VERSION ""

NS_ :

BS_:

BU_: VCM SCIM IC CCM

BO_ 179 SCIM_02P_C05: 8 SCIM
 SG_ FerryFunctionRequest_ISig_5 : 62|2@1+ (1,0) [0|0] ""  VCM
 SG_ KneelingChangeRequest_ISig_5 : 52|2@1+ (1,0) [0|0] ""  VCM
 SG_ LiftAxle1AutoLiftRequest_ISig_5 : 28|2@1+ (1,0) [0|0] ""  VCM
 SG_ FPBRChangeReq_ISig_5 : 58|2@1+ (1,0) [0|0] ""  VCM
 SG_ LightMode_Status_Ctr_1 : 4|4@1+ (1,0) [0|0] ""  VCM
 SG_ LevelRequest_RollRequest_ISig_5 : 22|3@1+ (1,0) [0|0] ""  VCM
 SG_ AltLoadDistribution_rqst_ISig_5 : 25|3@1+ (1,0) [0|0] ""  VCM
 SG_ LoadDistributionChangeRequest_IS : 60|2@1+ (1,0) [0|0] ""  VCM
 SG_ LiftAxle1LiftPositionRequest_ISi : 10|3@1+ (1,0) [0|0] ""  VCM
 SG_ ReverseWarning_rqst : 2|2@1+ (1,0) [0|0] ""  VCM
 SG_ FerryFunctionSwitchChangeReq_ISi : 54|2@1+ (1,0) [0|0] ""  VCM
 SG_ BackToDriveReq_ISig_5 : 56|2@1+ (1,0) [0|0] ""  VCM
 SG_ FogLightFront_ButtonStatus_1 : 0|2@1+ (1,0) [0|0] ""  VCM
 SG_ LevelRequest_RearAxle_ISig_5 : 19|3@1+ (1,0) [0|0] ""  VCM
 SG_ LiftAxle1DirectControl_ISig_5 : 37|3@1+ (1,0) [0|0] ""  VCM
 SG_ ECSStandByRequest_ISig_5 : 34|3@1+ (1,0) [0|0] ""  VCM
 SG_ LiftAxle2LiftPositionRequest_ISi : 13|3@1+ (1,0) [0|0] ""  VCM
 SG_ FogLightRear_ButtonStatus_1 : 8|2@1+ (1,0) [0|0] ""  VCM
 SG_ LevelStrokeRequest_ISig_5 : 32|2@1+ (1,0) [0|0] ""  VCM
 SG_ RampLevelRequest_ISig_5 : 40|4@1+ (1,0) [0|0] ""  VCM
 SG_ LevelRequest_FrontAxle_ISig_5 : 16|3@1+ (1,0) [0|0] ""  VCM
 SG_ LiftAxle2AutoLiftRequest_ISig_5 : 30|2@1+ (1,0) [0|0] ""  VCM
 SG_ RampLevelStorageRequest_ISig_5 : 44|4@1+ (1,0) [0|0] ""  VCM
 SG_ RideHeightStorageRequest_ISig_5 : 48|4@1+ (1,0) [0|0] ""  VCM

BO_ 2671833752 PhysDiagRespMsg_F2_98_C05: 8 CCM
 SG_ PhysDiagRespSig_F2_98_ISig_5 : 0|64@1+ (1,0) [0|0] ""  VCM

BO_ 2671833730 PhysDiagRespMsg_F2_82_C05: 8 IC
 SG_ PhysDiagRespSig_F2_82_ISig_5 : 0|64@1+ (1,0) [0|0] ""  VCM

BO_ 2671833700 PhysDiagRespMsg_F2_64_C05: 8 IC
 SG_ PhysDiagRespSig_F2_64_ISig_5 : 0|64@1+ (1,0) [0|0] ""  VCM

BO_ 2671833697 PhysDiagRespMsg_F2_61_C05: 8 IC
 SG_ PhysDiagRespSig_F2_61_ISig_5 : 0|64@1+ (1,0) [0|0] ""  VCM

BO_ 2671833664 PhysDiagRespMsg_F2_40_C05: 8 SCIM
 SG_ PhysDiagRespSig_F2_40_ISig_5 : 0|64@1+ (1,0) [0|0] ""  VCM

BO_ 2671810802 PhysDiagReqMsg_98_F2_C05: 8 VCM
 SG_ PhysDiagReqSig_98_F2_ISig_5 : 0|64@1+ (1,0) [0|0] ""  CCM

BO_ 2671805170 PhysDiagReqMsg_82_F2_C05: 8 VCM
 SG_ PhysDiagReqSig_82_F2_ISig_5 : 0|64@1+ (1,0) [0|0] ""  IC

BO_ 2671797490 PhysDiagReqMsg_64_F2_C05: 8 VCM
 SG_ PhysDiagReqSig_64_F2_ISig_5 : 0|64@1+ (1,0) [0|0] ""  IC

BO_ 2671796722 PhysDiagReqMsg_61_F2_C05: 8 VCM
 SG_ PhysDiagReqSig_61_F2_ISig_5 : 0|64@1+ (1,0) [0|0] ""  IC

BO_ 2671788274 PhysDiagReqMsg_40_F2_C05: 8 VCM
 SG_ PhysDiagReqSig_40_F2_ISig_5 : 0|64@1+ (1,0) [0|0] ""  SCIM

BO_ 2633990180 NmAsr_VCM_C05: 1 VCM

BO_ 2633990208 NmAsr_SCIM_C05: 1 SCIM

BO_ 2633990241 NmAsr_IC_C05: 1 IC

BO_ 2633990296 NmAsr_CCM_C05: 1 CCM

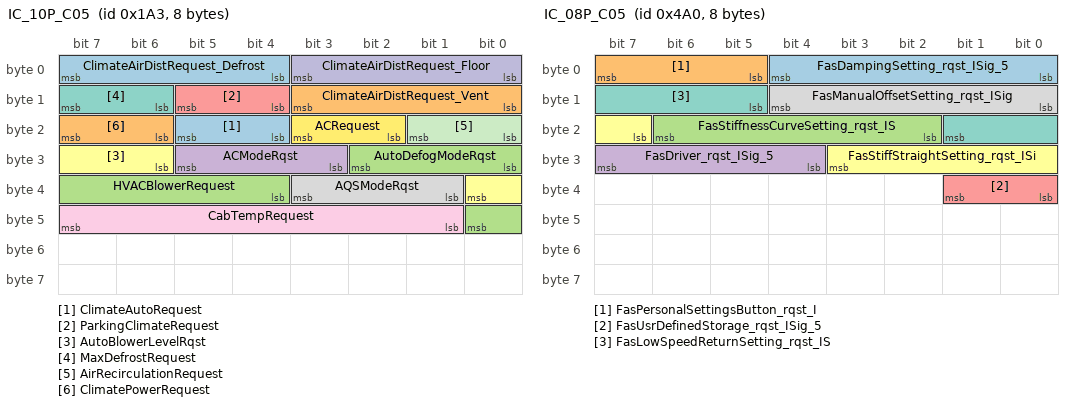
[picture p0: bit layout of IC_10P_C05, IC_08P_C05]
BO_ 419 IC_10P_C05: 8 IC
 SG_ ClimateAutoRequest : 20|2@1+ (1,0) [0|0] ""  CCM
 SG_ ClimateAirDistRequest_Vent : 8|4@1+ (1,0) [0|15] "NotApplicable"  CCM
 SG_ HVACBlowerRequest : 36|5@1+ (1,0) [0|31] "NotApplicable"  CCM
 SG_ ACModeRqst : 27|3@1+ (1,0) [0|0] ""  CCM
 SG_ ParkingClimateRequest : 12|2@1+ (1,0) [0|0] ""  CCM
 SG_ AutoBlowerLevelRqst : 30|3@1+ (1,0) [0|0] ""  CCM
 SG_ MaxDefrostRequest : 14|2@1+ (1,0) [0|0] ""  CCM
 SG_ AQSModeRqst : 33|3@1+ (1,0) [0|0] ""  CCM
 SG_ CabTempRequest : 41|7@1+ (0.5,0) [0|63.5] "DegreeC"  CCM
 SG_ ClimateAirDistRequest_Floor : 0|4@1+ (1,0) [0|15] "NotApplicable"  CCM
 SG_ AirRecirculationRequest : 16|2@1+ (1,0) [0|0] ""  CCM
 SG_ ACRequest : 18|2@1+ (1,0) [0|0] ""  CCM
 SG_ ClimateAirDistRequest_Defrost : 4|4@1+ (1,0) [0|15] "NotApplicable"  CCM
 SG_ ClimatePowerRequest : 22|2@1+ (1,0) [0|0] ""  CCM
 SG_ AutoDefogModeRqst : 24|3@1+ (1,0) [0|0] ""  CCM

BO_ 1457 IC_09S_C05_FCM: 8 VCM
 SG_ IC_09S_C05_FCS : 0|64@1+ (1,0) [0|0] ""  IC

BO_ 1456 IC_09S_C05: 11 IC
 SG_ ECU3VIN_stat : 0|88@1+ (1,0) [0|0] ""  VCM

BO_ 1184 IC_08P_C05: 8 IC
 SG_ FasDampingSetting_rqst_ISig_5 : 0|5@1+ (1,-10) [-10|21] ""  VCM
 SG_ FasPersonalSettingsButton_rqst_I : 5|3@1+ (1,0) [0|0] ""  VCM
 SG_ FasStiffnessCurveSetting_rqst_IS : 18|5@1+ (1,-10) [-10|21] ""  VCM
 SG_ FasDriver_rqst_ISig_5 : 28|4@1+ (1,0) [0|0] ""  VCM
 SG_ FasUsrDefinedStorage_rqst_ISig_5 : 32|2@1+ (1,0) [0|0] ""  VCM
 SG_ FasStiffStraightSetting_rqst_ISi : 23|5@1+ (1,-10) [-10|21] ""  VCM
 SG_ FasLowSpeedReturnSetting_rqst_IS : 13|5@1+ (1,-10) [-10|21] ""  VCM
 SG_ FasManualOffsetSetting_rqst_ISig : 8|5@1+ (1,-10) [-10|21] ""  VCM

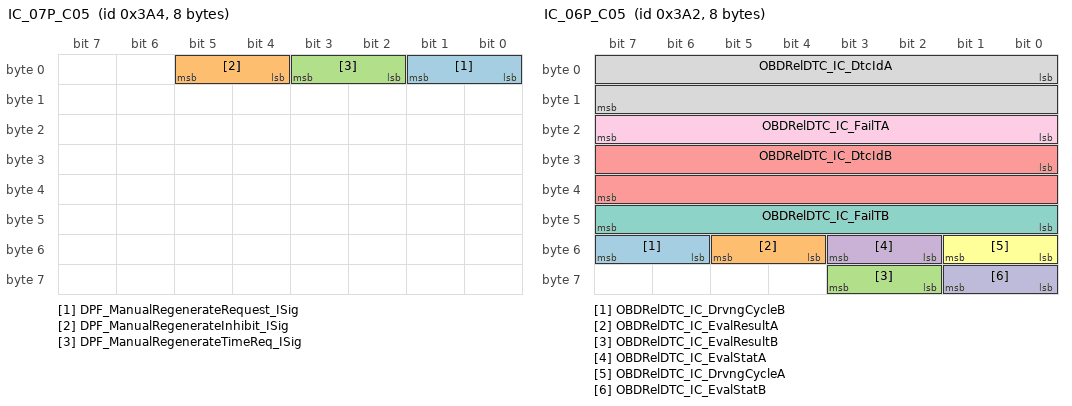
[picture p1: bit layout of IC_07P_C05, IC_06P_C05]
BO_ 932 IC_07P_C05: 8 IC
 SG_ DPF_ManualRegenerateRequest_ISig : 0|2@1+ (1,0) [0|0] ""  VCM
 SG_ DPF_ManualRegenerateInhibit_ISig : 4|2@1+ (1,0) [0|0] ""  VCM
 SG_ DPF_ManualRegenerateTimeReq_ISig : 2|2@1+ (1,0) [0|0] ""  VCM

BO_ 930 IC_06P_C05: 8 IC
 SG_ OBDRelDTC_IC_DrvngCycleB : 54|2@1+ (1,0) [0|0] ""  VCM
 SG_ OBDRelDTC_IC_EvalResultA : 52|2@1+ (1,0) [0|0] ""  VCM
 SG_ OBDRelDTC_IC_EvalResultB : 58|2@1+ (1,0) [0|0] ""  VCM
 SG_ OBDRelDTC_IC_EvalStatA : 50|2@1+ (1,0) [0|0] ""  VCM
 SG_ OBDRelDTC_IC_DtcIdB : 24|16@1+ (1,0) [0|65535] ""  VCM
 SG_ OBDRelDTC_IC_DrvngCycleA : 48|2@1+ (1,0) [0|0] ""  VCM
 SG_ OBDRelDTC_IC_FailTB : 40|8@1+ (1,0) [0|255] ""  VCM
 SG_ OBDRelDTC_IC_DtcIdA : 0|16@1+ (1,0) [0|65535] ""  VCM
 SG_ OBDRelDTC_IC_FailTA : 16|8@1+ (1,0) [0|255] ""  VCM
 SG_ OBDRelDTC_IC_EvalStatB : 56|2@1+ (1,0) [0|0] ""  VCM

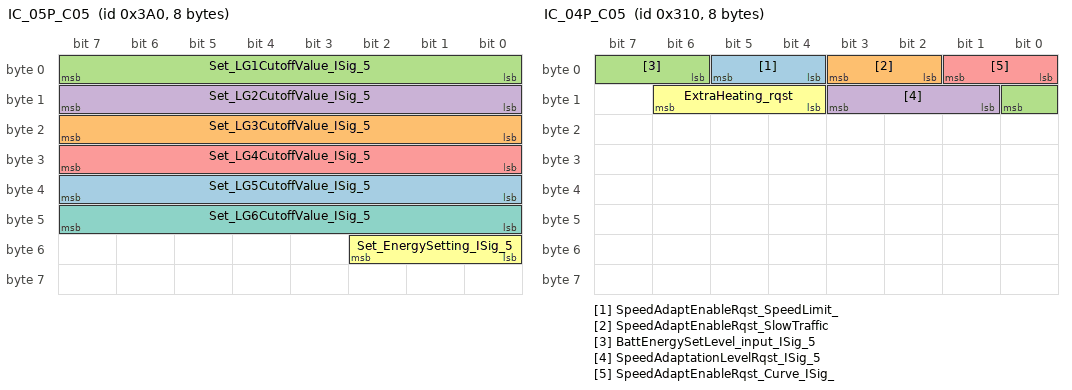
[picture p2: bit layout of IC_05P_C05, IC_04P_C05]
BO_ 928 IC_05P_C05: 8 IC
 SG_ Set_LG5CutoffValue_ISig_5 : 32|8@1+ (1,0) [0|255] "Percent"  VCM
 SG_ Set_LG3CutoffValue_ISig_5 : 16|8@1+ (1,0) [0|255] "Percent"  VCM
 SG_ Set_LG1CutoffValue_ISig_5 : 0|8@1+ (1,0) [0|255] "Percent"  VCM
 SG_ Set_LG2CutoffValue_ISig_5 : 8|8@1+ (1,0) [0|255] "Percent"  VCM
 SG_ Set_LG4CutoffValue_ISig_5 : 24|8@1+ (1,0) [0|255] "Percent"  VCM
 SG_ Set_EnergySetting_ISig_5 : 48|3@1+ (1,0) [0|0] ""  VCM
 SG_ Set_LG6CutoffValue_ISig_5 : 40|8@1+ (1,0) [0|255] "Percent"  VCM

BO_ 784 IC_04P_C05: 8 IC
 SG_ SpeedAdaptEnableRqst_SpeedLimit_ : 4|2@1+ (1,0) [0|0] ""  VCM
 SG_ SpeedAdaptEnableRqst_SlowTraffic : 2|2@1+ (1,0) [0|0] ""  VCM
 SG_ BattEnergySetLevel_input_ISig_5 : 6|3@1+ (1,0) [0|0] ""  VCM
 SG_ SpeedAdaptationLevelRqst_ISig_5 : 9|3@1+ (1,0) [0|0] ""  VCM
 SG_ SpeedAdaptEnableRqst_Curve_ISig_ : 0|2@1+ (1,0) [0|0] ""  VCM
 SG_ ExtraHeating_rqst : 12|3@1+ (1,0) [0|0] ""  CCM,VCM

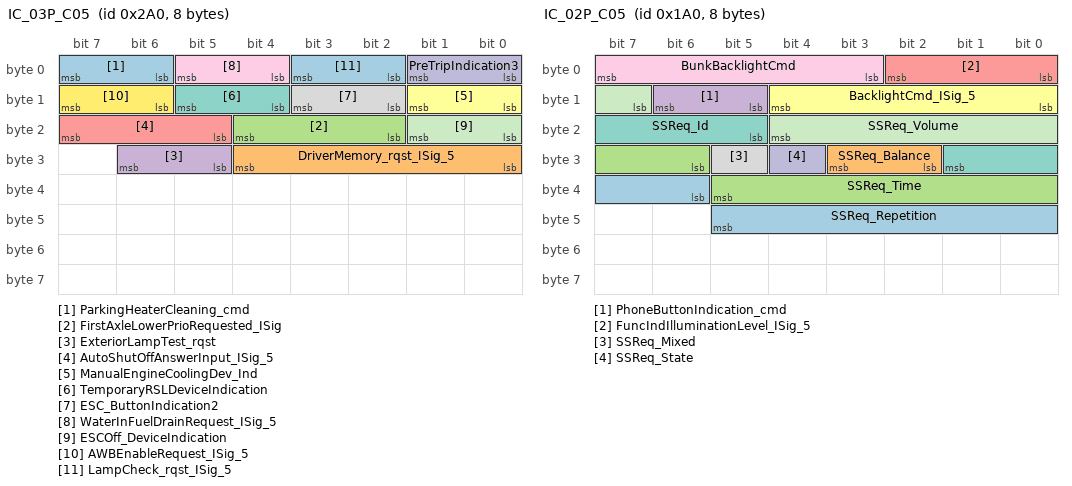
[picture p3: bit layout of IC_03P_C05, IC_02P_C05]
BO_ 672 IC_03P_C05: 8 IC
 SG_ ParkingHeaterCleaning_cmd : 6|2@1+ (1,0) [0|0] ""  VCM,CCM
 SG_ DriverMemory_rqst_ISig_5 : 24|5@1+ (1,0) [0|0] ""  CCM,VCM
 SG_ FirstAxleLowerPrioRequested_ISig : 18|3@1+ (1,0) [0|0] ""  VCM
 SG_ ExteriorLampTest_rqst : 29|2@1+ (1,0) [0|0] ""  VCM
 SG_ AutoShutOffAnswerInput_ISig_5 : 21|3@1+ (1,0) [0|0] ""  VCM
 SG_ ManualEngineCoolingDev_Ind : 8|2@1+ (1,0) [0|0] ""  VCM
 SG_ TemporaryRSLDeviceIndication : 12|2@1+ (1,0) [0|0] ""  VCM
 SG_ ESC_ButtonIndication2 : 10|2@1+ (1,0) [0|0] ""  VCM
 SG_ WaterInFuelDrainRequest_ISig_5 : 4|2@1+ (1,0) [0|0] ""  VCM
 SG_ PreTripIndication3 : 0|2@1+ (1,0) [0|0] ""  VCM
 SG_ ESCOff_DeviceIndication : 16|2@1+ (1,0) [0|0] ""  VCM
 SG_ AWBEnableRequest_ISig_5 : 14|2@1+ (1,0) [0|0] ""  VCM
 SG_ LampCheck_rqst_ISig_5 : 2|2@1+ (1,0) [0|0] ""  VCM

BO_ 416 IC_02P_C05: 8 IC
 SG_ SSReq_Repetition : 38|8@1+ (1,0) [0|255] ""  VCM
 SG_ SSReq_Balance : 26|2@1+ (1,0) [0|0] ""  VCM
 SG_ SSReq_Time : 30|8@1+ (0.1,0) [0|25.5] "s"  VCM
 SG_ PhoneButtonIndication_cmd : 13|2@1+ (1,0) [0|0] ""  VCM
 SG_ FuncIndIlluminationLevel_ISig_5 : 0|3@1+ (1,0) [0|0] ""  VCM
 SG_ BacklightCmd_ISig_5 : 8|5@1+ (1,0) [0|0] ""  VCM
 SG_ SSReq_Id : 21|5@1+ (1,0) [0|31] ""  VCM
 SG_ SSReq_Mixed : 29|1@1+ (1,0) [0|0] ""  VCM
 SG_ BunkBacklightCmd : 3|5@1+ (1,0) [0|0] ""  VCM
 SG_ SSReq_State : 28|1@1+ (1,0) [0|0] ""  VCM
 SG_ SSReq_Volume : 15|6@1+ (1,0) [0|63] ""  VCM

BO_ 211 IC_01P_C05: 8 IC
 SG_ TimeGapBtnStat : 30|2@1+ (1,0) [0|0] ""  VCM
 SG_ ATC_ButtonIndication : 10|2@1+ (1,0) [0|0] ""  VCM
 SG_ PauseOffBtnStat : 0|2@1+ (1,0) [0|0] ""  VCM
 SG_ ABS_ButtonIndication : 18|2@1+ (1,0) [0|0] ""  VCM
 SG_ SW_HeadlightInterrupt_Stat : 32|2@1+ (1,0) [0|0] ""  VCM
 SG_ PBAlertActiveStatus_ISig_5 : 34|3@1+ (1,0) [0|0] ""  VCM
 SG_ EcoRollEnableRequest_ISig_5 : 24|2@1+ (1,0) [0|0] ""  VCM
 SG_ EcoSettingsBtnStat : 22|2@1+ (1,0) [0|0] ""  VCM
 SG_ SkipNextBtnStat : 12|2@1+ (1,0) [0|0] ""  VCM
 SG_ GENSWS_PushButton_7_17_ISig_5 : 53|2@1+ (1,0) [0|0] ""  VCM
 SG_ TCS_ButtonIndication : 6|2@1+ (1,0) [0|0] ""  VCM
 SG_ DHCBtnStat : 16|2@1+ (1,0) [0|0] ""  VCM
 SG_ SW_PushToTalk_BtnStat_6_17_ISig_ : 49|2@1+ (1,0) [0|0] ""  VCM
 SG_ GENSWS_PushButton_7_3_ISig_5 : 51|2@1+ (1,0) [0|0] ""  VCM
 SG_ SWSpdCtrlButtonsStatus6 : 37|4@1+ (1,0) [0|0] ""  VCM
 SG_ PhoneBtnStat : 8|2@1+ (1,0) [0|0] ""  VCM
 SG_ SW_Home_ButtonsStatus_6 : 41|2@1+ (1,0) [0|0] ""  VCM
 SG_ SkipPrevBtnStat : 4|2@1+ (1,0) [0|0] ""  VCM
 SG_ ActivateBtnStat : 26|2@1+ (1,0) [0|0] ""  VCM
 SG_ ResIncrBtnStat : 2|2@1+ (1,0) [0|0] ""  VCM
 SG_ SrcBtnStat : 14|2@1+ (1,0) [0|0] ""  VCM
 SG_ SW_Mute_ButtonStatus_6_ISig_5 : 45|2@1+ (1,0) [0|0] ""  VCM
 SG_ SW_PushToTalk_BtnStat_6_ISig_5 : 43|2@1+ (1,0) [0|0] ""  VCM
 SG_ SetDecrBtnStat : 28|2@1+ (1,0) [0|0] ""  VCM
 SG_ SW_Mute_ButtonStatus_6_3_ISig_5 : 47|2@1+ (1,0) [0|0] ""  VCM
 SG_ MarkerInterruptButtonStatus : 20|2@1+ (1,0) [0|0] ""  VCM

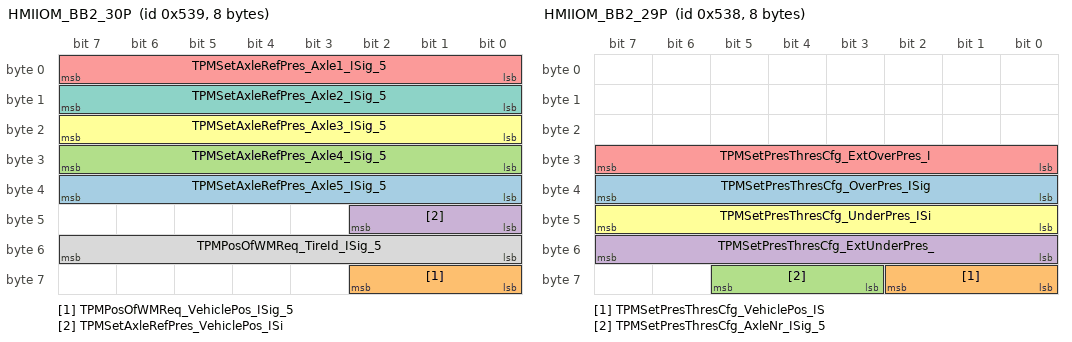
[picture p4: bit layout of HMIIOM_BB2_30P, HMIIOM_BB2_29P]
BO_ 1337 HMIIOM_BB2_30P: 8 IC
 SG_ TPMSetAxleRefPres_Axle5_ISig_5 : 32|8@1+ (10,0) [0|2550] "kPa"  VCM
 SG_ TPMPosOfWMReq_VehiclePos_ISig_5 : 56|3@1+ (1,0) [0|0] ""  VCM
 SG_ TPMSetAxleRefPres_Axle4_ISig_5 : 24|8@1+ (10,0) [0|2550] "kPa"  VCM
 SG_ TPMSetAxleRefPres_VehiclePos_ISi : 40|3@1+ (1,0) [0|0] ""  VCM
 SG_ TPMSetAxleRefPres_Axle1_ISig_5 : 0|8@1+ (10,0) [0|2550] "kPa"  VCM
 SG_ TPMSetAxleRefPres_Axle3_ISig_5 : 16|8@1+ (10,0) [0|2550] "kPa"  VCM
 SG_ TPMSetAxleRefPres_Axle2_ISig_5 : 8|8@1+ (10,0) [0|2550] "kPa"  VCM
 SG_ TPMPosOfWMReq_TireId_ISig_5 : 48|8@1+ (1,0) [0|255] "NotApplicable"  VCM

BO_ 1336 HMIIOM_BB2_29P: 8 IC
 SG_ TPMSetPresThresCfg_OverPres_ISig : 32|8@1+ (1,-125) [-125|130] "Percent"  VCM
 SG_ TPMSetPresThresCfg_VehiclePos_IS : 56|3@1+ (1,0) [0|0] ""  VCM
 SG_ TPMSetPresThresCfg_AxleNr_ISig_5 : 59|3@1+ (1,0) [0|0] ""  VCM
 SG_ TPMSetPresThresCfg_ExtUnderPres_ : 48|8@1+ (1,-125) [-125|130] "Percent"  VCM
 SG_ TPMSetPresThresCfg_ExtOverPres_I : 24|8@1+ (1,-125) [-125|130] "Percent"  VCM
 SG_ TPMSetPresThresCfg_UnderPres_ISi : 40|8@1+ (1,-125) [-125|130] "Percent"  VCM

BO_ 2671964824 DiagUUDTRespMsg1_F2_98_C05: 8 CCM
 SG_ DiagUUDTRespSig_F2_98_ISig_5 : 0|64@1+ (1,0) [0|0] ""  VCM

BO_ 2671964802 DiagUUDTRespMsg1_F2_82_C05: 8 IC
 SG_ DiagUUDTRespSig_F2_82_ISig_5 : 0|64@1+ (1,0) [0|0] ""  VCM

BO_ 2671964772 DiagUUDTRespMsg1_F2_64_C05: 8 IC
 SG_ DiagUUDTRespSig_F2_64_ISig_5 : 0|64@1+ (1,0) [0|0] ""  VCM

BO_ 2671964769 DiagUUDTRespMsg1_F2_61_C05: 8 IC
 SG_ DiagUUDTRespSig_F2_61_ISig_5 : 0|64@1+ (1,0) [0|0] ""  VCM

BO_ 2671964736 DiagUUDTRespMsg1_F2_40_C05: 8 SCIM
 SG_ DiagUUDTRespSig_F2_40_ISig_5 : 0|64@1+ (1,0) [0|0] ""  VCM

BO_ 2671834264 DiagRespMsgForIntTest_F4_98_C05: 8 CCM
 SG_ InternalTesterDiagSig_F4_98 : 0|64@1+ (1,0) [0|0] ""  VCM

BO_ 2671834242 DiagRespMsgForIntTest_F4_82_C05: 8 IC
 SG_ InternalTesterDiagSig_F4_82_ISig : 0|64@1+ (1,0) [0|0] ""  VCM

BO_ 2671834212 DiagRespMsgForIntTest_F4_64_C05: 8 IC
 SG_ InternalTesterDiagSig_F4_64 : 0|64@1+ (1,0) [0|0] ""  VCM

BO_ 2671834209 DiagRespMsgForIntTest_F4_61_C05: 8 IC
 SG_ InternalTesterDiagSig_F4_61 : 0|64@1+ (1,0) [0|0] ""  VCM

BO_ 2671834176 DiagRespMsgForIntTest_F4_40_C05: 8 SCIM
 SG_ InternalTesterDiagSig_F4_40 : 0|64@1+ (1,0) [0|0] ""  VCM

BO_ 2671810804 DiagReqMsgOfIntTest_98_F4_C05: 8 VCM
 SG_ InternalTesterDiagSig_98_F4 : 0|64@1+ (1,0) [0|0] ""  CCM

BO_ 2671805172 DiagReqMsgOfIntTest_82_F4_C05: 8 VCM
 SG_ InternalTesterDiagSig_82_F4_ISig : 0|64@1+ (1,0) [0|0] ""  IC

BO_ 2671797492 DiagReqMsgOfIntTest_64_F4_C05: 8 VCM
 SG_ InternalTesterDiagSig_64_F4 : 0|64@1+ (1,0) [0|0] ""  IC

BO_ 2671796724 DiagReqMsgOfIntTest_61_F4_C05: 8 VCM
 SG_ InternalTesterDiagSig_61_F4 : 0|64@1+ (1,0) [0|0] ""  IC

BO_ 2671788276 DiagReqMsgOfIntTest_40_F4_C05: 8 VCM
 SG_ InternalTesterDiagSig_40_F4 : 0|64@1+ (1,0) [0|0] ""  SCIM

BO_ 1976 Debug8_IC_C05: 8 IC
 SG_ Debug_8_IC : 0|64@1+ (1,0) [0|0] "" Vector__XXX

BO_ 1975 Debug7_IC_C05: 8 IC
 SG_ Debug_7_IC : 0|64@1+ (1,0) [0|0] "" Vector__XXX

BO_ 1966 Debug6_IC_C05: 8 IC
 SG_ Debug_6_IC : 0|64@1+ (1,0) [0|0] "" Vector__XXX

BO_ 1959 Debug5_IC_C05: 8 IC
 SG_ Debug_5_IC : 0|64@1+ (1,0) [0|0] "" Vector__XXX

BO_ 1952 Debug4_IC_C05: 8 IC
 SG_ Debug_4_IC : 0|64@1+ (1,0) [0|0] "" Vector__XXX

BO_ 1945 Debug3_IC_C05: 8 IC
 SG_ Debug_3_IC : 0|64@1+ (1,0) [0|0] "" Vector__XXX

BO_ 1938 Debug2_IC_C05: 8 IC
 SG_ Debug_2_IC : 0|64@1+ (1,0) [0|0] "" Vector__XXX

BO_ 1931 Debug1_IC_C05: 8 Vector__XXX
 SG_ Debug_1_IC : 0|64@1+ (1,0) [0|0] ""  IC

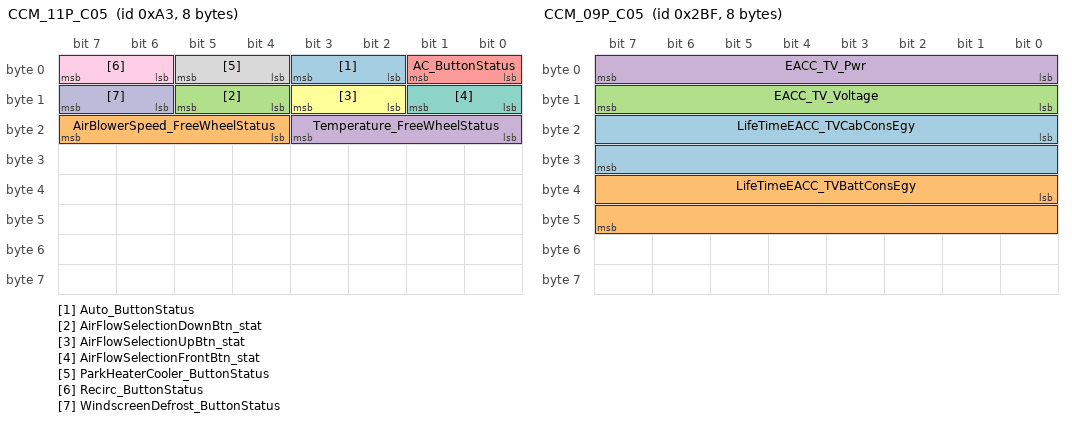
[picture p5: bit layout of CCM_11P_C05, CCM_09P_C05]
BO_ 163 CCM_11P_C05: 8 CCM
 SG_ Auto_ButtonStatus : 2|2@1+ (1,0) [0|0] ""  IC
 SG_ AirBlowerSpeed_FreeWheelStatus : 20|4@1+ (1,0) [0|0] ""  IC
 SG_ AirFlowSelectionDownBtn_stat : 12|2@1+ (1,0) [0|0] ""  IC
 SG_ Temperature_FreeWheelStatus : 16|4@1+ (1,0) [0|0] ""  IC
 SG_ AC_ButtonStatus : 0|2@1+ (1,0) [0|0] ""  IC
 SG_ AirFlowSelectionUpBtn_stat : 10|2@1+ (1,0) [0|0] ""  IC
 SG_ AirFlowSelectionFrontBtn_stat : 8|2@1+ (1,0) [0|0] ""  IC
 SG_ ParkHeaterCooler_ButtonStatus : 4|2@1+ (1,0) [0|0] ""  IC
 SG_ Recirc_ButtonStatus : 6|2@1+ (1,0) [0|0] ""  IC
 SG_ WindscreenDefrost_ButtonStatus : 14|2@1+ (1,0) [0|0] ""  IC

BO_ 1211 CCM_10P_C05: 8 CCM
 SG_ CabClimateFnRqst_FnPower : 0|8@1+ (1,0) [0|255] "Percent"  VCM
 SG_ CabClimateFnRqst_FnNum : 8|4@1+ (1,0) [0|15] "NotApplicable"  VCM

BO_ 703 CCM_09P_C05: 8 CCM
 SG_ LifeTimeEACC_TVCabConsEgy : 16|16@1+ (2.5,0) [0|163837.5] "Wh"  IC
 SG_ LifeTimeEACC_TVBattConsEgy : 32|16@1+ (2.5,0) [0|163837.5] "Wh"  IC
 SG_ EACC_TV_Voltage : 8|8@1+ (5,0) [0|1275] "V"  VCM
 SG_ EACC_TV_Pwr : 0|8@1+ (100,0) [0|25500] "W"  VCM

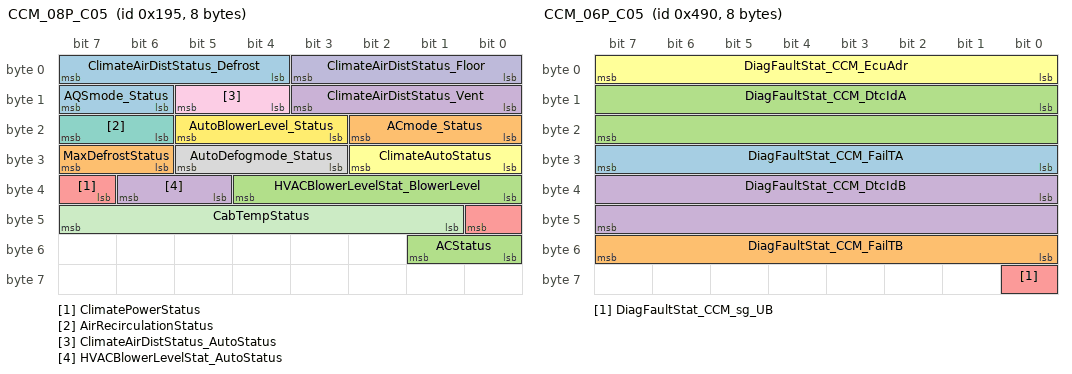
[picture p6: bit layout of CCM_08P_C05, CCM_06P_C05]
BO_ 405 CCM_08P_C05: 8 CCM
 SG_ ClimateAirDistStatus_Defrost : 4|4@1+ (1,0) [0|15] "NotApplicable"  IC
 SG_ ACmode_Status : 16|3@1+ (1,0) [0|0] ""  IC
 SG_ ACStatus : 48|2@1+ (1,0) [0|0] ""  IC
 SG_ ClimateAirDistStatus_Vent : 8|4@1+ (1,0) [0|15] "NotApplicable"  IC
 SG_ ClimatePowerStatus : 39|2@1+ (1,0) [0|0] ""  IC
 SG_ ClimateAutoStatus : 24|3@1+ (1,0) [0|0] ""  IC
 SG_ AirRecirculationStatus : 22|2@1+ (1,0) [0|0] ""  IC
 SG_ AutoDefogmode_Status : 27|3@1+ (1,0) [0|0] ""  IC
 SG_ ClimateAirDistStatus_AutoStatus : 12|2@1+ (1,0) [0|0] ""  IC
 SG_ ClimateAirDistStatus_Floor : 0|4@1+ (1,0) [0|15] "NotApplicable"  IC
 SG_ CabTempStatus : 41|7@1+ (0.5,0) [0|63.5] "DegreeC"  IC
 SG_ AutoBlowerLevel_Status : 19|3@1+ (1,0) [0|0] ""  IC
 SG_ AQSmode_Status : 14|2@1+ (1,0) [0|0] ""  IC
 SG_ MaxDefrostStatus : 30|2@1+ (1,0) [0|0] ""  IC
 SG_ HVACBlowerLevelStat_BlowerLevel : 32|5@1+ (1,0) [0|31] "NotApplicable"  IC
 SG_ HVACBlowerLevelStat_AutoStatus : 37|2@1+ (1,0) [0|0] ""  IC

BO_ 1168 CCM_06P_C05: 8 CCM
 SG_ DiagFaultStat_CCM_FailTA : 24|8@1+ (1,0) [0|255] ""  VCM
 SG_ DiagFaultStat_CCM_FailTB : 48|8@1+ (1,0) [0|255] ""  VCM
 SG_ DiagFaultStat_CCM_DtcIdA : 8|16@1+ (1,0) [0|65535] ""  VCM
 SG_ DiagFaultStat_CCM_DtcIdB : 32|16@1+ (1,0) [0|65535] ""  VCM
 SG_ DiagFaultStat_CCM_sg_UB : 56|1@1+ (1,0) [0|0] ""  VCM
 SG_ DiagFaultStat_CCM_EcuAdr : 0|8@1+ (1,0) [0|255] ""  VCM

BO_ 912 CCM_05P_C05: 8 CCM
 SG_ ParkingClimateAvailability : 13|3@1+ (1,0) [0|0] ""  IC
 SG_ CabTemperature_Status : 0|13@1+ (0.025,-40) [-40|164.775] "DegreeC"  VCM

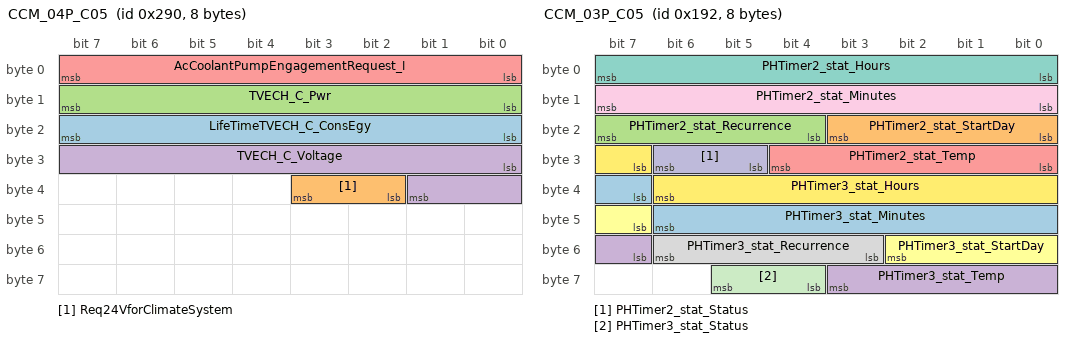
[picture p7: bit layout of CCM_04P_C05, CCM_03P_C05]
BO_ 656 CCM_04P_C05: 8 CCM
 SG_ LifeTimeTVECH_C_ConsEgy : 16|8@1+ (50,0) [0|12750] "Wh"  IC
 SG_ Req24VforClimateSystem : 34|2@1+ (1,0) [0|0] ""  VCM
 SG_ TVECH_C_Pwr : 8|8@1+ (100,0) [0|25500] "W"  VCM
 SG_ TVECH_C_Voltage : 24|10@1+ (1,0) [0|1023] "V"  VCM
 SG_ AcCoolantPumpEngagementRequest_I : 0|8@1+ (0.4,0) [0|102] "Percent"  VCM

BO_ 402 CCM_03P_C05: 8 CCM
 SG_ PHTimer3_stat_Minutes : 39|8@1+ (1,0) [0|255] "min"  VCM
 SG_ PHTimer2_stat_StartDay : 16|4@1+ (1,0) [0|0] ""  VCM
 SG_ PHTimer2_stat_Recurrence : 20|4@1+ (1,0) [0|0] ""  VCM
 SG_ PHTimer3_stat_Temp : 55|5@1+ (1,0) [0|0] ""  VCM
 SG_ PHTimer2_stat_Temp : 24|5@1+ (1,0) [0|0] ""  VCM
 SG_ PHTimer3_stat_StartDay : 47|4@1+ (1,0) [0|0] ""  VCM
 SG_ PHTimer2_stat_Hours : 0|8@1+ (1,0) [0|255] "h"  VCM
 SG_ PHTimer3_stat_Recurrence : 51|4@1+ (1,0) [0|0] ""  VCM
 SG_ PHTimer2_stat_Minutes : 8|8@1+ (1,0) [0|255] "min"  VCM
 SG_ PHTimer2_stat_Status : 29|2@1+ (1,0) [0|0] ""  VCM
 SG_ PHTimer3_stat_Status : 60|2@1+ (1,0) [0|0] ""  VCM
 SG_ PHTimer3_stat_Hours : 31|8@1+ (1,0) [0|255] "h"  VCM

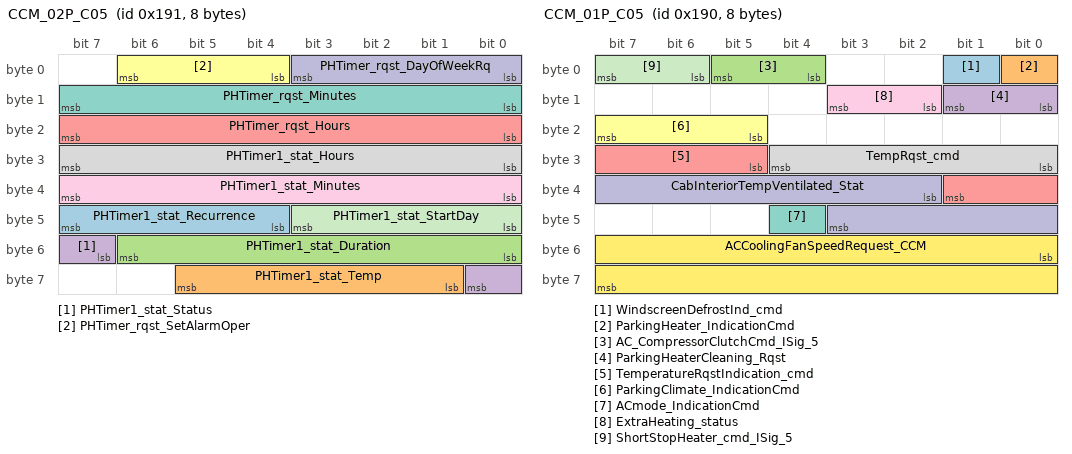
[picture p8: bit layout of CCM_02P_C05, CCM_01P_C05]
BO_ 401 CCM_02P_C05: 8 CCM
 SG_ PHTimer1_stat_Recurrence : 44|4@1+ (1,0) [0|0] ""  VCM
 SG_ PHTimer1_stat_Temp : 57|5@1+ (1,0) [0|0] ""  VCM
 SG_ PHTimer1_stat_Duration : 48|7@1+ (1,0) [0|127] "min"  VCM
 SG_ PHTimer1_stat_Status : 55|2@1+ (1,0) [0|0] ""  VCM
 SG_ PHTimer_rqst_Hours : 16|8@1+ (1,0) [0|255] "h"  VCM
 SG_ PHTimer_rqst_SetAlarmOper : 4|3@1+ (1,0) [0|0] ""  VCM
 SG_ PHTimer_rqst_Minutes : 8|8@1+ (1,0) [0|255] "min"  VCM
 SG_ PHTimer1_stat_Hours : 24|8@1+ (1,0) [0|255] "h"  VCM
 SG_ PHTimer1_stat_Minutes : 32|8@1+ (1,0) [0|255] "min"  VCM
 SG_ PHTimer_rqst_DayOfWeekRq : 0|4@1+ (1,0) [0|0] ""  VCM
 SG_ PHTimer1_stat_StartDay : 40|4@1+ (1,0) [0|0] ""  VCM

BO_ 400 CCM_01P_C05: 8 CCM
 SG_ WindscreenDefrostInd_cmd : 1|1@1+ (1,0) [0|0] ""  VCM
 SG_ ParkingHeater_IndicationCmd : 0|1@1+ (1,0) [0|0] ""  VCM
 SG_ AC_CompressorClutchCmd_ISig_5 : 4|2@1+ (1,0) [0|0] ""  VCM
 SG_ ParkingHeaterCleaning_Rqst : 8|2@1+ (1,0) [0|0] ""  IC,VCM
 SG_ TemperatureRqstIndication_cmd : 29|5@1+ (1,0) [0|0] ""  IC,VCM
 SG_ ParkingClimate_IndicationCmd : 21|3@1+ (1,0) [0|0] ""  VCM,IC
 SG_ ACmode_IndicationCmd : 44|1@1+ (1,0) [0|0] ""  VCM
 SG_ TempRqst_cmd : 24|5@1+ (1,0) [0|0] ""  VCM
 SG_ ExtraHeating_status : 10|2@1+ (1,0) [0|0] ""  IC,VCM
 SG_ CabInteriorTempVentilated_Stat : 34|10@1+ (0.125,-40) [-40|87.875] "DegreeC"  VCM
 SG_ ShortStopHeater_cmd_ISig_5 : 6|2@1+ (1,0) [0|0] ""  VCM
 SG_ ACCoolingFanSpeedRequest_CCM : 48|16@1+ (1,0) [0|65535] "rpm"  VCM

BO_ 1717 AnmMsg_VCM_C05: 8 VCM
 SG_ AnmSig_VCM_CAN05 : 0|32@1+ (1,0) [0|0] ""  IC,CCM,SCIM

BO_ 1718 AnmMsg_SCIM_C05: 8 SCIM
 SG_ AnmSig_SCIM_CAN05 : 0|32@1+ (1,0) [0|0] ""  CCM,VCM,IC

BO_ 1716 AnmMsg_IC_C05: 8 IC
 SG_ AnmSig_IC_CAN05 : 0|32@1+ (1,0) [0|0] ""  SCIM,CCM,VCM

BO_ 1719 AnmMsg_CCM_C05: 8 CCM
 SG_ AnmSig_CCM_CAN05 : 0|32@1+ (1,0) [0|0] ""  VCM,SCIM,IC

CM_ SG_ 401 PHTimer_rqst_Hours "254 Error ; 255 Not available";
CM_ SG_ 401 PHTimer_rqst_Minutes "254 Error ; 255 Not available";
BA_DEF_ BO_  "GenMsgStartDelayTime" INT 0 0;
BA_DEF_ BO_  "GenMsgDelayTime" INT 0 0;
BA_DEF_ BO_  "GenMsgCycleTime" INT 0 0;
BA_DEF_ BO_  "GenMsgSendType" ENUM  "Cyclic","NotUsed","NotUsed","NotUsed","NotUsed","NotUsed","NotUsed","IfActive","NoMsgSendType","NotUsed";
BA_DEF_ SG_  "GenSigStartValue" INT 0 0;
BA_DEF_ SG_  "GenSigCycleTimeActive" INT 0 0;
BA_DEF_ SG_  "GenSigCycleTime" INT 0 0;
BA_DEF_ SG_  "GenSigSendType" ENUM  "Cyclic","OnWrite","OnWriteWithRepetition","OnChange","OnChangeWithRepetition","IfActive","IfActiveWithRepetition","NoSigSendType","NotUsed","NotUsed","NotUsed","NotUsed","NotUsed";
BA_DEF_ BO_  "VFrameFormat" ENUM  "StandardCAN","ExtendedCAN","reserved","J1939PG","reserved","reserved","reserved","reserved","reserved","reserved","reserved","reserved","reserved","reserved","StandardCAN_FD","ExtendedCAN_FD";
BA_DEF_ SG_  "SigType" ENUM  "Default","Range","RangeSigned","ASCII","Discrete","Control","ReferencePGN","DTC","StringDelimiter","StringLength","StringLengthControl";
BA_DEF_ BO_  "NmAsrMessage" ENUM  "No","Yes";
BA_DEF_ SG_  "NeedsUpdateBit" ENUM  "No","Yes";
BA_DEF_ SG_  "MmAnSignal" ENUM  "No","Yes";
BA_DEF_ SG_  "GenSigMaxLatency" INT 0 65535;
BA_DEF_ SG_  "GenSigILSupport" ENUM  "Yes","No";
BA_DEF_ BO_  "GenMsgILSupport" ENUM  "No","Yes";
BA_DEF_ SG_  "E2EProfile" STRING ;
BA_DEF_ SG_  "E2EDataLength" INT 0 65535;
BA_DEF_ SG_  "E2EDataId" INT 0 65535;
BA_DEF_ BO_  "DiagUUDTResponse" ENUM  "No","Yes";
BA_DEF_ BO_  "DiagState" ENUM  "No","Yes";
BA_DEF_ BO_  "DiagResponse" ENUM  "No","Yes";
BA_DEF_ BO_  "DiagRequest" ENUM  "No","Yes";
BA_DEF_ BO_  "DiagConnection" HEX 0 65535;
BA_DEF_ BO_  "CanTpFcFrameId" HEX 0 2147483647;
BA_DEF_ BO_  "CanTpBs" INT 0 255;
BA_DEF_ SG_  "SystemSignalLongSymbol" STRING ;
BA_DEF_REL_ BU_SG_REL_  "GenSigTimeoutTime" INT 0 65535;
BA_DEF_REL_ BU_SG_REL_  "GenSigFirstTimeoutTime" INT 0 65535;
BA_DEF_DEF_  "GenMsgStartDelayTime" 0;
BA_DEF_DEF_  "GenMsgDelayTime" 0;
BA_DEF_DEF_  "GenMsgCycleTime" 0;
BA_DEF_DEF_  "GenMsgSendType" "Cyclic";
BA_DEF_DEF_  "GenSigStartValue" 0;
BA_DEF_DEF_  "GenSigCycleTimeActive" 0;
BA_DEF_DEF_  "GenSigCycleTime" 0;
BA_DEF_DEF_  "GenSigSendType" "Cyclic";
BA_DEF_DEF_  "VFrameFormat" "ExtendedCAN";
BA_DEF_DEF_  "SigType" "Default";
BA_DEF_DEF_  "NmAsrMessage" "No";
BA_DEF_DEF_  "NeedsUpdateBit" "No";
BA_DEF_DEF_  "MmAnSignal" "No";
BA_DEF_DEF_  "GenSigMaxLatency" 0;
BA_DEF_DEF_  "GenSigILSupport" "Yes";
BA_DEF_DEF_  "GenMsgILSupport" "Yes";
BA_DEF_DEF_  "E2EProfile" "none";
BA_DEF_DEF_  "E2EDataLength" 0;
BA_DEF_DEF_  "E2EDataId" 0;
BA_DEF_DEF_  "DiagUUDTResponse" "No";
BA_DEF_DEF_  "DiagState" "No";
BA_DEF_DEF_  "DiagResponse" "No";
BA_DEF_DEF_  "DiagRequest" "No";
BA_DEF_DEF_  "DiagConnection" 0;
BA_DEF_DEF_  "CanTpFcFrameId" 2147483647;
BA_DEF_DEF_  "CanTpBs" 255;
BA_DEF_DEF_REL_ "GenSigTimeoutTime" 0;
BA_DEF_DEF_REL_ "GenSigFirstTimeoutTime" 0;
BA_DEF_DEF_  "SystemSignalLongSymbol" "";
BA_ "VFrameFormat" BO_ 179 0;
BA_ "GenMsgCycleTime" BO_ 179 20;
BA_ "GenMsgStartDelayTime" BO_ 179 5;
BA_ "DiagConnection" BO_ 2671833752 62104;
BA_ "DiagResponse" BO_ 2671833752 1;
BA_ "GenMsgILSupport" BO_ 2671833752 0;
BA_ "GenMsgSendType" BO_ 2671833752 8;
BA_ "DiagConnection" BO_ 2671833730 62082;
BA_ "DiagResponse" BO_ 2671833730 1;
BA_ "GenMsgILSupport" BO_ 2671833730 0;
BA_ "GenMsgSendType" BO_ 2671833730 8;
BA_ "DiagConnection" BO_ 2671833700 62052;
BA_ "DiagResponse" BO_ 2671833700 1;
BA_ "GenMsgILSupport" BO_ 2671833700 0;
BA_ "GenMsgSendType" BO_ 2671833700 8;
BA_ "DiagConnection" BO_ 2671833697 62049;
BA_ "DiagResponse" BO_ 2671833697 1;
BA_ "GenMsgILSupport" BO_ 2671833697 0;
BA_ "GenMsgSendType" BO_ 2671833697 8;
BA_ "DiagConnection" BO_ 2671833664 62016;
BA_ "DiagResponse" BO_ 2671833664 1;
BA_ "GenMsgILSupport" BO_ 2671833664 0;
BA_ "GenMsgSendType" BO_ 2671833664 8;
BA_ "DiagConnection" BO_ 2671810802 62104;
BA_ "DiagRequest" BO_ 2671810802 1;
BA_ "GenMsgILSupport" BO_ 2671810802 0;
BA_ "GenMsgSendType" BO_ 2671810802 8;
BA_ "DiagConnection" BO_ 2671805170 62082;
BA_ "DiagRequest" BO_ 2671805170 1;
BA_ "GenMsgILSupport" BO_ 2671805170 0;
BA_ "GenMsgSendType" BO_ 2671805170 8;
BA_ "DiagConnection" BO_ 2671797490 62052;
BA_ "DiagRequest" BO_ 2671797490 1;
BA_ "GenMsgILSupport" BO_ 2671797490 0;
BA_ "GenMsgSendType" BO_ 2671797490 8;
BA_ "DiagConnection" BO_ 2671796722 62049;
BA_ "DiagRequest" BO_ 2671796722 1;
BA_ "GenMsgILSupport" BO_ 2671796722 0;
BA_ "GenMsgSendType" BO_ 2671796722 8;
BA_ "DiagConnection" BO_ 2671788274 62016;
BA_ "DiagRequest" BO_ 2671788274 1;
BA_ "GenMsgILSupport" BO_ 2671788274 0;
BA_ "GenMsgSendType" BO_ 2671788274 8;
BA_ "GenMsgILSupport" BO_ 2633990180 0;
BA_ "NmAsrMessage" BO_ 2633990180 1;
BA_ "GenMsgSendType" BO_ 2633990180 8;
BA_ "GenMsgILSupport" BO_ 2633990208 0;
BA_ "NmAsrMessage" BO_ 2633990208 1;
BA_ "GenMsgSendType" BO_ 2633990208 8;
BA_ "GenMsgILSupport" BO_ 2633990241 0;
BA_ "NmAsrMessage" BO_ 2633990241 1;
BA_ "GenMsgSendType" BO_ 2633990241 8;
BA_ "GenMsgILSupport" BO_ 2633990296 0;
BA_ "NmAsrMessage" BO_ 2633990296 1;
BA_ "GenMsgSendType" BO_ 2633990296 8;
BA_ "VFrameFormat" BO_ 419 0;
BA_ "GenMsgCycleTime" BO_ 419 50;
BA_ "GenMsgStartDelayTime" BO_ 419 30;
BA_ "GenMsgILSupport" BO_ 1457 0;
BA_ "VFrameFormat" BO_ 1457 0;
BA_ "GenMsgSendType" BO_ 1457 8;
BA_ "CanTpFcFrameId" BO_ 1456 1457;
BA_ "VFrameFormat" BO_ 1456 0;
BA_ "GenMsgSendType" BO_ 1456 8;
BA_ "GenMsgDelayTime" BO_ 1456 1000;
BA_ "VFrameFormat" BO_ 1184 0;
BA_ "GenMsgCycleTime" BO_ 1184 1000;
BA_ "GenMsgStartDelayTime" BO_ 1184 10;
BA_ "VFrameFormat" BO_ 932 0;
BA_ "GenMsgCycleTime" BO_ 932 500;
BA_ "GenMsgStartDelayTime" BO_ 932 180;
BA_ "VFrameFormat" BO_ 930 0;
BA_ "GenMsgCycleTime" BO_ 930 500;
BA_ "GenMsgStartDelayTime" BO_ 930 135;
BA_ "VFrameFormat" BO_ 928 0;
BA_ "GenMsgCycleTime" BO_ 928 500;
BA_ "GenMsgStartDelayTime" BO_ 928 20;
BA_ "VFrameFormat" BO_ 784 0;
BA_ "GenMsgCycleTime" BO_ 784 200;
BA_ "GenMsgStartDelayTime" BO_ 784 50;
BA_ "VFrameFormat" BO_ 672 0;
BA_ "GenMsgCycleTime" BO_ 672 100;
BA_ "GenMsgStartDelayTime" BO_ 672 15;
BA_ "VFrameFormat" BO_ 416 0;
BA_ "GenMsgCycleTime" BO_ 416 50;
BA_ "GenMsgStartDelayTime" BO_ 416 5;
BA_ "VFrameFormat" BO_ 211 0;
BA_ "GenMsgCycleTime" BO_ 211 20;
BA_ "VFrameFormat" BO_ 1337 0;
BA_ "GenMsgCycleTime" BO_ 1337 500;
BA_ "GenMsgStartDelayTime" BO_ 1337 285;
BA_ "VFrameFormat" BO_ 1336 0;
BA_ "GenMsgCycleTime" BO_ 1336 500;
BA_ "GenMsgStartDelayTime" BO_ 1336 100;
BA_ "DiagConnection" BO_ 2671964824 62104;
BA_ "DiagUUDTResponse" BO_ 2671964824 1;
BA_ "GenMsgILSupport" BO_ 2671964824 0;
BA_ "GenMsgSendType" BO_ 2671964824 8;
BA_ "DiagConnection" BO_ 2671964802 62082;
BA_ "DiagUUDTResponse" BO_ 2671964802 1;
BA_ "GenMsgILSupport" BO_ 2671964802 0;
BA_ "GenMsgSendType" BO_ 2671964802 8;
BA_ "DiagConnection" BO_ 2671964772 62052;
BA_ "DiagUUDTResponse" BO_ 2671964772 1;
BA_ "GenMsgILSupport" BO_ 2671964772 0;
BA_ "GenMsgSendType" BO_ 2671964772 8;
BA_ "DiagConnection" BO_ 2671964769 62049;
BA_ "DiagUUDTResponse" BO_ 2671964769 1;
BA_ "GenMsgILSupport" BO_ 2671964769 0;
BA_ "GenMsgSendType" BO_ 2671964769 8;
BA_ "DiagConnection" BO_ 2671964736 62016;
BA_ "DiagUUDTResponse" BO_ 2671964736 1;
BA_ "GenMsgILSupport" BO_ 2671964736 0;
BA_ "GenMsgSendType" BO_ 2671964736 8;
BA_ "DiagConnection" BO_ 2671834264 62616;
BA_ "DiagResponse" BO_ 2671834264 1;
BA_ "GenMsgILSupport" BO_ 2671834264 0;
BA_ "GenMsgSendType" BO_ 2671834264 8;
BA_ "DiagConnection" BO_ 2671834242 62594;
BA_ "DiagResponse" BO_ 2671834242 1;
BA_ "GenMsgILSupport" BO_ 2671834242 0;
BA_ "GenMsgSendType" BO_ 2671834242 8;
BA_ "DiagConnection" BO_ 2671834212 62564;
BA_ "DiagResponse" BO_ 2671834212 1;
BA_ "GenMsgILSupport" BO_ 2671834212 0;
BA_ "GenMsgSendType" BO_ 2671834212 8;
BA_ "DiagConnection" BO_ 2671834209 62561;
BA_ "DiagResponse" BO_ 2671834209 1;
BA_ "GenMsgILSupport" BO_ 2671834209 0;
BA_ "GenMsgSendType" BO_ 2671834209 8;
BA_ "DiagConnection" BO_ 2671834176 62528;
BA_ "DiagResponse" BO_ 2671834176 1;
BA_ "GenMsgILSupport" BO_ 2671834176 0;
BA_ "GenMsgSendType" BO_ 2671834176 8;
BA_ "DiagConnection" BO_ 2671810804 62616;
BA_ "DiagRequest" BO_ 2671810804 1;
BA_ "GenMsgILSupport" BO_ 2671810804 0;
BA_ "GenMsgSendType" BO_ 2671810804 8;
BA_ "DiagConnection" BO_ 2671805172 62594;
BA_ "DiagRequest" BO_ 2671805172 1;
BA_ "GenMsgILSupport" BO_ 2671805172 0;
BA_ "GenMsgSendType" BO_ 2671805172 8;
BA_ "DiagConnection" BO_ 2671797492 62564;
BA_ "DiagRequest" BO_ 2671797492 1;
BA_ "GenMsgILSupport" BO_ 2671797492 0;
BA_ "GenMsgSendType" BO_ 2671797492 8;
BA_ "DiagConnection" BO_ 2671796724 62561;
BA_ "DiagRequest" BO_ 2671796724 1;
BA_ "GenMsgILSupport" BO_ 2671796724 0;
BA_ "GenMsgSendType" BO_ 2671796724 8;
BA_ "DiagConnection" BO_ 2671788276 62528;
BA_ "DiagRequest" BO_ 2671788276 1;
BA_ "GenMsgILSupport" BO_ 2671788276 0;
BA_ "GenMsgSendType" BO_ 2671788276 8;
BA_ "VFrameFormat" BO_ 1976 0;
BA_ "GenMsgSendType" BO_ 1976 8;
BA_ "VFrameFormat" BO_ 1975 0;
BA_ "GenMsgSendType" BO_ 1975 8;
BA_ "VFrameFormat" BO_ 1966 0;
BA_ "GenMsgSendType" BO_ 1966 8;
BA_ "GenMsgDelayTime" BO_ 1966 40;
BA_ "GenMsgStartDelayTime" BO_ 1966 50;
BA_ "VFrameFormat" BO_ 1959 0;
BA_ "GenMsgSendType" BO_ 1959 8;
BA_ "GenMsgDelayTime" BO_ 1959 40;
BA_ "GenMsgStartDelayTime" BO_ 1959 50;
BA_ "VFrameFormat" BO_ 1952 0;
BA_ "GenMsgSendType" BO_ 1952 8;
BA_ "GenMsgDelayTime" BO_ 1952 40;
BA_ "GenMsgStartDelayTime" BO_ 1952 50;
BA_ "VFrameFormat" BO_ 1945 0;
BA_ "GenMsgSendType" BO_ 1945 8;
BA_ "GenMsgDelayTime" BO_ 1945 40;
BA_ "GenMsgStartDelayTime" BO_ 1945 50;
BA_ "VFrameFormat" BO_ 1938 0;
BA_ "GenMsgSendType" BO_ 1938 8;
BA_ "GenMsgDelayTime" BO_ 1938 40;
BA_ "GenMsgStartDelayTime" BO_ 1938 50;
BA_ "VFrameFormat" BO_ 1931 0;
BA_ "VFrameFormat" BO_ 163 0;
BA_ "GenMsgCycleTime" BO_ 163 20;
BA_ "VFrameFormat" BO_ 1211 0;
BA_ "GenMsgCycleTime" BO_ 1211 1000;
BA_ "GenMsgStartDelayTime" BO_ 1211 270;
BA_ "VFrameFormat" BO_ 703 0;
BA_ "GenMsgCycleTime" BO_ 703 100;
BA_ "GenMsgStartDelayTime" BO_ 703 65;
BA_ "VFrameFormat" BO_ 405 0;
BA_ "GenMsgCycleTime" BO_ 405 50;
BA_ "GenMsgStartDelayTime" BO_ 405 35;
BA_ "VFrameFormat" BO_ 1168 0;
BA_ "GenMsgCycleTime" BO_ 1168 1000;
BA_ "GenMsgDelayTime" BO_ 1168 80;
BA_ "GenMsgStartDelayTime" BO_ 1168 130;
BA_ "VFrameFormat" BO_ 912 0;
BA_ "GenMsgCycleTime" BO_ 912 500;
BA_ "GenMsgStartDelayTime" BO_ 912 75;
BA_ "VFrameFormat" BO_ 656 0;
BA_ "GenMsgCycleTime" BO_ 656 100;
BA_ "GenMsgStartDelayTime" BO_ 656 20;
BA_ "VFrameFormat" BO_ 402 0;
BA_ "GenMsgCycleTime" BO_ 402 50;
BA_ "GenMsgStartDelayTime" BO_ 402 25;
BA_ "VFrameFormat" BO_ 401 0;
BA_ "GenMsgCycleTime" BO_ 401 50;
BA_ "GenMsgStartDelayTime" BO_ 401 15;
BA_ "VFrameFormat" BO_ 400 0;
BA_ "GenMsgCycleTime" BO_ 400 50;
BA_ "GenMsgStartDelayTime" BO_ 400 5;
BA_ "VFrameFormat" BO_ 1717 0;
BA_ "GenMsgCycleTime" BO_ 1717 100;
BA_ "VFrameFormat" BO_ 1718 0;
BA_ "GenMsgCycleTime" BO_ 1718 100;
BA_ "VFrameFormat" BO_ 1716 0;
BA_ "GenMsgCycleTime" BO_ 1716 100;
BA_ "VFrameFormat" BO_ 1719 0;
BA_ "GenMsgCycleTime" BO_ 1719 100;
BA_ "GenSigCycleTime" SG_ 179 FerryFunctionRequest_ISig_5 100;
BA_ "GenSigCycleTimeActive" SG_ 179 FerryFunctionRequest_ISig_5 100;
BA_ "GenSigStartValue" SG_ 179 FerryFunctionRequest_ISig_5 3;
BA_ "GenSigMaxLatency" SG_ 179 FerryFunctionRequest_ISig_5 20;
BA_ "GenSigCycleTime" SG_ 179 KneelingChangeRequest_ISig_5 100;
BA_ "GenSigCycleTimeActive" SG_ 179 KneelingChangeRequest_ISig_5 100;
BA_ "GenSigStartValue" SG_ 179 KneelingChangeRequest_ISig_5 3;
BA_ "GenSigMaxLatency" SG_ 179 KneelingChangeRequest_ISig_5 20;
BA_ "GenSigCycleTime" SG_ 179 LiftAxle1AutoLiftRequest_ISig_5 100;
BA_ "GenSigCycleTimeActive" SG_ 179 LiftAxle1AutoLiftRequest_ISig_5 100;
BA_ "GenSigStartValue" SG_ 179 LiftAxle1AutoLiftRequest_ISig_5 3;
BA_ "GenSigMaxLatency" SG_ 179 LiftAxle1AutoLiftRequest_ISig_5 20;
BA_ "GenSigCycleTime" SG_ 179 FPBRChangeReq_ISig_5 100;
BA_ "GenSigCycleTimeActive" SG_ 179 FPBRChangeReq_ISig_5 100;
BA_ "GenSigStartValue" SG_ 179 FPBRChangeReq_ISig_5 3;
BA_ "GenSigMaxLatency" SG_ 179 FPBRChangeReq_ISig_5 20;
BA_ "GenSigCycleTime" SG_ 179 LightMode_Status_Ctr_1 100;
BA_ "GenSigCycleTimeActive" SG_ 179 LightMode_Status_Ctr_1 100;
BA_ "GenSigStartValue" SG_ 179 LightMode_Status_Ctr_1 15;
BA_ "GenSigMaxLatency" SG_ 179 LightMode_Status_Ctr_1 20;
BA_ "GenSigCycleTime" SG_ 179 LevelRequest_RollRequest_ISig_5 100;
BA_ "GenSigCycleTimeActive" SG_ 179 LevelRequest_RollRequest_ISig_5 100;
BA_ "GenSigStartValue" SG_ 179 LevelRequest_RollRequest_ISig_5 7;
BA_ "GenSigMaxLatency" SG_ 179 LevelRequest_RollRequest_ISig_5 20;
BA_ "GenSigCycleTime" SG_ 179 AltLoadDistribution_rqst_ISig_5 100;
BA_ "GenSigCycleTimeActive" SG_ 179 AltLoadDistribution_rqst_ISig_5 100;
BA_ "GenSigStartValue" SG_ 179 AltLoadDistribution_rqst_ISig_5 7;
BA_ "GenSigMaxLatency" SG_ 179 AltLoadDistribution_rqst_ISig_5 20;
BA_ "GenSigCycleTime" SG_ 179 LoadDistributionChangeRequest_IS 100;
BA_ "GenSigCycleTimeActive" SG_ 179 LoadDistributionChangeRequest_IS 100;
BA_ "GenSigStartValue" SG_ 179 LoadDistributionChangeRequest_IS 3;
BA_ "GenSigMaxLatency" SG_ 179 LoadDistributionChangeRequest_IS 20;
BA_ "SystemSignalLongSymbol" SG_ 179 LoadDistributionChangeRequest_IS "LoadDistributionChangeRequest_ISig_5";
BA_ "GenSigCycleTime" SG_ 179 LiftAxle1LiftPositionRequest_ISi 100;
BA_ "GenSigCycleTimeActive" SG_ 179 LiftAxle1LiftPositionRequest_ISi 100;
BA_ "GenSigStartValue" SG_ 179 LiftAxle1LiftPositionRequest_ISi 7;
BA_ "GenSigMaxLatency" SG_ 179 LiftAxle1LiftPositionRequest_ISi 20;
BA_ "SystemSignalLongSymbol" SG_ 179 LiftAxle1LiftPositionRequest_ISi "LiftAxle1LiftPositionRequest_ISig_5";
BA_ "GenSigCycleTime" SG_ 179 ReverseWarning_rqst 100;
BA_ "GenSigCycleTimeActive" SG_ 179 ReverseWarning_rqst 100;
BA_ "GenSigStartValue" SG_ 179 ReverseWarning_rqst 3;
BA_ "GenSigMaxLatency" SG_ 179 ReverseWarning_rqst 20;
BA_ "GenSigCycleTime" SG_ 179 FerryFunctionSwitchChangeReq_ISi 100;
BA_ "GenSigCycleTimeActive" SG_ 179 FerryFunctionSwitchChangeReq_ISi 100;
BA_ "GenSigStartValue" SG_ 179 FerryFunctionSwitchChangeReq_ISi 3;
BA_ "GenSigMaxLatency" SG_ 179 FerryFunctionSwitchChangeReq_ISi 20;
BA_ "SystemSignalLongSymbol" SG_ 179 FerryFunctionSwitchChangeReq_ISi "FerryFunctionSwitchChangeReq_ISig_5";
BA_ "GenSigCycleTime" SG_ 179 BackToDriveReq_ISig_5 100;
BA_ "GenSigCycleTimeActive" SG_ 179 BackToDriveReq_ISig_5 100;
BA_ "GenSigStartValue" SG_ 179 BackToDriveReq_ISig_5 3;
BA_ "GenSigMaxLatency" SG_ 179 BackToDriveReq_ISig_5 20;
BA_ "GenSigCycleTime" SG_ 179 FogLightFront_ButtonStatus_1 100;
BA_ "GenSigCycleTimeActive" SG_ 179 FogLightFront_ButtonStatus_1 100;
BA_ "GenSigStartValue" SG_ 179 FogLightFront_ButtonStatus_1 3;
BA_ "GenSigMaxLatency" SG_ 179 FogLightFront_ButtonStatus_1 20;
BA_ "GenSigCycleTime" SG_ 179 LevelRequest_RearAxle_ISig_5 100;
BA_ "GenSigCycleTimeActive" SG_ 179 LevelRequest_RearAxle_ISig_5 100;
BA_ "GenSigStartValue" SG_ 179 LevelRequest_RearAxle_ISig_5 7;
BA_ "GenSigMaxLatency" SG_ 179 LevelRequest_RearAxle_ISig_5 20;
BA_ "GenSigCycleTime" SG_ 179 LiftAxle1DirectControl_ISig_5 100;
BA_ "GenSigCycleTimeActive" SG_ 179 LiftAxle1DirectControl_ISig_5 100;
BA_ "GenSigStartValue" SG_ 179 LiftAxle1DirectControl_ISig_5 7;
BA_ "GenSigMaxLatency" SG_ 179 LiftAxle1DirectControl_ISig_5 20;
BA_ "GenSigCycleTime" SG_ 179 ECSStandByRequest_ISig_5 100;
BA_ "GenSigCycleTimeActive" SG_ 179 ECSStandByRequest_ISig_5 100;
BA_ "GenSigStartValue" SG_ 179 ECSStandByRequest_ISig_5 7;
BA_ "GenSigMaxLatency" SG_ 179 ECSStandByRequest_ISig_5 20;
BA_ "GenSigCycleTime" SG_ 179 LiftAxle2LiftPositionRequest_ISi 100;
BA_ "GenSigCycleTimeActive" SG_ 179 LiftAxle2LiftPositionRequest_ISi 100;
BA_ "GenSigStartValue" SG_ 179 LiftAxle2LiftPositionRequest_ISi 7;
BA_ "GenSigMaxLatency" SG_ 179 LiftAxle2LiftPositionRequest_ISi 20;
BA_ "SystemSignalLongSymbol" SG_ 179 LiftAxle2LiftPositionRequest_ISi "LiftAxle2LiftPositionRequest_ISig_5";
BA_ "GenSigCycleTime" SG_ 179 FogLightRear_ButtonStatus_1 100;
BA_ "GenSigCycleTimeActive" SG_ 179 FogLightRear_ButtonStatus_1 100;
BA_ "GenSigStartValue" SG_ 179 FogLightRear_ButtonStatus_1 3;
BA_ "GenSigMaxLatency" SG_ 179 FogLightRear_ButtonStatus_1 20;
BA_ "GenSigCycleTime" SG_ 179 LevelStrokeRequest_ISig_5 100;
BA_ "GenSigCycleTimeActive" SG_ 179 LevelStrokeRequest_ISig_5 100;
BA_ "GenSigStartValue" SG_ 179 LevelStrokeRequest_ISig_5 3;
BA_ "GenSigMaxLatency" SG_ 179 LevelStrokeRequest_ISig_5 20;
BA_ "GenSigCycleTime" SG_ 179 RampLevelRequest_ISig_5 100;
BA_ "GenSigCycleTimeActive" SG_ 179 RampLevelRequest_ISig_5 100;
BA_ "GenSigStartValue" SG_ 179 RampLevelRequest_ISig_5 15;
BA_ "GenSigMaxLatency" SG_ 179 RampLevelRequest_ISig_5 20;
BA_ "GenSigCycleTime" SG_ 179 LevelRequest_FrontAxle_ISig_5 100;
BA_ "GenSigCycleTimeActive" SG_ 179 LevelRequest_FrontAxle_ISig_5 100;
BA_ "GenSigStartValue" SG_ 179 LevelRequest_FrontAxle_ISig_5 7;
BA_ "GenSigMaxLatency" SG_ 179 LevelRequest_FrontAxle_ISig_5 20;
BA_ "GenSigCycleTime" SG_ 179 LiftAxle2AutoLiftRequest_ISig_5 100;
BA_ "GenSigCycleTimeActive" SG_ 179 LiftAxle2AutoLiftRequest_ISig_5 100;
BA_ "GenSigStartValue" SG_ 179 LiftAxle2AutoLiftRequest_ISig_5 3;
BA_ "GenSigMaxLatency" SG_ 179 LiftAxle2AutoLiftRequest_ISig_5 20;
BA_ "GenSigCycleTime" SG_ 179 RampLevelStorageRequest_ISig_5 100;
BA_ "GenSigCycleTimeActive" SG_ 179 RampLevelStorageRequest_ISig_5 100;
BA_ "GenSigStartValue" SG_ 179 RampLevelStorageRequest_ISig_5 15;
BA_ "GenSigMaxLatency" SG_ 179 RampLevelStorageRequest_ISig_5 20;
BA_ "GenSigCycleTime" SG_ 179 RideHeightStorageRequest_ISig_5 100;
BA_ "GenSigCycleTimeActive" SG_ 179 RideHeightStorageRequest_ISig_5 100;
BA_ "GenSigStartValue" SG_ 179 RideHeightStorageRequest_ISig_5 15;
BA_ "GenSigMaxLatency" SG_ 179 RideHeightStorageRequest_ISig_5 20;
BA_ "GenSigSendType" SG_ 2671833752 PhysDiagRespSig_F2_98_ISig_5 7;
BA_ "GenSigSendType" SG_ 2671833730 PhysDiagRespSig_F2_82_ISig_5 7;
BA_ "GenSigSendType" SG_ 2671833700 PhysDiagRespSig_F2_64_ISig_5 7;
BA_ "GenSigSendType" SG_ 2671833697 PhysDiagRespSig_F2_61_ISig_5 7;
BA_ "GenSigSendType" SG_ 2671833664 PhysDiagRespSig_F2_40_ISig_5 7;
BA_ "GenSigSendType" SG_ 2671810802 PhysDiagReqSig_98_F2_ISig_5 7;
BA_ "GenSigSendType" SG_ 2671805170 PhysDiagReqSig_82_F2_ISig_5 7;
BA_ "GenSigSendType" SG_ 2671797490 PhysDiagReqSig_64_F2_ISig_5 7;
BA_ "GenSigSendType" SG_ 2671796722 PhysDiagReqSig_61_F2_ISig_5 7;
BA_ "GenSigSendType" SG_ 2671788274 PhysDiagReqSig_40_F2_ISig_5 7;
BA_ "GenSigCycleTime" SG_ 419 ClimateAutoRequest 100;
BA_ "GenSigCycleTimeActive" SG_ 419 ClimateAutoRequest 100;
BA_ "GenSigStartValue" SG_ 419 ClimateAutoRequest 3;
BA_ "GenSigMaxLatency" SG_ 419 ClimateAutoRequest 50;
BA_ "GenSigCycleTime" SG_ 419 ClimateAirDistRequest_Vent 100;
BA_ "GenSigCycleTimeActive" SG_ 419 ClimateAirDistRequest_Vent 100;
BA_ "GenSigStartValue" SG_ 419 ClimateAirDistRequest_Vent 15;
BA_ "GenSigMaxLatency" SG_ 419 ClimateAirDistRequest_Vent 50;
BA_ "GenSigCycleTime" SG_ 419 HVACBlowerRequest 100;
BA_ "GenSigCycleTimeActive" SG_ 419 HVACBlowerRequest 100;
BA_ "GenSigStartValue" SG_ 419 HVACBlowerRequest 31;
BA_ "GenSigMaxLatency" SG_ 419 HVACBlowerRequest 50;
BA_ "GenSigCycleTime" SG_ 419 ACModeRqst 100;
BA_ "GenSigCycleTimeActive" SG_ 419 ACModeRqst 100;
BA_ "GenSigStartValue" SG_ 419 ACModeRqst 7;
BA_ "GenSigMaxLatency" SG_ 419 ACModeRqst 50;
BA_ "GenSigCycleTime" SG_ 419 ParkingClimateRequest 100;
BA_ "GenSigCycleTimeActive" SG_ 419 ParkingClimateRequest 100;
BA_ "GenSigStartValue" SG_ 419 ParkingClimateRequest 3;
BA_ "GenSigMaxLatency" SG_ 419 ParkingClimateRequest 50;
BA_ "GenSigCycleTime" SG_ 419 AutoBlowerLevelRqst 100;
BA_ "GenSigCycleTimeActive" SG_ 419 AutoBlowerLevelRqst 100;
BA_ "GenSigStartValue" SG_ 419 AutoBlowerLevelRqst 7;
BA_ "GenSigMaxLatency" SG_ 419 AutoBlowerLevelRqst 50;
BA_ "GenSigCycleTime" SG_ 419 MaxDefrostRequest 100;
BA_ "GenSigCycleTimeActive" SG_ 419 MaxDefrostRequest 100;
BA_ "GenSigStartValue" SG_ 419 MaxDefrostRequest 3;
BA_ "GenSigMaxLatency" SG_ 419 MaxDefrostRequest 50;
BA_ "GenSigCycleTime" SG_ 419 AQSModeRqst 100;
BA_ "GenSigCycleTimeActive" SG_ 419 AQSModeRqst 100;
BA_ "GenSigStartValue" SG_ 419 AQSModeRqst 7;
BA_ "GenSigMaxLatency" SG_ 419 AQSModeRqst 50;
BA_ "GenSigCycleTime" SG_ 419 CabTempRequest 100;
BA_ "GenSigCycleTimeActive" SG_ 419 CabTempRequest 100;
BA_ "GenSigStartValue" SG_ 419 CabTempRequest 127;
BA_ "GenSigMaxLatency" SG_ 419 CabTempRequest 50;
BA_ "GenSigCycleTime" SG_ 419 ClimateAirDistRequest_Floor 100;
BA_ "GenSigCycleTimeActive" SG_ 419 ClimateAirDistRequest_Floor 100;
BA_ "GenSigStartValue" SG_ 419 ClimateAirDistRequest_Floor 15;
BA_ "GenSigMaxLatency" SG_ 419 ClimateAirDistRequest_Floor 50;
BA_ "GenSigCycleTime" SG_ 419 AirRecirculationRequest 100;
BA_ "GenSigCycleTimeActive" SG_ 419 AirRecirculationRequest 100;
BA_ "GenSigStartValue" SG_ 419 AirRecirculationRequest 3;
BA_ "GenSigMaxLatency" SG_ 419 AirRecirculationRequest 50;
BA_ "GenSigCycleTime" SG_ 419 ACRequest 100;
BA_ "GenSigCycleTimeActive" SG_ 419 ACRequest 100;
BA_ "GenSigStartValue" SG_ 419 ACRequest 3;
BA_ "GenSigMaxLatency" SG_ 419 ACRequest 50;
BA_ "GenSigCycleTime" SG_ 419 ClimateAirDistRequest_Defrost 100;
BA_ "GenSigCycleTimeActive" SG_ 419 ClimateAirDistRequest_Defrost 100;
BA_ "GenSigStartValue" SG_ 419 ClimateAirDistRequest_Defrost 15;
BA_ "GenSigMaxLatency" SG_ 419 ClimateAirDistRequest_Defrost 50;
BA_ "GenSigCycleTime" SG_ 419 ClimatePowerRequest 100;
BA_ "GenSigCycleTimeActive" SG_ 419 ClimatePowerRequest 100;
BA_ "GenSigStartValue" SG_ 419 ClimatePowerRequest 3;
BA_ "GenSigMaxLatency" SG_ 419 ClimatePowerRequest 50;
BA_ "GenSigCycleTime" SG_ 419 AutoDefogModeRqst 100;
BA_ "GenSigCycleTimeActive" SG_ 419 AutoDefogModeRqst 100;
BA_ "GenSigStartValue" SG_ 419 AutoDefogModeRqst 7;
BA_ "GenSigMaxLatency" SG_ 419 AutoDefogModeRqst 50;
BA_ "GenSigSendType" SG_ 1457 IC_09S_C05_FCS 7;
BA_ "GenSigSendType" SG_ 1456 ECU3VIN_stat 1;
BA_ "GenSigMaxLatency" SG_ 1456 ECU3VIN_stat 1000;
BA_ "GenSigCycleTime" SG_ 1184 FasDampingSetting_rqst_ISig_5 100;
BA_ "GenSigCycleTimeActive" SG_ 1184 FasDampingSetting_rqst_ISig_5 100;
BA_ "GenSigStartValue" SG_ 1184 FasDampingSetting_rqst_ISig_5 31;
BA_ "GenSigMaxLatency" SG_ 1184 FasDampingSetting_rqst_ISig_5 1000;
BA_ "GenSigCycleTime" SG_ 1184 FasPersonalSettingsButton_rqst_I 100;
BA_ "GenSigCycleTimeActive" SG_ 1184 FasPersonalSettingsButton_rqst_I 100;
BA_ "GenSigStartValue" SG_ 1184 FasPersonalSettingsButton_rqst_I 7;
BA_ "GenSigMaxLatency" SG_ 1184 FasPersonalSettingsButton_rqst_I 1000;
BA_ "SystemSignalLongSymbol" SG_ 1184 FasPersonalSettingsButton_rqst_I "FasPersonalSettingsButton_rqst_ISig_5";
BA_ "GenSigCycleTime" SG_ 1184 FasStiffnessCurveSetting_rqst_IS 100;
BA_ "GenSigCycleTimeActive" SG_ 1184 FasStiffnessCurveSetting_rqst_IS 100;
BA_ "GenSigStartValue" SG_ 1184 FasStiffnessCurveSetting_rqst_IS 31;
BA_ "GenSigMaxLatency" SG_ 1184 FasStiffnessCurveSetting_rqst_IS 1000;
BA_ "SystemSignalLongSymbol" SG_ 1184 FasStiffnessCurveSetting_rqst_IS "FasStiffnessCurveSetting_rqst_ISig_5";
BA_ "GenSigCycleTime" SG_ 1184 FasDriver_rqst_ISig_5 100;
BA_ "GenSigCycleTimeActive" SG_ 1184 FasDriver_rqst_ISig_5 100;
BA_ "GenSigStartValue" SG_ 1184 FasDriver_rqst_ISig_5 15;
BA_ "GenSigMaxLatency" SG_ 1184 FasDriver_rqst_ISig_5 1000;
BA_ "GenSigCycleTime" SG_ 1184 FasUsrDefinedStorage_rqst_ISig_5 100;
BA_ "GenSigCycleTimeActive" SG_ 1184 FasUsrDefinedStorage_rqst_ISig_5 100;
BA_ "GenSigStartValue" SG_ 1184 FasUsrDefinedStorage_rqst_ISig_5 3;
BA_ "GenSigMaxLatency" SG_ 1184 FasUsrDefinedStorage_rqst_ISig_5 1000;
BA_ "GenSigCycleTime" SG_ 1184 FasStiffStraightSetting_rqst_ISi 100;
BA_ "GenSigCycleTimeActive" SG_ 1184 FasStiffStraightSetting_rqst_ISi 100;
BA_ "GenSigStartValue" SG_ 1184 FasStiffStraightSetting_rqst_ISi 31;
BA_ "GenSigMaxLatency" SG_ 1184 FasStiffStraightSetting_rqst_ISi 1000;
BA_ "SystemSignalLongSymbol" SG_ 1184 FasStiffStraightSetting_rqst_ISi "FasStiffStraightSetting_rqst_ISig_5";
BA_ "GenSigCycleTime" SG_ 1184 FasLowSpeedReturnSetting_rqst_IS 100;
BA_ "GenSigCycleTimeActive" SG_ 1184 FasLowSpeedReturnSetting_rqst_IS 100;
BA_ "GenSigStartValue" SG_ 1184 FasLowSpeedReturnSetting_rqst_IS 31;
BA_ "GenSigMaxLatency" SG_ 1184 FasLowSpeedReturnSetting_rqst_IS 1000;
BA_ "SystemSignalLongSymbol" SG_ 1184 FasLowSpeedReturnSetting_rqst_IS "FasLowSpeedReturnSetting_rqst_ISig_5";
BA_ "GenSigCycleTime" SG_ 1184 FasManualOffsetSetting_rqst_ISig 100;
BA_ "GenSigCycleTimeActive" SG_ 1184 FasManualOffsetSetting_rqst_ISig 100;
BA_ "GenSigStartValue" SG_ 1184 FasManualOffsetSetting_rqst_ISig 31;
BA_ "GenSigMaxLatency" SG_ 1184 FasManualOffsetSetting_rqst_ISig 1000;
BA_ "SystemSignalLongSymbol" SG_ 1184 FasManualOffsetSetting_rqst_ISig "FasManualOffsetSetting_rqst_ISig_5";
BA_ "GenSigCycleTime" SG_ 932 DPF_ManualRegenerateRequest_ISig 100;
BA_ "GenSigCycleTimeActive" SG_ 932 DPF_ManualRegenerateRequest_ISig 100;
BA_ "GenSigStartValue" SG_ 932 DPF_ManualRegenerateRequest_ISig 3;
BA_ "GenSigMaxLatency" SG_ 932 DPF_ManualRegenerateRequest_ISig 500;
BA_ "SystemSignalLongSymbol" SG_ 932 DPF_ManualRegenerateRequest_ISig "DPF_ManualRegenerateRequest_ISig_5";
BA_ "GenSigCycleTime" SG_ 932 DPF_ManualRegenerateInhibit_ISig 100;
BA_ "GenSigCycleTimeActive" SG_ 932 DPF_ManualRegenerateInhibit_ISig 100;
BA_ "GenSigStartValue" SG_ 932 DPF_ManualRegenerateInhibit_ISig 3;
BA_ "GenSigMaxLatency" SG_ 932 DPF_ManualRegenerateInhibit_ISig 500;
BA_ "SystemSignalLongSymbol" SG_ 932 DPF_ManualRegenerateInhibit_ISig "DPF_ManualRegenerateInhibit_ISig_5";
BA_ "GenSigCycleTime" SG_ 932 DPF_ManualRegenerateTimeReq_ISig 100;
BA_ "GenSigCycleTimeActive" SG_ 932 DPF_ManualRegenerateTimeReq_ISig 100;
BA_ "GenSigStartValue" SG_ 932 DPF_ManualRegenerateTimeReq_ISig 3;
BA_ "GenSigMaxLatency" SG_ 932 DPF_ManualRegenerateTimeReq_ISig 500;
BA_ "SystemSignalLongSymbol" SG_ 932 DPF_ManualRegenerateTimeReq_ISig "DPF_ManualRegenerateTimeReq_ISig_5";
BA_ "GenSigCycleTime" SG_ 930 OBDRelDTC_IC_DrvngCycleB 100;
BA_ "GenSigCycleTimeActive" SG_ 930 OBDRelDTC_IC_DrvngCycleB 100;
BA_ "GenSigStartValue" SG_ 930 OBDRelDTC_IC_DrvngCycleB 3;
BA_ "GenSigMaxLatency" SG_ 930 OBDRelDTC_IC_DrvngCycleB 510;
BA_ "GenSigCycleTime" SG_ 930 OBDRelDTC_IC_EvalResultA 100;
BA_ "GenSigCycleTimeActive" SG_ 930 OBDRelDTC_IC_EvalResultA 100;
BA_ "GenSigStartValue" SG_ 930 OBDRelDTC_IC_EvalResultA 3;
BA_ "GenSigMaxLatency" SG_ 930 OBDRelDTC_IC_EvalResultA 510;
BA_ "GenSigCycleTime" SG_ 930 OBDRelDTC_IC_EvalResultB 100;
BA_ "GenSigCycleTimeActive" SG_ 930 OBDRelDTC_IC_EvalResultB 100;
BA_ "GenSigStartValue" SG_ 930 OBDRelDTC_IC_EvalResultB 3;
BA_ "GenSigMaxLatency" SG_ 930 OBDRelDTC_IC_EvalResultB 510;
BA_ "GenSigCycleTime" SG_ 930 OBDRelDTC_IC_EvalStatA 100;
BA_ "GenSigCycleTimeActive" SG_ 930 OBDRelDTC_IC_EvalStatA 100;
BA_ "GenSigStartValue" SG_ 930 OBDRelDTC_IC_EvalStatA 3;
BA_ "GenSigMaxLatency" SG_ 930 OBDRelDTC_IC_EvalStatA 510;
BA_ "GenSigCycleTime" SG_ 930 OBDRelDTC_IC_DtcIdB 100;
BA_ "GenSigCycleTimeActive" SG_ 930 OBDRelDTC_IC_DtcIdB 100;
BA_ "GenSigMaxLatency" SG_ 930 OBDRelDTC_IC_DtcIdB 510;
BA_ "GenSigCycleTime" SG_ 930 OBDRelDTC_IC_DrvngCycleA 100;
BA_ "GenSigCycleTimeActive" SG_ 930 OBDRelDTC_IC_DrvngCycleA 100;
BA_ "GenSigStartValue" SG_ 930 OBDRelDTC_IC_DrvngCycleA 3;
BA_ "GenSigMaxLatency" SG_ 930 OBDRelDTC_IC_DrvngCycleA 510;
BA_ "GenSigCycleTime" SG_ 930 OBDRelDTC_IC_FailTB 100;
BA_ "GenSigCycleTimeActive" SG_ 930 OBDRelDTC_IC_FailTB 100;
BA_ "GenSigMaxLatency" SG_ 930 OBDRelDTC_IC_FailTB 510;
BA_ "GenSigCycleTime" SG_ 930 OBDRelDTC_IC_DtcIdA 100;
BA_ "GenSigCycleTimeActive" SG_ 930 OBDRelDTC_IC_DtcIdA 100;
BA_ "GenSigMaxLatency" SG_ 930 OBDRelDTC_IC_DtcIdA 510;
BA_ "GenSigCycleTime" SG_ 930 OBDRelDTC_IC_FailTA 100;
BA_ "GenSigCycleTimeActive" SG_ 930 OBDRelDTC_IC_FailTA 100;
BA_ "GenSigMaxLatency" SG_ 930 OBDRelDTC_IC_FailTA 510;
BA_ "GenSigCycleTime" SG_ 930 OBDRelDTC_IC_EvalStatB 100;
BA_ "GenSigCycleTimeActive" SG_ 930 OBDRelDTC_IC_EvalStatB 100;
BA_ "GenSigStartValue" SG_ 930 OBDRelDTC_IC_EvalStatB 3;
BA_ "GenSigMaxLatency" SG_ 930 OBDRelDTC_IC_EvalStatB 510;
BA_ "GenSigCycleTime" SG_ 928 Set_LG5CutoffValue_ISig_5 100;
BA_ "GenSigCycleTimeActive" SG_ 928 Set_LG5CutoffValue_ISig_5 100;
BA_ "GenSigStartValue" SG_ 928 Set_LG5CutoffValue_ISig_5 255;
BA_ "GenSigMaxLatency" SG_ 928 Set_LG5CutoffValue_ISig_5 515;
BA_ "GenSigCycleTime" SG_ 928 Set_LG3CutoffValue_ISig_5 100;
BA_ "GenSigCycleTimeActive" SG_ 928 Set_LG3CutoffValue_ISig_5 100;
BA_ "GenSigStartValue" SG_ 928 Set_LG3CutoffValue_ISig_5 255;
BA_ "GenSigMaxLatency" SG_ 928 Set_LG3CutoffValue_ISig_5 515;
BA_ "GenSigCycleTime" SG_ 928 Set_LG1CutoffValue_ISig_5 100;
BA_ "GenSigCycleTimeActive" SG_ 928 Set_LG1CutoffValue_ISig_5 100;
BA_ "GenSigStartValue" SG_ 928 Set_LG1CutoffValue_ISig_5 255;
BA_ "GenSigMaxLatency" SG_ 928 Set_LG1CutoffValue_ISig_5 515;
BA_ "GenSigCycleTime" SG_ 928 Set_LG2CutoffValue_ISig_5 100;
BA_ "GenSigCycleTimeActive" SG_ 928 Set_LG2CutoffValue_ISig_5 100;
BA_ "GenSigStartValue" SG_ 928 Set_LG2CutoffValue_ISig_5 255;
BA_ "GenSigMaxLatency" SG_ 928 Set_LG2CutoffValue_ISig_5 515;
BA_ "GenSigCycleTime" SG_ 928 Set_LG4CutoffValue_ISig_5 100;
BA_ "GenSigCycleTimeActive" SG_ 928 Set_LG4CutoffValue_ISig_5 100;
BA_ "GenSigStartValue" SG_ 928 Set_LG4CutoffValue_ISig_5 255;
BA_ "GenSigMaxLatency" SG_ 928 Set_LG4CutoffValue_ISig_5 515;
BA_ "GenSigCycleTime" SG_ 928 Set_EnergySetting_ISig_5 100;
BA_ "GenSigCycleTimeActive" SG_ 928 Set_EnergySetting_ISig_5 100;
BA_ "GenSigStartValue" SG_ 928 Set_EnergySetting_ISig_5 7;
BA_ "GenSigMaxLatency" SG_ 928 Set_EnergySetting_ISig_5 515;
BA_ "GenSigCycleTime" SG_ 928 Set_LG6CutoffValue_ISig_5 100;
BA_ "GenSigCycleTimeActive" SG_ 928 Set_LG6CutoffValue_ISig_5 100;
BA_ "GenSigStartValue" SG_ 928 Set_LG6CutoffValue_ISig_5 255;
BA_ "GenSigMaxLatency" SG_ 928 Set_LG6CutoffValue_ISig_5 515;
BA_ "GenSigCycleTime" SG_ 784 SpeedAdaptEnableRqst_SpeedLimit_ 100;
BA_ "GenSigCycleTimeActive" SG_ 784 SpeedAdaptEnableRqst_SpeedLimit_ 100;
BA_ "GenSigStartValue" SG_ 784 SpeedAdaptEnableRqst_SpeedLimit_ 3;
BA_ "GenSigMaxLatency" SG_ 784 SpeedAdaptEnableRqst_SpeedLimit_ 200;
BA_ "SystemSignalLongSymbol" SG_ 784 SpeedAdaptEnableRqst_SpeedLimit_ "SpeedAdaptEnableRqst_SpeedLimit_ISig_5";
BA_ "GenSigCycleTime" SG_ 784 SpeedAdaptEnableRqst_SlowTraffic 100;
BA_ "GenSigCycleTimeActive" SG_ 784 SpeedAdaptEnableRqst_SlowTraffic 100;
BA_ "GenSigStartValue" SG_ 784 SpeedAdaptEnableRqst_SlowTraffic 3;
BA_ "GenSigMaxLatency" SG_ 784 SpeedAdaptEnableRqst_SlowTraffic 200;
BA_ "SystemSignalLongSymbol" SG_ 784 SpeedAdaptEnableRqst_SlowTraffic "SpeedAdaptEnableRqst_SlowTraffic_ISig_5";
BA_ "GenSigCycleTime" SG_ 784 BattEnergySetLevel_input_ISig_5 100;
BA_ "GenSigCycleTimeActive" SG_ 784 BattEnergySetLevel_input_ISig_5 100;
BA_ "GenSigStartValue" SG_ 784 BattEnergySetLevel_input_ISig_5 7;
BA_ "GenSigMaxLatency" SG_ 784 BattEnergySetLevel_input_ISig_5 200;
BA_ "GenSigCycleTime" SG_ 784 SpeedAdaptationLevelRqst_ISig_5 100;
BA_ "GenSigCycleTimeActive" SG_ 784 SpeedAdaptationLevelRqst_ISig_5 100;
BA_ "GenSigStartValue" SG_ 784 SpeedAdaptationLevelRqst_ISig_5 7;
BA_ "GenSigMaxLatency" SG_ 784 SpeedAdaptationLevelRqst_ISig_5 200;
BA_ "GenSigCycleTime" SG_ 784 SpeedAdaptEnableRqst_Curve_ISig_ 100;
BA_ "GenSigCycleTimeActive" SG_ 784 SpeedAdaptEnableRqst_Curve_ISig_ 100;
BA_ "GenSigStartValue" SG_ 784 SpeedAdaptEnableRqst_Curve_ISig_ 3;
BA_ "GenSigMaxLatency" SG_ 784 SpeedAdaptEnableRqst_Curve_ISig_ 200;
BA_ "SystemSignalLongSymbol" SG_ 784 SpeedAdaptEnableRqst_Curve_ISig_ "SpeedAdaptEnableRqst_Curve_ISig_5";
BA_ "GenSigCycleTime" SG_ 784 ExtraHeating_rqst 100;
BA_ "GenSigCycleTimeActive" SG_ 784 ExtraHeating_rqst 100;
BA_ "GenSigStartValue" SG_ 784 ExtraHeating_rqst 7;
BA_ "GenSigMaxLatency" SG_ 784 ExtraHeating_rqst 200;
BA_ "GenSigCycleTime" SG_ 672 ParkingHeaterCleaning_cmd 100;
BA_ "GenSigCycleTimeActive" SG_ 672 ParkingHeaterCleaning_cmd 100;
BA_ "GenSigStartValue" SG_ 672 ParkingHeaterCleaning_cmd 3;
BA_ "GenSigMaxLatency" SG_ 672 ParkingHeaterCleaning_cmd 100;
BA_ "GenSigCycleTime" SG_ 672 DriverMemory_rqst_ISig_5 100;
BA_ "GenSigCycleTimeActive" SG_ 672 DriverMemory_rqst_ISig_5 100;
BA_ "GenSigStartValue" SG_ 672 DriverMemory_rqst_ISig_5 31;
BA_ "GenSigMaxLatency" SG_ 672 DriverMemory_rqst_ISig_5 100;
BA_ "GenSigCycleTime" SG_ 672 FirstAxleLowerPrioRequested_ISig 100;
BA_ "GenSigCycleTimeActive" SG_ 672 FirstAxleLowerPrioRequested_ISig 100;
BA_ "GenSigStartValue" SG_ 672 FirstAxleLowerPrioRequested_ISig 7;
BA_ "GenSigMaxLatency" SG_ 672 FirstAxleLowerPrioRequested_ISig 100;
BA_ "SystemSignalLongSymbol" SG_ 672 FirstAxleLowerPrioRequested_ISig "FirstAxleLowerPrioRequested_ISig_5";
BA_ "GenSigCycleTime" SG_ 672 ExteriorLampTest_rqst 100;
BA_ "GenSigCycleTimeActive" SG_ 672 ExteriorLampTest_rqst 100;
BA_ "GenSigStartValue" SG_ 672 ExteriorLampTest_rqst 3;
BA_ "GenSigCycleTime" SG_ 672 AutoShutOffAnswerInput_ISig_5 100;
BA_ "GenSigCycleTimeActive" SG_ 672 AutoShutOffAnswerInput_ISig_5 100;
BA_ "GenSigStartValue" SG_ 672 AutoShutOffAnswerInput_ISig_5 7;
BA_ "GenSigMaxLatency" SG_ 672 AutoShutOffAnswerInput_ISig_5 100;
BA_ "GenSigCycleTime" SG_ 672 ManualEngineCoolingDev_Ind 100;
BA_ "GenSigCycleTimeActive" SG_ 672 ManualEngineCoolingDev_Ind 100;
BA_ "GenSigStartValue" SG_ 672 ManualEngineCoolingDev_Ind 3;
BA_ "GenSigMaxLatency" SG_ 672 ManualEngineCoolingDev_Ind 100;
BA_ "GenSigCycleTime" SG_ 672 TemporaryRSLDeviceIndication 100;
BA_ "GenSigCycleTimeActive" SG_ 672 TemporaryRSLDeviceIndication 100;
BA_ "GenSigStartValue" SG_ 672 TemporaryRSLDeviceIndication 3;
BA_ "GenSigMaxLatency" SG_ 672 TemporaryRSLDeviceIndication 100;
BA_ "GenSigCycleTime" SG_ 672 ESC_ButtonIndication2 100;
BA_ "GenSigCycleTimeActive" SG_ 672 ESC_ButtonIndication2 100;
BA_ "GenSigStartValue" SG_ 672 ESC_ButtonIndication2 3;
BA_ "GenSigMaxLatency" SG_ 672 ESC_ButtonIndication2 100;
BA_ "GenSigCycleTime" SG_ 672 WaterInFuelDrainRequest_ISig_5 100;
BA_ "GenSigCycleTimeActive" SG_ 672 WaterInFuelDrainRequest_ISig_5 100;
BA_ "GenSigStartValue" SG_ 672 WaterInFuelDrainRequest_ISig_5 3;
BA_ "GenSigMaxLatency" SG_ 672 WaterInFuelDrainRequest_ISig_5 100;
BA_ "GenSigCycleTime" SG_ 672 PreTripIndication3 100;
BA_ "GenSigCycleTimeActive" SG_ 672 PreTripIndication3 100;
BA_ "GenSigStartValue" SG_ 672 PreTripIndication3 3;
BA_ "GenSigMaxLatency" SG_ 672 PreTripIndication3 100;
BA_ "GenSigCycleTime" SG_ 672 ESCOff_DeviceIndication 100;
BA_ "GenSigCycleTimeActive" SG_ 672 ESCOff_DeviceIndication 100;
BA_ "GenSigStartValue" SG_ 672 ESCOff_DeviceIndication 3;
BA_ "GenSigMaxLatency" SG_ 672 ESCOff_DeviceIndication 100;
BA_ "GenSigCycleTime" SG_ 672 AWBEnableRequest_ISig_5 100;
BA_ "GenSigCycleTimeActive" SG_ 672 AWBEnableRequest_ISig_5 100;
BA_ "GenSigStartValue" SG_ 672 AWBEnableRequest_ISig_5 3;
BA_ "GenSigMaxLatency" SG_ 672 AWBEnableRequest_ISig_5 100;
BA_ "GenSigCycleTime" SG_ 672 LampCheck_rqst_ISig_5 100;
BA_ "GenSigCycleTimeActive" SG_ 672 LampCheck_rqst_ISig_5 100;
BA_ "GenSigStartValue" SG_ 672 LampCheck_rqst_ISig_5 3;
BA_ "GenSigMaxLatency" SG_ 672 LampCheck_rqst_ISig_5 100;
BA_ "GenSigCycleTime" SG_ 416 SSReq_Repetition 100;
BA_ "GenSigCycleTimeActive" SG_ 416 SSReq_Repetition 100;
BA_ "GenSigMaxLatency" SG_ 416 SSReq_Repetition 50;
BA_ "GenSigCycleTime" SG_ 416 SSReq_Balance 100;
BA_ "GenSigCycleTimeActive" SG_ 416 SSReq_Balance 100;
BA_ "GenSigMaxLatency" SG_ 416 SSReq_Balance 50;
BA_ "GenSigCycleTime" SG_ 416 SSReq_Time 100;
BA_ "GenSigCycleTimeActive" SG_ 416 SSReq_Time 100;
BA_ "GenSigMaxLatency" SG_ 416 SSReq_Time 50;
BA_ "GenSigCycleTime" SG_ 416 PhoneButtonIndication_cmd 100;
BA_ "GenSigCycleTimeActive" SG_ 416 PhoneButtonIndication_cmd 100;
BA_ "GenSigStartValue" SG_ 416 PhoneButtonIndication_cmd 3;
BA_ "GenSigMaxLatency" SG_ 416 PhoneButtonIndication_cmd 50;
BA_ "GenSigCycleTime" SG_ 416 FuncIndIlluminationLevel_ISig_5 100;
BA_ "GenSigCycleTimeActive" SG_ 416 FuncIndIlluminationLevel_ISig_5 100;
BA_ "GenSigStartValue" SG_ 416 FuncIndIlluminationLevel_ISig_5 1;
BA_ "GenSigMaxLatency" SG_ 416 FuncIndIlluminationLevel_ISig_5 50;
BA_ "GenSigCycleTime" SG_ 416 BacklightCmd_ISig_5 100;
BA_ "GenSigCycleTimeActive" SG_ 416 BacklightCmd_ISig_5 100;
BA_ "GenSigMaxLatency" SG_ 416 BacklightCmd_ISig_5 50;
BA_ "GenSigCycleTime" SG_ 416 SSReq_Id 100;
BA_ "GenSigCycleTimeActive" SG_ 416 SSReq_Id 100;
BA_ "GenSigMaxLatency" SG_ 416 SSReq_Id 50;
BA_ "GenSigCycleTime" SG_ 416 SSReq_Mixed 100;
BA_ "GenSigCycleTimeActive" SG_ 416 SSReq_Mixed 100;
BA_ "GenSigMaxLatency" SG_ 416 SSReq_Mixed 50;
BA_ "GenSigCycleTime" SG_ 416 BunkBacklightCmd 100;
BA_ "GenSigCycleTimeActive" SG_ 416 BunkBacklightCmd 100;
BA_ "GenSigStartValue" SG_ 416 BunkBacklightCmd 31;
BA_ "GenSigMaxLatency" SG_ 416 BunkBacklightCmd 50;
BA_ "GenSigCycleTime" SG_ 416 SSReq_State 100;
BA_ "GenSigCycleTimeActive" SG_ 416 SSReq_State 100;
BA_ "GenSigMaxLatency" SG_ 416 SSReq_State 50;
BA_ "GenSigCycleTime" SG_ 416 SSReq_Volume 100;
BA_ "GenSigCycleTimeActive" SG_ 416 SSReq_Volume 100;
BA_ "GenSigMaxLatency" SG_ 416 SSReq_Volume 50;
BA_ "GenSigCycleTime" SG_ 211 TimeGapBtnStat 100;
BA_ "GenSigCycleTimeActive" SG_ 211 TimeGapBtnStat 100;
BA_ "GenSigStartValue" SG_ 211 TimeGapBtnStat 3;
BA_ "GenSigMaxLatency" SG_ 211 TimeGapBtnStat 30;
BA_ "GenSigCycleTime" SG_ 211 ATC_ButtonIndication 100;
BA_ "GenSigCycleTimeActive" SG_ 211 ATC_ButtonIndication 100;
BA_ "GenSigStartValue" SG_ 211 ATC_ButtonIndication 3;
BA_ "GenSigMaxLatency" SG_ 211 ATC_ButtonIndication 30;
BA_ "GenSigCycleTime" SG_ 211 PauseOffBtnStat 100;
BA_ "GenSigCycleTimeActive" SG_ 211 PauseOffBtnStat 100;
BA_ "GenSigStartValue" SG_ 211 PauseOffBtnStat 3;
BA_ "GenSigMaxLatency" SG_ 211 PauseOffBtnStat 30;
BA_ "GenSigCycleTime" SG_ 211 ABS_ButtonIndication 100;
BA_ "GenSigCycleTimeActive" SG_ 211 ABS_ButtonIndication 100;
BA_ "GenSigStartValue" SG_ 211 ABS_ButtonIndication 3;
BA_ "GenSigMaxLatency" SG_ 211 ABS_ButtonIndication 30;
BA_ "GenSigCycleTime" SG_ 211 SW_HeadlightInterrupt_Stat 100;
BA_ "GenSigCycleTimeActive" SG_ 211 SW_HeadlightInterrupt_Stat 100;
BA_ "GenSigStartValue" SG_ 211 SW_HeadlightInterrupt_Stat 3;
BA_ "GenSigMaxLatency" SG_ 211 SW_HeadlightInterrupt_Stat 30;
BA_ "GenSigCycleTime" SG_ 211 PBAlertActiveStatus_ISig_5 100;
BA_ "GenSigCycleTimeActive" SG_ 211 PBAlertActiveStatus_ISig_5 100;
BA_ "GenSigStartValue" SG_ 211 PBAlertActiveStatus_ISig_5 7;
BA_ "GenSigMaxLatency" SG_ 211 PBAlertActiveStatus_ISig_5 30;
BA_ "GenSigCycleTime" SG_ 211 EcoRollEnableRequest_ISig_5 100;
BA_ "GenSigCycleTimeActive" SG_ 211 EcoRollEnableRequest_ISig_5 100;
BA_ "GenSigStartValue" SG_ 211 EcoRollEnableRequest_ISig_5 3;
BA_ "GenSigMaxLatency" SG_ 211 EcoRollEnableRequest_ISig_5 30;
BA_ "GenSigCycleTime" SG_ 211 EcoSettingsBtnStat 100;
BA_ "GenSigCycleTimeActive" SG_ 211 EcoSettingsBtnStat 100;
BA_ "GenSigStartValue" SG_ 211 EcoSettingsBtnStat 3;
BA_ "GenSigMaxLatency" SG_ 211 EcoSettingsBtnStat 30;
BA_ "GenSigCycleTime" SG_ 211 SkipNextBtnStat 100;
BA_ "GenSigCycleTimeActive" SG_ 211 SkipNextBtnStat 100;
BA_ "GenSigStartValue" SG_ 211 SkipNextBtnStat 3;
BA_ "GenSigMaxLatency" SG_ 211 SkipNextBtnStat 30;
BA_ "GenSigCycleTime" SG_ 211 GENSWS_PushButton_7_17_ISig_5 100;
BA_ "GenSigCycleTimeActive" SG_ 211 GENSWS_PushButton_7_17_ISig_5 100;
BA_ "GenSigStartValue" SG_ 211 GENSWS_PushButton_7_17_ISig_5 3;
BA_ "GenSigCycleTime" SG_ 211 TCS_ButtonIndication 100;
BA_ "GenSigCycleTimeActive" SG_ 211 TCS_ButtonIndication 100;
BA_ "GenSigStartValue" SG_ 211 TCS_ButtonIndication 3;
BA_ "GenSigMaxLatency" SG_ 211 TCS_ButtonIndication 30;
BA_ "GenSigCycleTime" SG_ 211 DHCBtnStat 100;
BA_ "GenSigCycleTimeActive" SG_ 211 DHCBtnStat 100;
BA_ "GenSigStartValue" SG_ 211 DHCBtnStat 3;
BA_ "GenSigMaxLatency" SG_ 211 DHCBtnStat 30;
BA_ "GenSigCycleTime" SG_ 211 SW_PushToTalk_BtnStat_6_17_ISig_ 100;
BA_ "GenSigCycleTimeActive" SG_ 211 SW_PushToTalk_BtnStat_6_17_ISig_ 100;
BA_ "GenSigStartValue" SG_ 211 SW_PushToTalk_BtnStat_6_17_ISig_ 3;
BA_ "SystemSignalLongSymbol" SG_ 211 SW_PushToTalk_BtnStat_6_17_ISig_ "SW_PushToTalk_BtnStat_6_17_ISig_5";
BA_ "GenSigCycleTime" SG_ 211 GENSWS_PushButton_7_3_ISig_5 100;
BA_ "GenSigCycleTimeActive" SG_ 211 GENSWS_PushButton_7_3_ISig_5 100;
BA_ "GenSigStartValue" SG_ 211 GENSWS_PushButton_7_3_ISig_5 3;
BA_ "GenSigCycleTime" SG_ 211 SWSpdCtrlButtonsStatus6 100;
BA_ "GenSigCycleTimeActive" SG_ 211 SWSpdCtrlButtonsStatus6 100;
BA_ "GenSigStartValue" SG_ 211 SWSpdCtrlButtonsStatus6 15;
BA_ "GenSigCycleTime" SG_ 211 PhoneBtnStat 100;
BA_ "GenSigCycleTimeActive" SG_ 211 PhoneBtnStat 100;
BA_ "GenSigStartValue" SG_ 211 PhoneBtnStat 3;
BA_ "GenSigMaxLatency" SG_ 211 PhoneBtnStat 30;
BA_ "GenSigCycleTime" SG_ 211 SW_Home_ButtonsStatus_6 100;
BA_ "GenSigCycleTimeActive" SG_ 211 SW_Home_ButtonsStatus_6 100;
BA_ "GenSigStartValue" SG_ 211 SW_Home_ButtonsStatus_6 3;
BA_ "GenSigCycleTime" SG_ 211 SkipPrevBtnStat 100;
BA_ "GenSigCycleTimeActive" SG_ 211 SkipPrevBtnStat 100;
BA_ "GenSigStartValue" SG_ 211 SkipPrevBtnStat 3;
BA_ "GenSigMaxLatency" SG_ 211 SkipPrevBtnStat 30;
BA_ "GenSigCycleTime" SG_ 211 ActivateBtnStat 100;
BA_ "GenSigCycleTimeActive" SG_ 211 ActivateBtnStat 100;
BA_ "GenSigStartValue" SG_ 211 ActivateBtnStat 3;
BA_ "GenSigMaxLatency" SG_ 211 ActivateBtnStat 30;
BA_ "GenSigCycleTime" SG_ 211 ResIncrBtnStat 100;
BA_ "GenSigCycleTimeActive" SG_ 211 ResIncrBtnStat 100;
BA_ "GenSigStartValue" SG_ 211 ResIncrBtnStat 3;
BA_ "GenSigMaxLatency" SG_ 211 ResIncrBtnStat 30;
BA_ "GenSigCycleTime" SG_ 211 SrcBtnStat 100;
BA_ "GenSigCycleTimeActive" SG_ 211 SrcBtnStat 100;
BA_ "GenSigStartValue" SG_ 211 SrcBtnStat 3;
BA_ "GenSigMaxLatency" SG_ 211 SrcBtnStat 30;
BA_ "GenSigCycleTime" SG_ 211 SW_Mute_ButtonStatus_6_ISig_5 100;
BA_ "GenSigCycleTimeActive" SG_ 211 SW_Mute_ButtonStatus_6_ISig_5 100;
BA_ "GenSigStartValue" SG_ 211 SW_Mute_ButtonStatus_6_ISig_5 3;
BA_ "GenSigCycleTime" SG_ 211 SW_PushToTalk_BtnStat_6_ISig_5 100;
BA_ "GenSigCycleTimeActive" SG_ 211 SW_PushToTalk_BtnStat_6_ISig_5 100;
BA_ "GenSigStartValue" SG_ 211 SW_PushToTalk_BtnStat_6_ISig_5 3;
BA_ "GenSigCycleTime" SG_ 211 SetDecrBtnStat 100;
BA_ "GenSigCycleTimeActive" SG_ 211 SetDecrBtnStat 100;
BA_ "GenSigStartValue" SG_ 211 SetDecrBtnStat 3;
BA_ "GenSigMaxLatency" SG_ 211 SetDecrBtnStat 30;
BA_ "GenSigCycleTime" SG_ 211 SW_Mute_ButtonStatus_6_3_ISig_5 100;
BA_ "GenSigCycleTimeActive" SG_ 211 SW_Mute_ButtonStatus_6_3_ISig_5 100;
BA_ "GenSigStartValue" SG_ 211 SW_Mute_ButtonStatus_6_3_ISig_5 3;
BA_ "GenSigCycleTime" SG_ 211 MarkerInterruptButtonStatus 100;
BA_ "GenSigCycleTimeActive" SG_ 211 MarkerInterruptButtonStatus 100;
BA_ "GenSigStartValue" SG_ 211 MarkerInterruptButtonStatus 3;
BA_ "GenSigMaxLatency" SG_ 211 MarkerInterruptButtonStatus 30;
BA_ "GenSigCycleTime" SG_ 1337 TPMSetAxleRefPres_Axle5_ISig_5 100;
BA_ "GenSigCycleTimeActive" SG_ 1337 TPMSetAxleRefPres_Axle5_ISig_5 100;
BA_ "GenSigStartValue" SG_ 1337 TPMSetAxleRefPres_Axle5_ISig_5 255;
BA_ "GenSigCycleTime" SG_ 1337 TPMPosOfWMReq_VehiclePos_ISig_5 100;
BA_ "GenSigCycleTimeActive" SG_ 1337 TPMPosOfWMReq_VehiclePos_ISig_5 100;
BA_ "GenSigStartValue" SG_ 1337 TPMPosOfWMReq_VehiclePos_ISig_5 7;
BA_ "GenSigCycleTime" SG_ 1337 TPMSetAxleRefPres_Axle4_ISig_5 100;
BA_ "GenSigCycleTimeActive" SG_ 1337 TPMSetAxleRefPres_Axle4_ISig_5 100;
BA_ "GenSigStartValue" SG_ 1337 TPMSetAxleRefPres_Axle4_ISig_5 255;
BA_ "GenSigCycleTime" SG_ 1337 TPMSetAxleRefPres_VehiclePos_ISi 100;
BA_ "GenSigCycleTimeActive" SG_ 1337 TPMSetAxleRefPres_VehiclePos_ISi 100;
BA_ "GenSigStartValue" SG_ 1337 TPMSetAxleRefPres_VehiclePos_ISi 7;
BA_ "SystemSignalLongSymbol" SG_ 1337 TPMSetAxleRefPres_VehiclePos_ISi "TPMSetAxleRefPres_VehiclePos_ISig_5";
BA_ "GenSigCycleTime" SG_ 1337 TPMSetAxleRefPres_Axle1_ISig_5 100;
BA_ "GenSigCycleTimeActive" SG_ 1337 TPMSetAxleRefPres_Axle1_ISig_5 100;
BA_ "GenSigStartValue" SG_ 1337 TPMSetAxleRefPres_Axle1_ISig_5 255;
BA_ "GenSigCycleTime" SG_ 1337 TPMSetAxleRefPres_Axle3_ISig_5 100;
BA_ "GenSigCycleTimeActive" SG_ 1337 TPMSetAxleRefPres_Axle3_ISig_5 100;
BA_ "GenSigStartValue" SG_ 1337 TPMSetAxleRefPres_Axle3_ISig_5 255;
BA_ "GenSigCycleTime" SG_ 1337 TPMSetAxleRefPres_Axle2_ISig_5 100;
BA_ "GenSigCycleTimeActive" SG_ 1337 TPMSetAxleRefPres_Axle2_ISig_5 100;
BA_ "GenSigStartValue" SG_ 1337 TPMSetAxleRefPres_Axle2_ISig_5 255;
BA_ "GenSigCycleTime" SG_ 1337 TPMPosOfWMReq_TireId_ISig_5 100;
BA_ "GenSigCycleTimeActive" SG_ 1337 TPMPosOfWMReq_TireId_ISig_5 100;
BA_ "GenSigCycleTime" SG_ 1336 TPMSetPresThresCfg_OverPres_ISig 100;
BA_ "GenSigCycleTimeActive" SG_ 1336 TPMSetPresThresCfg_OverPres_ISig 100;
BA_ "GenSigStartValue" SG_ 1336 TPMSetPresThresCfg_OverPres_ISig 255;
BA_ "SystemSignalLongSymbol" SG_ 1336 TPMSetPresThresCfg_OverPres_ISig "TPMSetPresThresCfg_OverPres_ISig_5";
BA_ "GenSigCycleTime" SG_ 1336 TPMSetPresThresCfg_VehiclePos_IS 100;
BA_ "GenSigCycleTimeActive" SG_ 1336 TPMSetPresThresCfg_VehiclePos_IS 100;
BA_ "GenSigStartValue" SG_ 1336 TPMSetPresThresCfg_VehiclePos_IS 7;
BA_ "SystemSignalLongSymbol" SG_ 1336 TPMSetPresThresCfg_VehiclePos_IS "TPMSetPresThresCfg_VehiclePos_ISig_5";
BA_ "GenSigCycleTime" SG_ 1336 TPMSetPresThresCfg_AxleNr_ISig_5 100;
BA_ "GenSigCycleTimeActive" SG_ 1336 TPMSetPresThresCfg_AxleNr_ISig_5 100;
BA_ "GenSigStartValue" SG_ 1336 TPMSetPresThresCfg_AxleNr_ISig_5 7;
BA_ "GenSigCycleTime" SG_ 1336 TPMSetPresThresCfg_ExtUnderPres_ 100;
BA_ "GenSigCycleTimeActive" SG_ 1336 TPMSetPresThresCfg_ExtUnderPres_ 100;
BA_ "GenSigStartValue" SG_ 1336 TPMSetPresThresCfg_ExtUnderPres_ 255;
BA_ "SystemSignalLongSymbol" SG_ 1336 TPMSetPresThresCfg_ExtUnderPres_ "TPMSetPresThresCfg_ExtUnderPres_ISig_5";
BA_ "GenSigCycleTime" SG_ 1336 TPMSetPresThresCfg_ExtOverPres_I 100;
BA_ "GenSigCycleTimeActive" SG_ 1336 TPMSetPresThresCfg_ExtOverPres_I 100;
BA_ "GenSigStartValue" SG_ 1336 TPMSetPresThresCfg_ExtOverPres_I 255;
BA_ "SystemSignalLongSymbol" SG_ 1336 TPMSetPresThresCfg_ExtOverPres_I "TPMSetPresThresCfg_ExtOverPres_ISig_5";
BA_ "GenSigCycleTime" SG_ 1336 TPMSetPresThresCfg_UnderPres_ISi 100;
BA_ "GenSigCycleTimeActive" SG_ 1336 TPMSetPresThresCfg_UnderPres_ISi 100;
BA_ "GenSigStartValue" SG_ 1336 TPMSetPresThresCfg_UnderPres_ISi 255;
BA_ "SystemSignalLongSymbol" SG_ 1336 TPMSetPresThresCfg_UnderPres_ISi "TPMSetPresThresCfg_UnderPres_ISig_5";
BA_ "GenSigSendType" SG_ 2671964824 DiagUUDTRespSig_F2_98_ISig_5 7;
BA_ "GenSigSendType" SG_ 2671964802 DiagUUDTRespSig_F2_82_ISig_5 7;
BA_ "GenSigSendType" SG_ 2671964772 DiagUUDTRespSig_F2_64_ISig_5 7;
BA_ "GenSigSendType" SG_ 2671964769 DiagUUDTRespSig_F2_61_ISig_5 7;
BA_ "GenSigSendType" SG_ 2671964736 DiagUUDTRespSig_F2_40_ISig_5 7;
BA_ "GenSigSendType" SG_ 2671834264 InternalTesterDiagSig_F4_98 7;
BA_ "GenSigSendType" SG_ 2671834242 InternalTesterDiagSig_F4_82_ISig 7;
BA_ "SystemSignalLongSymbol" SG_ 2671834242 InternalTesterDiagSig_F4_82_ISig "InternalTesterDiagSig_F4_82_ISig_5";
BA_ "GenSigSendType" SG_ 2671834212 InternalTesterDiagSig_F4_64 7;
BA_ "GenSigSendType" SG_ 2671834209 InternalTesterDiagSig_F4_61 7;
BA_ "GenSigSendType" SG_ 2671834176 InternalTesterDiagSig_F4_40 7;
BA_ "GenSigSendType" SG_ 2671810804 InternalTesterDiagSig_98_F4 7;
BA_ "GenSigSendType" SG_ 2671805172 InternalTesterDiagSig_82_F4_ISig 7;
BA_ "SystemSignalLongSymbol" SG_ 2671805172 InternalTesterDiagSig_82_F4_ISig "InternalTesterDiagSig_82_F4_ISig_5";
BA_ "GenSigSendType" SG_ 2671797492 InternalTesterDiagSig_64_F4 7;
BA_ "GenSigSendType" SG_ 2671796724 InternalTesterDiagSig_61_F4 7;
BA_ "GenSigSendType" SG_ 2671788276 InternalTesterDiagSig_40_F4 7;
BA_ "GenSigSendType" SG_ 1976 Debug_8_IC 1;
BA_ "GenSigSendType" SG_ 1975 Debug_7_IC 1;
BA_ "GenSigSendType" SG_ 1966 Debug_6_IC 1;
BA_ "GenSigSendType" SG_ 1959 Debug_5_IC 1;
BA_ "GenSigSendType" SG_ 1952 Debug_4_IC 1;
BA_ "GenSigSendType" SG_ 1945 Debug_3_IC 1;
BA_ "GenSigSendType" SG_ 1938 Debug_2_IC 1;
BA_ "GenSigSendType" SG_ 1931 Debug_1_IC 1;
BA_ "GenSigCycleTime" SG_ 163 Auto_ButtonStatus 100;
BA_ "GenSigCycleTimeActive" SG_ 163 Auto_ButtonStatus 100;
BA_ "GenSigStartValue" SG_ 163 Auto_ButtonStatus 3;
BA_ "GenSigMaxLatency" SG_ 163 Auto_ButtonStatus 20;
BA_ "GenSigCycleTime" SG_ 163 AirBlowerSpeed_FreeWheelStatus 100;
BA_ "GenSigCycleTimeActive" SG_ 163 AirBlowerSpeed_FreeWheelStatus 100;
BA_ "GenSigStartValue" SG_ 163 AirBlowerSpeed_FreeWheelStatus 15;
BA_ "GenSigMaxLatency" SG_ 163 AirBlowerSpeed_FreeWheelStatus 20;
BA_ "GenSigCycleTime" SG_ 163 AirFlowSelectionDownBtn_stat 100;
BA_ "GenSigCycleTimeActive" SG_ 163 AirFlowSelectionDownBtn_stat 100;
BA_ "GenSigStartValue" SG_ 163 AirFlowSelectionDownBtn_stat 3;
BA_ "GenSigMaxLatency" SG_ 163 AirFlowSelectionDownBtn_stat 20;
BA_ "GenSigCycleTime" SG_ 163 Temperature_FreeWheelStatus 100;
BA_ "GenSigCycleTimeActive" SG_ 163 Temperature_FreeWheelStatus 100;
BA_ "GenSigStartValue" SG_ 163 Temperature_FreeWheelStatus 15;
BA_ "GenSigMaxLatency" SG_ 163 Temperature_FreeWheelStatus 20;
BA_ "GenSigCycleTime" SG_ 163 AC_ButtonStatus 100;
BA_ "GenSigCycleTimeActive" SG_ 163 AC_ButtonStatus 100;
BA_ "GenSigStartValue" SG_ 163 AC_ButtonStatus 3;
BA_ "GenSigMaxLatency" SG_ 163 AC_ButtonStatus 20;
BA_ "GenSigCycleTime" SG_ 163 AirFlowSelectionUpBtn_stat 100;
BA_ "GenSigCycleTimeActive" SG_ 163 AirFlowSelectionUpBtn_stat 100;
BA_ "GenSigStartValue" SG_ 163 AirFlowSelectionUpBtn_stat 3;
BA_ "GenSigMaxLatency" SG_ 163 AirFlowSelectionUpBtn_stat 20;
BA_ "GenSigCycleTime" SG_ 163 AirFlowSelectionFrontBtn_stat 100;
BA_ "GenSigCycleTimeActive" SG_ 163 AirFlowSelectionFrontBtn_stat 100;
BA_ "GenSigStartValue" SG_ 163 AirFlowSelectionFrontBtn_stat 3;
BA_ "GenSigMaxLatency" SG_ 163 AirFlowSelectionFrontBtn_stat 20;
BA_ "GenSigCycleTime" SG_ 163 ParkHeaterCooler_ButtonStatus 100;
BA_ "GenSigCycleTimeActive" SG_ 163 ParkHeaterCooler_ButtonStatus 100;
BA_ "GenSigStartValue" SG_ 163 ParkHeaterCooler_ButtonStatus 3;
BA_ "GenSigMaxLatency" SG_ 163 ParkHeaterCooler_ButtonStatus 20;
BA_ "GenSigCycleTime" SG_ 163 Recirc_ButtonStatus 100;
BA_ "GenSigCycleTimeActive" SG_ 163 Recirc_ButtonStatus 100;
BA_ "GenSigStartValue" SG_ 163 Recirc_ButtonStatus 3;
BA_ "GenSigMaxLatency" SG_ 163 Recirc_ButtonStatus 20;
BA_ "GenSigCycleTime" SG_ 163 WindscreenDefrost_ButtonStatus 100;
BA_ "GenSigCycleTimeActive" SG_ 163 WindscreenDefrost_ButtonStatus 100;
BA_ "GenSigStartValue" SG_ 163 WindscreenDefrost_ButtonStatus 3;
BA_ "GenSigMaxLatency" SG_ 163 WindscreenDefrost_ButtonStatus 20;
BA_ "GenSigCycleTime" SG_ 1211 CabClimateFnRqst_FnPower 100;
BA_ "GenSigCycleTimeActive" SG_ 1211 CabClimateFnRqst_FnPower 100;
BA_ "GenSigStartValue" SG_ 1211 CabClimateFnRqst_FnPower 255;
BA_ "GenSigMaxLatency" SG_ 1211 CabClimateFnRqst_FnPower 1000;
BA_ "GenSigCycleTime" SG_ 1211 CabClimateFnRqst_FnNum 100;
BA_ "GenSigCycleTimeActive" SG_ 1211 CabClimateFnRqst_FnNum 100;
BA_ "GenSigStartValue" SG_ 1211 CabClimateFnRqst_FnNum 15;
BA_ "GenSigMaxLatency" SG_ 1211 CabClimateFnRqst_FnNum 1000;
BA_ "GenSigCycleTime" SG_ 703 LifeTimeEACC_TVCabConsEgy 100;
BA_ "GenSigCycleTimeActive" SG_ 703 LifeTimeEACC_TVCabConsEgy 100;
BA_ "GenSigStartValue" SG_ 703 LifeTimeEACC_TVCabConsEgy 65535;
BA_ "GenSigMaxLatency" SG_ 703 LifeTimeEACC_TVCabConsEgy 100;
BA_ "GenSigCycleTime" SG_ 703 LifeTimeEACC_TVBattConsEgy 100;
BA_ "GenSigCycleTimeActive" SG_ 703 LifeTimeEACC_TVBattConsEgy 100;
BA_ "GenSigStartValue" SG_ 703 LifeTimeEACC_TVBattConsEgy 65535;
BA_ "GenSigMaxLatency" SG_ 703 LifeTimeEACC_TVBattConsEgy 100;
BA_ "GenSigCycleTime" SG_ 703 EACC_TV_Voltage 100;
BA_ "GenSigCycleTimeActive" SG_ 703 EACC_TV_Voltage 100;
BA_ "GenSigStartValue" SG_ 703 EACC_TV_Voltage 255;
BA_ "GenSigMaxLatency" SG_ 703 EACC_TV_Voltage 100;
BA_ "GenSigCycleTime" SG_ 703 EACC_TV_Pwr 100;
BA_ "GenSigCycleTimeActive" SG_ 703 EACC_TV_Pwr 100;
BA_ "GenSigStartValue" SG_ 703 EACC_TV_Pwr 255;
BA_ "GenSigMaxLatency" SG_ 703 EACC_TV_Pwr 100;
BA_ "GenSigCycleTime" SG_ 405 ClimateAirDistStatus_Defrost 100;
BA_ "GenSigCycleTimeActive" SG_ 405 ClimateAirDistStatus_Defrost 100;
BA_ "GenSigStartValue" SG_ 405 ClimateAirDistStatus_Defrost 15;
BA_ "GenSigMaxLatency" SG_ 405 ClimateAirDistStatus_Defrost 50;
BA_ "GenSigCycleTime" SG_ 405 ACmode_Status 100;
BA_ "GenSigCycleTimeActive" SG_ 405 ACmode_Status 100;
BA_ "GenSigStartValue" SG_ 405 ACmode_Status 7;
BA_ "GenSigMaxLatency" SG_ 405 ACmode_Status 50;
BA_ "GenSigCycleTime" SG_ 405 ACStatus 100;
BA_ "GenSigCycleTimeActive" SG_ 405 ACStatus 100;
BA_ "GenSigStartValue" SG_ 405 ACStatus 3;
BA_ "GenSigMaxLatency" SG_ 405 ACStatus 50;
BA_ "GenSigCycleTime" SG_ 405 ClimateAirDistStatus_Vent 100;
BA_ "GenSigCycleTimeActive" SG_ 405 ClimateAirDistStatus_Vent 100;
BA_ "GenSigStartValue" SG_ 405 ClimateAirDistStatus_Vent 15;
BA_ "GenSigMaxLatency" SG_ 405 ClimateAirDistStatus_Vent 50;
BA_ "GenSigCycleTime" SG_ 405 ClimatePowerStatus 100;
BA_ "GenSigCycleTimeActive" SG_ 405 ClimatePowerStatus 100;
BA_ "GenSigStartValue" SG_ 405 ClimatePowerStatus 3;
BA_ "GenSigMaxLatency" SG_ 405 ClimatePowerStatus 50;
BA_ "GenSigCycleTime" SG_ 405 ClimateAutoStatus 100;
BA_ "GenSigCycleTimeActive" SG_ 405 ClimateAutoStatus 100;
BA_ "GenSigStartValue" SG_ 405 ClimateAutoStatus 7;
BA_ "GenSigMaxLatency" SG_ 405 ClimateAutoStatus 50;
BA_ "GenSigCycleTime" SG_ 405 AirRecirculationStatus 100;
BA_ "GenSigCycleTimeActive" SG_ 405 AirRecirculationStatus 100;
BA_ "GenSigStartValue" SG_ 405 AirRecirculationStatus 3;
BA_ "GenSigMaxLatency" SG_ 405 AirRecirculationStatus 50;
BA_ "GenSigCycleTime" SG_ 405 AutoDefogmode_Status 100;
BA_ "GenSigCycleTimeActive" SG_ 405 AutoDefogmode_Status 100;
BA_ "GenSigStartValue" SG_ 405 AutoDefogmode_Status 7;
BA_ "GenSigMaxLatency" SG_ 405 AutoDefogmode_Status 50;
BA_ "GenSigCycleTime" SG_ 405 ClimateAirDistStatus_AutoStatus 100;
BA_ "GenSigCycleTimeActive" SG_ 405 ClimateAirDistStatus_AutoStatus 100;
BA_ "GenSigStartValue" SG_ 405 ClimateAirDistStatus_AutoStatus 3;
BA_ "GenSigMaxLatency" SG_ 405 ClimateAirDistStatus_AutoStatus 50;
BA_ "GenSigCycleTime" SG_ 405 ClimateAirDistStatus_Floor 100;
BA_ "GenSigCycleTimeActive" SG_ 405 ClimateAirDistStatus_Floor 100;
BA_ "GenSigStartValue" SG_ 405 ClimateAirDistStatus_Floor 15;
BA_ "GenSigMaxLatency" SG_ 405 ClimateAirDistStatus_Floor 50;
BA_ "GenSigCycleTime" SG_ 405 CabTempStatus 100;
BA_ "GenSigCycleTimeActive" SG_ 405 CabTempStatus 100;
BA_ "GenSigStartValue" SG_ 405 CabTempStatus 127;
BA_ "GenSigMaxLatency" SG_ 405 CabTempStatus 50;
BA_ "GenSigCycleTime" SG_ 405 AutoBlowerLevel_Status 100;
BA_ "GenSigCycleTimeActive" SG_ 405 AutoBlowerLevel_Status 100;
BA_ "GenSigStartValue" SG_ 405 AutoBlowerLevel_Status 7;
BA_ "GenSigMaxLatency" SG_ 405 AutoBlowerLevel_Status 50;
BA_ "GenSigCycleTime" SG_ 405 AQSmode_Status 100;
BA_ "GenSigCycleTimeActive" SG_ 405 AQSmode_Status 100;
BA_ "GenSigStartValue" SG_ 405 AQSmode_Status 3;
BA_ "GenSigMaxLatency" SG_ 405 AQSmode_Status 50;
BA_ "GenSigCycleTime" SG_ 405 MaxDefrostStatus 100;
BA_ "GenSigCycleTimeActive" SG_ 405 MaxDefrostStatus 100;
BA_ "GenSigStartValue" SG_ 405 MaxDefrostStatus 3;
BA_ "GenSigMaxLatency" SG_ 405 MaxDefrostStatus 50;
BA_ "GenSigCycleTime" SG_ 405 HVACBlowerLevelStat_BlowerLevel 100;
BA_ "GenSigCycleTimeActive" SG_ 405 HVACBlowerLevelStat_BlowerLevel 100;
BA_ "GenSigStartValue" SG_ 405 HVACBlowerLevelStat_BlowerLevel 31;
BA_ "GenSigMaxLatency" SG_ 405 HVACBlowerLevelStat_BlowerLevel 50;
BA_ "GenSigCycleTime" SG_ 405 HVACBlowerLevelStat_AutoStatus 100;
BA_ "GenSigCycleTimeActive" SG_ 405 HVACBlowerLevelStat_AutoStatus 100;
BA_ "GenSigStartValue" SG_ 405 HVACBlowerLevelStat_AutoStatus 3;
BA_ "GenSigMaxLatency" SG_ 405 HVACBlowerLevelStat_AutoStatus 50;
BA_ "GenSigSendType" SG_ 1168 DiagFaultStat_CCM_FailTA 3;
BA_ "GenSigStartValue" SG_ 1168 DiagFaultStat_CCM_FailTA 255;
BA_ "GenSigMaxLatency" SG_ 1168 DiagFaultStat_CCM_FailTA 1000;
BA_ "NeedsUpdateBit" SG_ 1168 DiagFaultStat_CCM_FailTA 1;
BA_ "GenSigSendType" SG_ 1168 DiagFaultStat_CCM_FailTB 3;
BA_ "GenSigStartValue" SG_ 1168 DiagFaultStat_CCM_FailTB 255;
BA_ "GenSigMaxLatency" SG_ 1168 DiagFaultStat_CCM_FailTB 1000;
BA_ "NeedsUpdateBit" SG_ 1168 DiagFaultStat_CCM_FailTB 1;
BA_ "GenSigSendType" SG_ 1168 DiagFaultStat_CCM_DtcIdA 3;
BA_ "GenSigStartValue" SG_ 1168 DiagFaultStat_CCM_DtcIdA 65535;
BA_ "GenSigMaxLatency" SG_ 1168 DiagFaultStat_CCM_DtcIdA 1000;
BA_ "NeedsUpdateBit" SG_ 1168 DiagFaultStat_CCM_DtcIdA 1;
BA_ "GenSigSendType" SG_ 1168 DiagFaultStat_CCM_DtcIdB 3;
BA_ "GenSigStartValue" SG_ 1168 DiagFaultStat_CCM_DtcIdB 65535;
BA_ "GenSigMaxLatency" SG_ 1168 DiagFaultStat_CCM_DtcIdB 1000;
BA_ "NeedsUpdateBit" SG_ 1168 DiagFaultStat_CCM_DtcIdB 1;
BA_ "GenSigSendType" SG_ 1168 DiagFaultStat_CCM_sg_UB 7;
BA_ "GenSigSendType" SG_ 1168 DiagFaultStat_CCM_EcuAdr 3;
BA_ "GenSigStartValue" SG_ 1168 DiagFaultStat_CCM_EcuAdr 255;
BA_ "GenSigMaxLatency" SG_ 1168 DiagFaultStat_CCM_EcuAdr 1000;
BA_ "NeedsUpdateBit" SG_ 1168 DiagFaultStat_CCM_EcuAdr 1;
BA_ "GenSigCycleTime" SG_ 912 ParkingClimateAvailability 100;
BA_ "GenSigCycleTimeActive" SG_ 912 ParkingClimateAvailability 100;
BA_ "GenSigStartValue" SG_ 912 ParkingClimateAvailability 7;
BA_ "GenSigMaxLatency" SG_ 912 ParkingClimateAvailability 500;
BA_ "GenSigCycleTime" SG_ 912 CabTemperature_Status 100;
BA_ "GenSigCycleTimeActive" SG_ 912 CabTemperature_Status 100;
BA_ "GenSigStartValue" SG_ 912 CabTemperature_Status 8191;
BA_ "GenSigMaxLatency" SG_ 912 CabTemperature_Status 500;
BA_ "GenSigCycleTime" SG_ 656 LifeTimeTVECH_C_ConsEgy 100;
BA_ "GenSigCycleTimeActive" SG_ 656 LifeTimeTVECH_C_ConsEgy 100;
BA_ "GenSigStartValue" SG_ 656 LifeTimeTVECH_C_ConsEgy 255;
BA_ "GenSigMaxLatency" SG_ 656 LifeTimeTVECH_C_ConsEgy 100;
BA_ "GenSigCycleTime" SG_ 656 Req24VforClimateSystem 100;
BA_ "GenSigCycleTimeActive" SG_ 656 Req24VforClimateSystem 100;
BA_ "GenSigStartValue" SG_ 656 Req24VforClimateSystem 3;
BA_ "GenSigMaxLatency" SG_ 656 Req24VforClimateSystem 100;
BA_ "GenSigCycleTime" SG_ 656 TVECH_C_Pwr 100;
BA_ "GenSigCycleTimeActive" SG_ 656 TVECH_C_Pwr 100;
BA_ "GenSigStartValue" SG_ 656 TVECH_C_Pwr 255;
BA_ "GenSigMaxLatency" SG_ 656 TVECH_C_Pwr 100;
BA_ "GenSigCycleTime" SG_ 656 TVECH_C_Voltage 100;
BA_ "GenSigCycleTimeActive" SG_ 656 TVECH_C_Voltage 100;
BA_ "GenSigStartValue" SG_ 656 TVECH_C_Voltage 1023;
BA_ "GenSigMaxLatency" SG_ 656 TVECH_C_Voltage 100;
BA_ "GenSigCycleTime" SG_ 656 AcCoolantPumpEngagementRequest_I 100;
BA_ "GenSigCycleTimeActive" SG_ 656 AcCoolantPumpEngagementRequest_I 100;
BA_ "GenSigStartValue" SG_ 656 AcCoolantPumpEngagementRequest_I 255;
BA_ "GenSigMaxLatency" SG_ 656 AcCoolantPumpEngagementRequest_I 100;
BA_ "SystemSignalLongSymbol" SG_ 656 AcCoolantPumpEngagementRequest_I "AcCoolantPumpEngagementRequest_ISig_5";
BA_ "GenSigCycleTime" SG_ 402 PHTimer3_stat_Minutes 100;
BA_ "GenSigCycleTimeActive" SG_ 402 PHTimer3_stat_Minutes 100;
BA_ "GenSigStartValue" SG_ 402 PHTimer3_stat_Minutes 255;
BA_ "GenSigMaxLatency" SG_ 402 PHTimer3_stat_Minutes 50;
BA_ "GenSigCycleTime" SG_ 402 PHTimer2_stat_StartDay 100;
BA_ "GenSigCycleTimeActive" SG_ 402 PHTimer2_stat_StartDay 100;
BA_ "GenSigStartValue" SG_ 402 PHTimer2_stat_StartDay 15;
BA_ "GenSigMaxLatency" SG_ 402 PHTimer2_stat_StartDay 50;
BA_ "GenSigCycleTime" SG_ 402 PHTimer2_stat_Recurrence 100;
BA_ "GenSigCycleTimeActive" SG_ 402 PHTimer2_stat_Recurrence 100;
BA_ "GenSigStartValue" SG_ 402 PHTimer2_stat_Recurrence 15;
BA_ "GenSigMaxLatency" SG_ 402 PHTimer2_stat_Recurrence 50;
BA_ "GenSigCycleTime" SG_ 402 PHTimer3_stat_Temp 100;
BA_ "GenSigCycleTimeActive" SG_ 402 PHTimer3_stat_Temp 100;
BA_ "GenSigStartValue" SG_ 402 PHTimer3_stat_Temp 31;
BA_ "GenSigMaxLatency" SG_ 402 PHTimer3_stat_Temp 50;
BA_ "GenSigCycleTime" SG_ 402 PHTimer2_stat_Temp 100;
BA_ "GenSigCycleTimeActive" SG_ 402 PHTimer2_stat_Temp 100;
BA_ "GenSigStartValue" SG_ 402 PHTimer2_stat_Temp 31;
BA_ "GenSigMaxLatency" SG_ 402 PHTimer2_stat_Temp 50;
BA_ "GenSigCycleTime" SG_ 402 PHTimer3_stat_StartDay 100;
BA_ "GenSigCycleTimeActive" SG_ 402 PHTimer3_stat_StartDay 100;
BA_ "GenSigStartValue" SG_ 402 PHTimer3_stat_StartDay 15;
BA_ "GenSigMaxLatency" SG_ 402 PHTimer3_stat_StartDay 50;
BA_ "GenSigCycleTime" SG_ 402 PHTimer2_stat_Hours 100;
BA_ "GenSigCycleTimeActive" SG_ 402 PHTimer2_stat_Hours 100;
BA_ "GenSigStartValue" SG_ 402 PHTimer2_stat_Hours 255;
BA_ "GenSigMaxLatency" SG_ 402 PHTimer2_stat_Hours 50;
BA_ "GenSigCycleTime" SG_ 402 PHTimer3_stat_Recurrence 100;
BA_ "GenSigCycleTimeActive" SG_ 402 PHTimer3_stat_Recurrence 100;
BA_ "GenSigStartValue" SG_ 402 PHTimer3_stat_Recurrence 15;
BA_ "GenSigMaxLatency" SG_ 402 PHTimer3_stat_Recurrence 50;
BA_ "GenSigCycleTime" SG_ 402 PHTimer2_stat_Minutes 100;
BA_ "GenSigCycleTimeActive" SG_ 402 PHTimer2_stat_Minutes 100;
BA_ "GenSigStartValue" SG_ 402 PHTimer2_stat_Minutes 255;
BA_ "GenSigMaxLatency" SG_ 402 PHTimer2_stat_Minutes 50;
BA_ "GenSigCycleTime" SG_ 402 PHTimer2_stat_Status 100;
BA_ "GenSigCycleTimeActive" SG_ 402 PHTimer2_stat_Status 100;
BA_ "GenSigStartValue" SG_ 402 PHTimer2_stat_Status 3;
BA_ "GenSigMaxLatency" SG_ 402 PHTimer2_stat_Status 50;
BA_ "GenSigCycleTime" SG_ 402 PHTimer3_stat_Status 100;
BA_ "GenSigCycleTimeActive" SG_ 402 PHTimer3_stat_Status 100;
BA_ "GenSigStartValue" SG_ 402 PHTimer3_stat_Status 3;
BA_ "GenSigMaxLatency" SG_ 402 PHTimer3_stat_Status 50;
BA_ "GenSigCycleTime" SG_ 402 PHTimer3_stat_Hours 100;
BA_ "GenSigCycleTimeActive" SG_ 402 PHTimer3_stat_Hours 100;
BA_ "GenSigStartValue" SG_ 402 PHTimer3_stat_Hours 255;
BA_ "GenSigMaxLatency" SG_ 402 PHTimer3_stat_Hours 50;
BA_ "GenSigCycleTime" SG_ 401 PHTimer1_stat_Recurrence 100;
BA_ "GenSigCycleTimeActive" SG_ 401 PHTimer1_stat_Recurrence 100;
BA_ "GenSigStartValue" SG_ 401 PHTimer1_stat_Recurrence 15;
BA_ "GenSigMaxLatency" SG_ 401 PHTimer1_stat_Recurrence 50;
BA_ "GenSigCycleTime" SG_ 401 PHTimer1_stat_Temp 100;
BA_ "GenSigCycleTimeActive" SG_ 401 PHTimer1_stat_Temp 100;
BA_ "GenSigStartValue" SG_ 401 PHTimer1_stat_Temp 31;
BA_ "GenSigMaxLatency" SG_ 401 PHTimer1_stat_Temp 50;
BA_ "GenSigCycleTime" SG_ 401 PHTimer1_stat_Duration 100;
BA_ "GenSigCycleTimeActive" SG_ 401 PHTimer1_stat_Duration 100;
BA_ "GenSigStartValue" SG_ 401 PHTimer1_stat_Duration 127;
BA_ "GenSigMaxLatency" SG_ 401 PHTimer1_stat_Duration 50;
BA_ "GenSigCycleTime" SG_ 401 PHTimer1_stat_Status 100;
BA_ "GenSigCycleTimeActive" SG_ 401 PHTimer1_stat_Status 100;
BA_ "GenSigStartValue" SG_ 401 PHTimer1_stat_Status 3;
BA_ "GenSigMaxLatency" SG_ 401 PHTimer1_stat_Status 50;
BA_ "GenSigCycleTime" SG_ 401 PHTimer_rqst_Hours 100;
BA_ "GenSigCycleTimeActive" SG_ 401 PHTimer_rqst_Hours 100;
BA_ "GenSigStartValue" SG_ 401 PHTimer_rqst_Hours 255;
BA_ "GenSigMaxLatency" SG_ 401 PHTimer_rqst_Hours 50;
BA_ "GenSigCycleTime" SG_ 401 PHTimer_rqst_SetAlarmOper 100;
BA_ "GenSigCycleTimeActive" SG_ 401 PHTimer_rqst_SetAlarmOper 100;
BA_ "GenSigStartValue" SG_ 401 PHTimer_rqst_SetAlarmOper 7;
BA_ "GenSigMaxLatency" SG_ 401 PHTimer_rqst_SetAlarmOper 50;
BA_ "GenSigCycleTime" SG_ 401 PHTimer_rqst_Minutes 100;
BA_ "GenSigCycleTimeActive" SG_ 401 PHTimer_rqst_Minutes 100;
BA_ "GenSigStartValue" SG_ 401 PHTimer_rqst_Minutes 255;
BA_ "GenSigMaxLatency" SG_ 401 PHTimer_rqst_Minutes 50;
BA_ "GenSigCycleTime" SG_ 401 PHTimer1_stat_Hours 100;
BA_ "GenSigCycleTimeActive" SG_ 401 PHTimer1_stat_Hours 100;
BA_ "GenSigStartValue" SG_ 401 PHTimer1_stat_Hours 255;
BA_ "GenSigMaxLatency" SG_ 401 PHTimer1_stat_Hours 50;
BA_ "GenSigCycleTime" SG_ 401 PHTimer1_stat_Minutes 100;
BA_ "GenSigCycleTimeActive" SG_ 401 PHTimer1_stat_Minutes 100;
BA_ "GenSigStartValue" SG_ 401 PHTimer1_stat_Minutes 255;
BA_ "GenSigMaxLatency" SG_ 401 PHTimer1_stat_Minutes 50;
BA_ "GenSigCycleTime" SG_ 401 PHTimer_rqst_DayOfWeekRq 100;
BA_ "GenSigCycleTimeActive" SG_ 401 PHTimer_rqst_DayOfWeekRq 100;
BA_ "GenSigStartValue" SG_ 401 PHTimer_rqst_DayOfWeekRq 15;
BA_ "GenSigMaxLatency" SG_ 401 PHTimer_rqst_DayOfWeekRq 50;
BA_ "GenSigCycleTime" SG_ 401 PHTimer1_stat_StartDay 100;
BA_ "GenSigCycleTimeActive" SG_ 401 PHTimer1_stat_StartDay 100;
BA_ "GenSigStartValue" SG_ 401 PHTimer1_stat_StartDay 15;
BA_ "GenSigMaxLatency" SG_ 401 PHTimer1_stat_StartDay 50;
BA_ "GenSigCycleTime" SG_ 400 WindscreenDefrostInd_cmd 100;
BA_ "GenSigCycleTimeActive" SG_ 400 WindscreenDefrostInd_cmd 100;
BA_ "GenSigMaxLatency" SG_ 400 WindscreenDefrostInd_cmd 50;
BA_ "GenSigCycleTime" SG_ 400 ParkingHeater_IndicationCmd 100;
BA_ "GenSigCycleTimeActive" SG_ 400 ParkingHeater_IndicationCmd 100;
BA_ "GenSigMaxLatency" SG_ 400 ParkingHeater_IndicationCmd 50;
BA_ "GenSigCycleTime" SG_ 400 AC_CompressorClutchCmd_ISig_5 100;
BA_ "GenSigCycleTimeActive" SG_ 400 AC_CompressorClutchCmd_ISig_5 100;
BA_ "GenSigStartValue" SG_ 400 AC_CompressorClutchCmd_ISig_5 3;
BA_ "GenSigMaxLatency" SG_ 400 AC_CompressorClutchCmd_ISig_5 50;
BA_ "GenSigCycleTime" SG_ 400 ParkingHeaterCleaning_Rqst 100;
BA_ "GenSigCycleTimeActive" SG_ 400 ParkingHeaterCleaning_Rqst 100;
BA_ "GenSigStartValue" SG_ 400 ParkingHeaterCleaning_Rqst 3;
BA_ "GenSigMaxLatency" SG_ 400 ParkingHeaterCleaning_Rqst 50;
BA_ "GenSigCycleTime" SG_ 400 TemperatureRqstIndication_cmd 100;
BA_ "GenSigCycleTimeActive" SG_ 400 TemperatureRqstIndication_cmd 100;
BA_ "GenSigStartValue" SG_ 400 TemperatureRqstIndication_cmd 31;
BA_ "GenSigMaxLatency" SG_ 400 TemperatureRqstIndication_cmd 50;
BA_ "GenSigCycleTime" SG_ 400 ParkingClimate_IndicationCmd 100;
BA_ "GenSigCycleTimeActive" SG_ 400 ParkingClimate_IndicationCmd 100;
BA_ "GenSigStartValue" SG_ 400 ParkingClimate_IndicationCmd 7;
BA_ "GenSigMaxLatency" SG_ 400 ParkingClimate_IndicationCmd 50;
BA_ "GenSigCycleTime" SG_ 400 ACmode_IndicationCmd 100;
BA_ "GenSigCycleTimeActive" SG_ 400 ACmode_IndicationCmd 100;
BA_ "GenSigMaxLatency" SG_ 400 ACmode_IndicationCmd 50;
BA_ "GenSigCycleTime" SG_ 400 TempRqst_cmd 100;
BA_ "GenSigCycleTimeActive" SG_ 400 TempRqst_cmd 100;
BA_ "GenSigStartValue" SG_ 400 TempRqst_cmd 31;
BA_ "GenSigMaxLatency" SG_ 400 TempRqst_cmd 50;
BA_ "GenSigCycleTime" SG_ 400 ExtraHeating_status 100;
BA_ "GenSigCycleTimeActive" SG_ 400 ExtraHeating_status 100;
BA_ "GenSigStartValue" SG_ 400 ExtraHeating_status 3;
BA_ "GenSigMaxLatency" SG_ 400 ExtraHeating_status 50;
BA_ "GenSigCycleTime" SG_ 400 CabInteriorTempVentilated_Stat 100;
BA_ "GenSigCycleTimeActive" SG_ 400 CabInteriorTempVentilated_Stat 100;
BA_ "GenSigStartValue" SG_ 400 CabInteriorTempVentilated_Stat 1023;
BA_ "GenSigMaxLatency" SG_ 400 CabInteriorTempVentilated_Stat 50;
BA_ "GenSigCycleTime" SG_ 400 ShortStopHeater_cmd_ISig_5 100;
BA_ "GenSigCycleTimeActive" SG_ 400 ShortStopHeater_cmd_ISig_5 100;
BA_ "GenSigStartValue" SG_ 400 ShortStopHeater_cmd_ISig_5 3;
BA_ "GenSigMaxLatency" SG_ 400 ShortStopHeater_cmd_ISig_5 50;
BA_ "GenSigCycleTime" SG_ 400 ACCoolingFanSpeedRequest_CCM 100;
BA_ "GenSigCycleTimeActive" SG_ 400 ACCoolingFanSpeedRequest_CCM 100;
BA_ "GenSigStartValue" SG_ 400 ACCoolingFanSpeedRequest_CCM 65535;
BA_ "GenSigMaxLatency" SG_ 400 ACCoolingFanSpeedRequest_CCM 50;
BA_ "GenSigSendType" SG_ 1717 AnmSig_VCM_CAN05 1;
BA_ "GenSigCycleTime" SG_ 1717 AnmSig_VCM_CAN05 100;
BA_ "GenSigCycleTimeActive" SG_ 1717 AnmSig_VCM_CAN05 100;
BA_ "MmAnSignal" SG_ 1717 AnmSig_VCM_CAN05 1;
BA_ "GenSigSendType" SG_ 1718 AnmSig_SCIM_CAN05 1;
BA_ "GenSigCycleTime" SG_ 1718 AnmSig_SCIM_CAN05 100;
BA_ "GenSigCycleTimeActive" SG_ 1718 AnmSig_SCIM_CAN05 100;
BA_ "MmAnSignal" SG_ 1718 AnmSig_SCIM_CAN05 1;
BA_ "GenSigSendType" SG_ 1716 AnmSig_IC_CAN05 1;
BA_ "GenSigCycleTime" SG_ 1716 AnmSig_IC_CAN05 100;
BA_ "GenSigCycleTimeActive" SG_ 1716 AnmSig_IC_CAN05 100;
BA_ "MmAnSignal" SG_ 1716 AnmSig_IC_CAN05 1;
BA_ "GenSigSendType" SG_ 1719 AnmSig_CCM_CAN05 1;
BA_ "GenSigCycleTime" SG_ 1719 AnmSig_CCM_CAN05 100;
BA_ "GenSigCycleTimeActive" SG_ 1719 AnmSig_CCM_CAN05 100;
BA_ "MmAnSignal" SG_ 1719 AnmSig_CCM_CAN05 1;
BA_REL_ "GenSigFirstTimeoutTime" BU_SG_REL_ VCM SG_ 179 FerryFunctionRequest_ISig_5 3000;
BA_REL_ "GenSigTimeoutTime" BU_SG_REL_ VCM SG_ 179 FerryFunctionRequest_ISig_5 120;
BA_REL_ "GenSigFirstTimeoutTime" BU_SG_REL_ VCM SG_ 179 KneelingChangeRequest_ISig_5 3000;
BA_REL_ "GenSigTimeoutTime" BU_SG_REL_ VCM SG_ 179 KneelingChangeRequest_ISig_5 120;
BA_REL_ "GenSigFirstTimeoutTime" BU_SG_REL_ VCM SG_ 179 LiftAxle1AutoLiftRequest_ISig_5 3000;
BA_REL_ "GenSigTimeoutTime" BU_SG_REL_ VCM SG_ 179 LiftAxle1AutoLiftRequest_ISig_5 120;
BA_REL_ "GenSigFirstTimeoutTime" BU_SG_REL_ VCM SG_ 179 FPBRChangeReq_ISig_5 3000;
BA_REL_ "GenSigTimeoutTime" BU_SG_REL_ VCM SG_ 179 FPBRChangeReq_ISig_5 120;
BA_REL_ "GenSigFirstTimeoutTime" BU_SG_REL_ VCM SG_ 179 LightMode_Status_Ctr_1 3000;
BA_REL_ "GenSigTimeoutTime" BU_SG_REL_ VCM SG_ 179 LightMode_Status_Ctr_1 120;
BA_REL_ "GenSigFirstTimeoutTime" BU_SG_REL_ VCM SG_ 179 LevelRequest_RollRequest_ISig_5 3000;
BA_REL_ "GenSigTimeoutTime" BU_SG_REL_ VCM SG_ 179 LevelRequest_RollRequest_ISig_5 120;
BA_REL_ "GenSigFirstTimeoutTime" BU_SG_REL_ VCM SG_ 179 AltLoadDistribution_rqst_ISig_5 3000;
BA_REL_ "GenSigTimeoutTime" BU_SG_REL_ VCM SG_ 179 AltLoadDistribution_rqst_ISig_5 120;
BA_REL_ "GenSigFirstTimeoutTime" BU_SG_REL_ VCM SG_ 179 LoadDistributionChangeRequest_IS 3000;
BA_REL_ "GenSigTimeoutTime" BU_SG_REL_ VCM SG_ 179 LoadDistributionChangeRequest_IS 120;
BA_REL_ "GenSigFirstTimeoutTime" BU_SG_REL_ VCM SG_ 179 LiftAxle1LiftPositionRequest_ISi 3000;
BA_REL_ "GenSigTimeoutTime" BU_SG_REL_ VCM SG_ 179 LiftAxle1LiftPositionRequest_ISi 120;
BA_REL_ "GenSigFirstTimeoutTime" BU_SG_REL_ VCM SG_ 179 ReverseWarning_rqst 3000;
BA_REL_ "GenSigTimeoutTime" BU_SG_REL_ VCM SG_ 179 ReverseWarning_rqst 120;
BA_REL_ "GenSigFirstTimeoutTime" BU_SG_REL_ VCM SG_ 179 FerryFunctionSwitchChangeReq_ISi 3000;
BA_REL_ "GenSigTimeoutTime" BU_SG_REL_ VCM SG_ 179 FerryFunctionSwitchChangeReq_ISi 120;
BA_REL_ "GenSigFirstTimeoutTime" BU_SG_REL_ VCM SG_ 179 BackToDriveReq_ISig_5 3000;
BA_REL_ "GenSigTimeoutTime" BU_SG_REL_ VCM SG_ 179 BackToDriveReq_ISig_5 120;
BA_REL_ "GenSigFirstTimeoutTime" BU_SG_REL_ VCM SG_ 179 FogLightFront_ButtonStatus_1 3000;
BA_REL_ "GenSigTimeoutTime" BU_SG_REL_ VCM SG_ 179 FogLightFront_ButtonStatus_1 120;
BA_REL_ "GenSigFirstTimeoutTime" BU_SG_REL_ VCM SG_ 179 LevelRequest_RearAxle_ISig_5 3000;
BA_REL_ "GenSigTimeoutTime" BU_SG_REL_ VCM SG_ 179 LevelRequest_RearAxle_ISig_5 120;
BA_REL_ "GenSigFirstTimeoutTime" BU_SG_REL_ VCM SG_ 179 LiftAxle1DirectControl_ISig_5 3000;
BA_REL_ "GenSigTimeoutTime" BU_SG_REL_ VCM SG_ 179 LiftAxle1DirectControl_ISig_5 120;
BA_REL_ "GenSigFirstTimeoutTime" BU_SG_REL_ VCM SG_ 179 ECSStandByRequest_ISig_5 3000;
BA_REL_ "GenSigTimeoutTime" BU_SG_REL_ VCM SG_ 179 ECSStandByRequest_ISig_5 120;
BA_REL_ "GenSigFirstTimeoutTime" BU_SG_REL_ VCM SG_ 179 LiftAxle2LiftPositionRequest_ISi 3000;
BA_REL_ "GenSigTimeoutTime" BU_SG_REL_ VCM SG_ 179 LiftAxle2LiftPositionRequest_ISi 120;
BA_REL_ "GenSigFirstTimeoutTime" BU_SG_REL_ VCM SG_ 179 FogLightRear_ButtonStatus_1 3000;
BA_REL_ "GenSigTimeoutTime" BU_SG_REL_ VCM SG_ 179 FogLightRear_ButtonStatus_1 120;
BA_REL_ "GenSigFirstTimeoutTime" BU_SG_REL_ VCM SG_ 179 LevelStrokeRequest_ISig_5 3000;
BA_REL_ "GenSigTimeoutTime" BU_SG_REL_ VCM SG_ 179 LevelStrokeRequest_ISig_5 120;
BA_REL_ "GenSigFirstTimeoutTime" BU_SG_REL_ VCM SG_ 179 RampLevelRequest_ISig_5 3000;
BA_REL_ "GenSigTimeoutTime" BU_SG_REL_ VCM SG_ 179 RampLevelRequest_ISig_5 120;
BA_REL_ "GenSigFirstTimeoutTime" BU_SG_REL_ VCM SG_ 179 LevelRequest_FrontAxle_ISig_5 3000;
BA_REL_ "GenSigTimeoutTime" BU_SG_REL_ VCM SG_ 179 LevelRequest_FrontAxle_ISig_5 120;
BA_REL_ "GenSigFirstTimeoutTime" BU_SG_REL_ VCM SG_ 179 LiftAxle2AutoLiftRequest_ISig_5 3000;
BA_REL_ "GenSigTimeoutTime" BU_SG_REL_ VCM SG_ 179 LiftAxle2AutoLiftRequest_ISig_5 120;
BA_REL_ "GenSigFirstTimeoutTime" BU_SG_REL_ VCM SG_ 179 RampLevelStorageRequest_ISig_5 3000;
BA_REL_ "GenSigTimeoutTime" BU_SG_REL_ VCM SG_ 179 RampLevelStorageRequest_ISig_5 120;
BA_REL_ "GenSigFirstTimeoutTime" BU_SG_REL_ VCM SG_ 179 RideHeightStorageRequest_ISig_5 3000;
BA_REL_ "GenSigTimeoutTime" BU_SG_REL_ VCM SG_ 179 RideHeightStorageRequest_ISig_5 120;
BA_REL_ "GenSigFirstTimeoutTime" BU_SG_REL_ CCM SG_ 419 ClimateAutoRequest 3000;
BA_REL_ "GenSigTimeoutTime" BU_SG_REL_ CCM SG_ 419 ClimateAutoRequest 600;
BA_REL_ "GenSigFirstTimeoutTime" BU_SG_REL_ CCM SG_ 419 ClimateAirDistRequest_Vent 3000;
BA_REL_ "GenSigTimeoutTime" BU_SG_REL_ CCM SG_ 419 ClimateAirDistRequest_Vent 600;
BA_REL_ "GenSigFirstTimeoutTime" BU_SG_REL_ CCM SG_ 419 HVACBlowerRequest 3000;
BA_REL_ "GenSigTimeoutTime" BU_SG_REL_ CCM SG_ 419 HVACBlowerRequest 600;
BA_REL_ "GenSigFirstTimeoutTime" BU_SG_REL_ CCM SG_ 419 ACModeRqst 3000;
BA_REL_ "GenSigTimeoutTime" BU_SG_REL_ CCM SG_ 419 ACModeRqst 600;
BA_REL_ "GenSigFirstTimeoutTime" BU_SG_REL_ CCM SG_ 419 ParkingClimateRequest 3000;
BA_REL_ "GenSigTimeoutTime" BU_SG_REL_ CCM SG_ 419 ParkingClimateRequest 600;
BA_REL_ "GenSigFirstTimeoutTime" BU_SG_REL_ CCM SG_ 419 AutoBlowerLevelRqst 3000;
BA_REL_ "GenSigTimeoutTime" BU_SG_REL_ CCM SG_ 419 AutoBlowerLevelRqst 600;
BA_REL_ "GenSigFirstTimeoutTime" BU_SG_REL_ CCM SG_ 419 MaxDefrostRequest 3000;
BA_REL_ "GenSigTimeoutTime" BU_SG_REL_ CCM SG_ 419 MaxDefrostRequest 600;
BA_REL_ "GenSigFirstTimeoutTime" BU_SG_REL_ CCM SG_ 419 AQSModeRqst 3000;
BA_REL_ "GenSigTimeoutTime" BU_SG_REL_ CCM SG_ 419 AQSModeRqst 600;
BA_REL_ "GenSigFirstTimeoutTime" BU_SG_REL_ CCM SG_ 419 CabTempRequest 3000;
BA_REL_ "GenSigTimeoutTime" BU_SG_REL_ CCM SG_ 419 CabTempRequest 600;
BA_REL_ "GenSigFirstTimeoutTime" BU_SG_REL_ CCM SG_ 419 ClimateAirDistRequest_Floor 3000;
BA_REL_ "GenSigTimeoutTime" BU_SG_REL_ CCM SG_ 419 ClimateAirDistRequest_Floor 600;
BA_REL_ "GenSigFirstTimeoutTime" BU_SG_REL_ CCM SG_ 419 AirRecirculationRequest 3000;
BA_REL_ "GenSigTimeoutTime" BU_SG_REL_ CCM SG_ 419 AirRecirculationRequest 600;
BA_REL_ "GenSigFirstTimeoutTime" BU_SG_REL_ CCM SG_ 419 ACRequest 3000;
BA_REL_ "GenSigTimeoutTime" BU_SG_REL_ CCM SG_ 419 ACRequest 600;
BA_REL_ "GenSigFirstTimeoutTime" BU_SG_REL_ CCM SG_ 419 ClimateAirDistRequest_Defrost 3000;
BA_REL_ "GenSigTimeoutTime" BU_SG_REL_ CCM SG_ 419 ClimateAirDistRequest_Defrost 600;
BA_REL_ "GenSigFirstTimeoutTime" BU_SG_REL_ CCM SG_ 419 ClimatePowerRequest 3000;
BA_REL_ "GenSigTimeoutTime" BU_SG_REL_ CCM SG_ 419 ClimatePowerRequest 600;
BA_REL_ "GenSigFirstTimeoutTime" BU_SG_REL_ CCM SG_ 419 AutoDefogModeRqst 3000;
BA_REL_ "GenSigTimeoutTime" BU_SG_REL_ CCM SG_ 419 AutoDefogModeRqst 600;
BA_REL_ "GenSigFirstTimeoutTime" BU_SG_REL_ VCM SG_ 1184 FasDampingSetting_rqst_ISig_5 24000;
BA_REL_ "GenSigTimeoutTime" BU_SG_REL_ VCM SG_ 1184 FasDampingSetting_rqst_ISig_5 6000;
BA_REL_ "GenSigFirstTimeoutTime" BU_SG_REL_ VCM SG_ 1184 FasPersonalSettingsButton_rqst_I 24000;
BA_REL_ "GenSigTimeoutTime" BU_SG_REL_ VCM SG_ 1184 FasPersonalSettingsButton_rqst_I 6000;
BA_REL_ "GenSigFirstTimeoutTime" BU_SG_REL_ VCM SG_ 1184 FasStiffnessCurveSetting_rqst_IS 24000;
BA_REL_ "GenSigTimeoutTime" BU_SG_REL_ VCM SG_ 1184 FasStiffnessCurveSetting_rqst_IS 6000;
BA_REL_ "GenSigFirstTimeoutTime" BU_SG_REL_ VCM SG_ 1184 FasDriver_rqst_ISig_5 24000;
BA_REL_ "GenSigTimeoutTime" BU_SG_REL_ VCM SG_ 1184 FasDriver_rqst_ISig_5 6000;
BA_REL_ "GenSigFirstTimeoutTime" BU_SG_REL_ VCM SG_ 1184 FasUsrDefinedStorage_rqst_ISig_5 24000;
BA_REL_ "GenSigTimeoutTime" BU_SG_REL_ VCM SG_ 1184 FasUsrDefinedStorage_rqst_ISig_5 6000;
BA_REL_ "GenSigFirstTimeoutTime" BU_SG_REL_ VCM SG_ 1184 FasStiffStraightSetting_rqst_ISi 24000;
BA_REL_ "GenSigTimeoutTime" BU_SG_REL_ VCM SG_ 1184 FasStiffStraightSetting_rqst_ISi 6000;
BA_REL_ "GenSigFirstTimeoutTime" BU_SG_REL_ VCM SG_ 1184 FasLowSpeedReturnSetting_rqst_IS 24000;
BA_REL_ "GenSigTimeoutTime" BU_SG_REL_ VCM SG_ 1184 FasLowSpeedReturnSetting_rqst_IS 6000;
BA_REL_ "GenSigFirstTimeoutTime" BU_SG_REL_ VCM SG_ 1184 FasManualOffsetSetting_rqst_ISig 24000;
BA_REL_ "GenSigTimeoutTime" BU_SG_REL_ VCM SG_ 1184 FasManualOffsetSetting_rqst_ISig 6000;
BA_REL_ "GenSigFirstTimeoutTime" BU_SG_REL_ VCM SG_ 932 DPF_ManualRegenerateRequest_ISig 12000;
BA_REL_ "GenSigTimeoutTime" BU_SG_REL_ VCM SG_ 932 DPF_ManualRegenerateRequest_ISig 3000;
BA_REL_ "GenSigFirstTimeoutTime" BU_SG_REL_ VCM SG_ 932 DPF_ManualRegenerateInhibit_ISig 12000;
BA_REL_ "GenSigTimeoutTime" BU_SG_REL_ VCM SG_ 932 DPF_ManualRegenerateInhibit_ISig 3000;
BA_REL_ "GenSigFirstTimeoutTime" BU_SG_REL_ VCM SG_ 932 DPF_ManualRegenerateTimeReq_ISig 12000;
BA_REL_ "GenSigTimeoutTime" BU_SG_REL_ VCM SG_ 932 DPF_ManualRegenerateTimeReq_ISig 3000;
BA_REL_ "GenSigFirstTimeoutTime" BU_SG_REL_ VCM SG_ 930 OBDRelDTC_IC_DrvngCycleB 12000;
BA_REL_ "GenSigTimeoutTime" BU_SG_REL_ VCM SG_ 930 OBDRelDTC_IC_DrvngCycleB 3000;
BA_REL_ "GenSigFirstTimeoutTime" BU_SG_REL_ VCM SG_ 930 OBDRelDTC_IC_EvalResultA 12000;
BA_REL_ "GenSigTimeoutTime" BU_SG_REL_ VCM SG_ 930 OBDRelDTC_IC_EvalResultA 3000;
BA_REL_ "GenSigFirstTimeoutTime" BU_SG_REL_ VCM SG_ 930 OBDRelDTC_IC_EvalResultB 12000;
BA_REL_ "GenSigTimeoutTime" BU_SG_REL_ VCM SG_ 930 OBDRelDTC_IC_EvalResultB 3000;
BA_REL_ "GenSigFirstTimeoutTime" BU_SG_REL_ VCM SG_ 930 OBDRelDTC_IC_EvalStatA 12000;
BA_REL_ "GenSigTimeoutTime" BU_SG_REL_ VCM SG_ 930 OBDRelDTC_IC_EvalStatA 3000;
BA_REL_ "GenSigFirstTimeoutTime" BU_SG_REL_ VCM SG_ 930 OBDRelDTC_IC_DtcIdB 12000;
BA_REL_ "GenSigTimeoutTime" BU_SG_REL_ VCM SG_ 930 OBDRelDTC_IC_DtcIdB 3000;
BA_REL_ "GenSigFirstTimeoutTime" BU_SG_REL_ VCM SG_ 930 OBDRelDTC_IC_DrvngCycleA 12000;
BA_REL_ "GenSigTimeoutTime" BU_SG_REL_ VCM SG_ 930 OBDRelDTC_IC_DrvngCycleA 3000;
BA_REL_ "GenSigFirstTimeoutTime" BU_SG_REL_ VCM SG_ 930 OBDRelDTC_IC_FailTB 12000;
BA_REL_ "GenSigTimeoutTime" BU_SG_REL_ VCM SG_ 930 OBDRelDTC_IC_FailTB 3000;
BA_REL_ "GenSigFirstTimeoutTime" BU_SG_REL_ VCM SG_ 930 OBDRelDTC_IC_DtcIdA 12000;
BA_REL_ "GenSigTimeoutTime" BU_SG_REL_ VCM SG_ 930 OBDRelDTC_IC_DtcIdA 3000;
BA_REL_ "GenSigFirstTimeoutTime" BU_SG_REL_ VCM SG_ 930 OBDRelDTC_IC_FailTA 12000;
BA_REL_ "GenSigTimeoutTime" BU_SG_REL_ VCM SG_ 930 OBDRelDTC_IC_FailTA 3000;
BA_REL_ "GenSigFirstTimeoutTime" BU_SG_REL_ VCM SG_ 930 OBDRelDTC_IC_EvalStatB 12000;
BA_REL_ "GenSigTimeoutTime" BU_SG_REL_ VCM SG_ 930 OBDRelDTC_IC_EvalStatB 3000;
BA_REL_ "GenSigFirstTimeoutTime" BU_SG_REL_ VCM SG_ 928 Set_LG5CutoffValue_ISig_5 12000;
BA_REL_ "GenSigTimeoutTime" BU_SG_REL_ VCM SG_ 928 Set_LG5CutoffValue_ISig_5 3000;
BA_REL_ "GenSigFirstTimeoutTime" BU_SG_REL_ VCM SG_ 928 Set_LG3CutoffValue_ISig_5 12000;
BA_REL_ "GenSigTimeoutTime" BU_SG_REL_ VCM SG_ 928 Set_LG3CutoffValue_ISig_5 3000;
BA_REL_ "GenSigFirstTimeoutTime" BU_SG_REL_ VCM SG_ 928 Set_LG1CutoffValue_ISig_5 12000;
BA_REL_ "GenSigTimeoutTime" BU_SG_REL_ VCM SG_ 928 Set_LG1CutoffValue_ISig_5 3000;
BA_REL_ "GenSigFirstTimeoutTime" BU_SG_REL_ VCM SG_ 928 Set_LG2CutoffValue_ISig_5 12000;
BA_REL_ "GenSigTimeoutTime" BU_SG_REL_ VCM SG_ 928 Set_LG2CutoffValue_ISig_5 3000;
BA_REL_ "GenSigFirstTimeoutTime" BU_SG_REL_ VCM SG_ 928 Set_LG4CutoffValue_ISig_5 12000;
BA_REL_ "GenSigTimeoutTime" BU_SG_REL_ VCM SG_ 928 Set_LG4CutoffValue_ISig_5 3000;
BA_REL_ "GenSigFirstTimeoutTime" BU_SG_REL_ VCM SG_ 928 Set_EnergySetting_ISig_5 12000;
BA_REL_ "GenSigTimeoutTime" BU_SG_REL_ VCM SG_ 928 Set_EnergySetting_ISig_5 3000;
BA_REL_ "GenSigFirstTimeoutTime" BU_SG_REL_ VCM SG_ 928 Set_LG6CutoffValue_ISig_5 12000;
BA_REL_ "GenSigTimeoutTime" BU_SG_REL_ VCM SG_ 928 Set_LG6CutoffValue_ISig_5 3000;
BA_REL_ "GenSigFirstTimeoutTime" BU_SG_REL_ VCM SG_ 784 SpeedAdaptEnableRqst_SpeedLimit_ 4800;
BA_REL_ "GenSigTimeoutTime" BU_SG_REL_ VCM SG_ 784 SpeedAdaptEnableRqst_SpeedLimit_ 1200;
BA_REL_ "GenSigFirstTimeoutTime" BU_SG_REL_ VCM SG_ 784 SpeedAdaptEnableRqst_SlowTraffic 4800;
BA_REL_ "GenSigTimeoutTime" BU_SG_REL_ VCM SG_ 784 SpeedAdaptEnableRqst_SlowTraffic 1200;
BA_REL_ "GenSigFirstTimeoutTime" BU_SG_REL_ VCM SG_ 784 BattEnergySetLevel_input_ISig_5 4800;
BA_REL_ "GenSigTimeoutTime" BU_SG_REL_ VCM SG_ 784 BattEnergySetLevel_input_ISig_5 1200;
BA_REL_ "GenSigFirstTimeoutTime" BU_SG_REL_ VCM SG_ 784 SpeedAdaptationLevelRqst_ISig_5 4800;
BA_REL_ "GenSigTimeoutTime" BU_SG_REL_ VCM SG_ 784 SpeedAdaptationLevelRqst_ISig_5 1200;
BA_REL_ "GenSigFirstTimeoutTime" BU_SG_REL_ VCM SG_ 784 SpeedAdaptEnableRqst_Curve_ISig_ 4800;
BA_REL_ "GenSigTimeoutTime" BU_SG_REL_ VCM SG_ 784 SpeedAdaptEnableRqst_Curve_ISig_ 1200;
BA_REL_ "GenSigFirstTimeoutTime" BU_SG_REL_ CCM SG_ 784 ExtraHeating_rqst 4800;
BA_REL_ "GenSigTimeoutTime" BU_SG_REL_ CCM SG_ 784 ExtraHeating_rqst 1200;
BA_REL_ "GenSigFirstTimeoutTime" BU_SG_REL_ VCM SG_ 784 ExtraHeating_rqst 4800;
BA_REL_ "GenSigTimeoutTime" BU_SG_REL_ VCM SG_ 784 ExtraHeating_rqst 1200;
BA_REL_ "GenSigFirstTimeoutTime" BU_SG_REL_ VCM SG_ 672 ParkingHeaterCleaning_cmd 3000;
BA_REL_ "GenSigTimeoutTime" BU_SG_REL_ VCM SG_ 672 ParkingHeaterCleaning_cmd 600;
BA_REL_ "GenSigFirstTimeoutTime" BU_SG_REL_ CCM SG_ 672 ParkingHeaterCleaning_cmd 3000;
BA_REL_ "GenSigTimeoutTime" BU_SG_REL_ CCM SG_ 672 ParkingHeaterCleaning_cmd 600;
BA_REL_ "GenSigFirstTimeoutTime" BU_SG_REL_ CCM SG_ 672 DriverMemory_rqst_ISig_5 3000;
BA_REL_ "GenSigTimeoutTime" BU_SG_REL_ CCM SG_ 672 DriverMemory_rqst_ISig_5 600;
BA_REL_ "GenSigFirstTimeoutTime" BU_SG_REL_ VCM SG_ 672 DriverMemory_rqst_ISig_5 3000;
BA_REL_ "GenSigTimeoutTime" BU_SG_REL_ VCM SG_ 672 DriverMemory_rqst_ISig_5 600;
BA_REL_ "GenSigFirstTimeoutTime" BU_SG_REL_ VCM SG_ 672 FirstAxleLowerPrioRequested_ISig 3000;
BA_REL_ "GenSigTimeoutTime" BU_SG_REL_ VCM SG_ 672 FirstAxleLowerPrioRequested_ISig 600;
BA_REL_ "GenSigFirstTimeoutTime" BU_SG_REL_ VCM SG_ 672 ExteriorLampTest_rqst 3000;
BA_REL_ "GenSigTimeoutTime" BU_SG_REL_ VCM SG_ 672 ExteriorLampTest_rqst 600;
BA_REL_ "GenSigFirstTimeoutTime" BU_SG_REL_ VCM SG_ 672 AutoShutOffAnswerInput_ISig_5 3000;
BA_REL_ "GenSigTimeoutTime" BU_SG_REL_ VCM SG_ 672 AutoShutOffAnswerInput_ISig_5 600;
BA_REL_ "GenSigFirstTimeoutTime" BU_SG_REL_ VCM SG_ 672 ManualEngineCoolingDev_Ind 3000;
BA_REL_ "GenSigTimeoutTime" BU_SG_REL_ VCM SG_ 672 ManualEngineCoolingDev_Ind 600;
BA_REL_ "GenSigFirstTimeoutTime" BU_SG_REL_ VCM SG_ 672 TemporaryRSLDeviceIndication 3000;
BA_REL_ "GenSigTimeoutTime" BU_SG_REL_ VCM SG_ 672 TemporaryRSLDeviceIndication 600;
BA_REL_ "GenSigFirstTimeoutTime" BU_SG_REL_ VCM SG_ 672 ESC_ButtonIndication2 3000;
BA_REL_ "GenSigTimeoutTime" BU_SG_REL_ VCM SG_ 672 ESC_ButtonIndication2 600;
BA_REL_ "GenSigFirstTimeoutTime" BU_SG_REL_ VCM SG_ 672 WaterInFuelDrainRequest_ISig_5 3000;
BA_REL_ "GenSigTimeoutTime" BU_SG_REL_ VCM SG_ 672 WaterInFuelDrainRequest_ISig_5 600;
BA_REL_ "GenSigFirstTimeoutTime" BU_SG_REL_ VCM SG_ 672 PreTripIndication3 3000;
BA_REL_ "GenSigTimeoutTime" BU_SG_REL_ VCM SG_ 672 PreTripIndication3 600;
BA_REL_ "GenSigFirstTimeoutTime" BU_SG_REL_ VCM SG_ 672 ESCOff_DeviceIndication 3000;
BA_REL_ "GenSigTimeoutTime" BU_SG_REL_ VCM SG_ 672 ESCOff_DeviceIndication 600;
BA_REL_ "GenSigFirstTimeoutTime" BU_SG_REL_ VCM SG_ 672 AWBEnableRequest_ISig_5 3000;
BA_REL_ "GenSigTimeoutTime" BU_SG_REL_ VCM SG_ 672 AWBEnableRequest_ISig_5 600;
BA_REL_ "GenSigFirstTimeoutTime" BU_SG_REL_ VCM SG_ 672 LampCheck_rqst_ISig_5 3000;
BA_REL_ "GenSigTimeoutTime" BU_SG_REL_ VCM SG_ 672 LampCheck_rqst_ISig_5 600;
BA_REL_ "GenSigFirstTimeoutTime" BU_SG_REL_ VCM SG_ 416 SSReq_Repetition 3000;
BA_REL_ "GenSigTimeoutTime" BU_SG_REL_ VCM SG_ 416 SSReq_Repetition 300;
BA_REL_ "GenSigFirstTimeoutTime" BU_SG_REL_ VCM SG_ 416 SSReq_Balance 3000;
BA_REL_ "GenSigTimeoutTime" BU_SG_REL_ VCM SG_ 416 SSReq_Balance 300;
BA_REL_ "GenSigFirstTimeoutTime" BU_SG_REL_ VCM SG_ 416 SSReq_Time 3000;
BA_REL_ "GenSigTimeoutTime" BU_SG_REL_ VCM SG_ 416 SSReq_Time 300;
BA_REL_ "GenSigFirstTimeoutTime" BU_SG_REL_ VCM SG_ 416 PhoneButtonIndication_cmd 3000;
BA_REL_ "GenSigTimeoutTime" BU_SG_REL_ VCM SG_ 416 PhoneButtonIndication_cmd 300;
BA_REL_ "GenSigFirstTimeoutTime" BU_SG_REL_ VCM SG_ 416 FuncIndIlluminationLevel_ISig_5 3000;
BA_REL_ "GenSigTimeoutTime" BU_SG_REL_ VCM SG_ 416 FuncIndIlluminationLevel_ISig_5 300;
BA_REL_ "GenSigFirstTimeoutTime" BU_SG_REL_ VCM SG_ 416 BacklightCmd_ISig_5 3000;
BA_REL_ "GenSigTimeoutTime" BU_SG_REL_ VCM SG_ 416 BacklightCmd_ISig_5 300;
BA_REL_ "GenSigFirstTimeoutTime" BU_SG_REL_ VCM SG_ 416 SSReq_Id 3000;
BA_REL_ "GenSigTimeoutTime" BU_SG_REL_ VCM SG_ 416 SSReq_Id 300;
BA_REL_ "GenSigFirstTimeoutTime" BU_SG_REL_ VCM SG_ 416 SSReq_Mixed 3000;
BA_REL_ "GenSigTimeoutTime" BU_SG_REL_ VCM SG_ 416 SSReq_Mixed 300;
BA_REL_ "GenSigFirstTimeoutTime" BU_SG_REL_ VCM SG_ 416 BunkBacklightCmd 3000;
BA_REL_ "GenSigTimeoutTime" BU_SG_REL_ VCM SG_ 416 BunkBacklightCmd 300;
BA_REL_ "GenSigFirstTimeoutTime" BU_SG_REL_ VCM SG_ 416 SSReq_State 3000;
BA_REL_ "GenSigTimeoutTime" BU_SG_REL_ VCM SG_ 416 SSReq_State 300;
BA_REL_ "GenSigFirstTimeoutTime" BU_SG_REL_ VCM SG_ 416 SSReq_Volume 3000;
BA_REL_ "GenSigTimeoutTime" BU_SG_REL_ VCM SG_ 416 SSReq_Volume 300;
BA_REL_ "GenSigFirstTimeoutTime" BU_SG_REL_ VCM SG_ 211 TimeGapBtnStat 3000;
BA_REL_ "GenSigTimeoutTime" BU_SG_REL_ VCM SG_ 211 TimeGapBtnStat 120;
BA_REL_ "GenSigFirstTimeoutTime" BU_SG_REL_ VCM SG_ 211 ATC_ButtonIndication 3000;
BA_REL_ "GenSigTimeoutTime" BU_SG_REL_ VCM SG_ 211 ATC_ButtonIndication 120;
BA_REL_ "GenSigFirstTimeoutTime" BU_SG_REL_ VCM SG_ 211 PauseOffBtnStat 3000;
BA_REL_ "GenSigTimeoutTime" BU_SG_REL_ VCM SG_ 211 PauseOffBtnStat 120;
BA_REL_ "GenSigFirstTimeoutTime" BU_SG_REL_ VCM SG_ 211 ABS_ButtonIndication 3000;
BA_REL_ "GenSigTimeoutTime" BU_SG_REL_ VCM SG_ 211 ABS_ButtonIndication 120;
BA_REL_ "GenSigFirstTimeoutTime" BU_SG_REL_ VCM SG_ 211 SW_HeadlightInterrupt_Stat 3000;
BA_REL_ "GenSigTimeoutTime" BU_SG_REL_ VCM SG_ 211 SW_HeadlightInterrupt_Stat 120;
BA_REL_ "GenSigFirstTimeoutTime" BU_SG_REL_ VCM SG_ 211 PBAlertActiveStatus_ISig_5 3000;
BA_REL_ "GenSigTimeoutTime" BU_SG_REL_ VCM SG_ 211 PBAlertActiveStatus_ISig_5 120;
BA_REL_ "GenSigFirstTimeoutTime" BU_SG_REL_ VCM SG_ 211 EcoRollEnableRequest_ISig_5 3000;
BA_REL_ "GenSigTimeoutTime" BU_SG_REL_ VCM SG_ 211 EcoRollEnableRequest_ISig_5 120;
BA_REL_ "GenSigFirstTimeoutTime" BU_SG_REL_ VCM SG_ 211 EcoSettingsBtnStat 3000;
BA_REL_ "GenSigTimeoutTime" BU_SG_REL_ VCM SG_ 211 EcoSettingsBtnStat 120;
BA_REL_ "GenSigFirstTimeoutTime" BU_SG_REL_ VCM SG_ 211 SkipNextBtnStat 3000;
BA_REL_ "GenSigTimeoutTime" BU_SG_REL_ VCM SG_ 211 SkipNextBtnStat 120;
BA_REL_ "GenSigFirstTimeoutTime" BU_SG_REL_ VCM SG_ 211 GENSWS_PushButton_7_17_ISig_5 3000;
BA_REL_ "GenSigTimeoutTime" BU_SG_REL_ VCM SG_ 211 GENSWS_PushButton_7_17_ISig_5 120;
BA_REL_ "GenSigFirstTimeoutTime" BU_SG_REL_ VCM SG_ 211 TCS_ButtonIndication 3000;
BA_REL_ "GenSigTimeoutTime" BU_SG_REL_ VCM SG_ 211 TCS_ButtonIndication 120;
BA_REL_ "GenSigFirstTimeoutTime" BU_SG_REL_ VCM SG_ 211 DHCBtnStat 3000;
BA_REL_ "GenSigTimeoutTime" BU_SG_REL_ VCM SG_ 211 DHCBtnStat 120;
BA_REL_ "GenSigFirstTimeoutTime" BU_SG_REL_ VCM SG_ 211 SW_PushToTalk_BtnStat_6_17_ISig_ 3000;
BA_REL_ "GenSigTimeoutTime" BU_SG_REL_ VCM SG_ 211 SW_PushToTalk_BtnStat_6_17_ISig_ 120;
BA_REL_ "GenSigFirstTimeoutTime" BU_SG_REL_ VCM SG_ 211 GENSWS_PushButton_7_3_ISig_5 3000;
BA_REL_ "GenSigTimeoutTime" BU_SG_REL_ VCM SG_ 211 GENSWS_PushButton_7_3_ISig_5 120;
BA_REL_ "GenSigFirstTimeoutTime" BU_SG_REL_ VCM SG_ 211 SWSpdCtrlButtonsStatus6 3000;
BA_REL_ "GenSigTimeoutTime" BU_SG_REL_ VCM SG_ 211 SWSpdCtrlButtonsStatus6 120;
BA_REL_ "GenSigFirstTimeoutTime" BU_SG_REL_ VCM SG_ 211 PhoneBtnStat 3000;
BA_REL_ "GenSigTimeoutTime" BU_SG_REL_ VCM SG_ 211 PhoneBtnStat 120;
BA_REL_ "GenSigFirstTimeoutTime" BU_SG_REL_ VCM SG_ 211 SW_Home_ButtonsStatus_6 3000;
BA_REL_ "GenSigTimeoutTime" BU_SG_REL_ VCM SG_ 211 SW_Home_ButtonsStatus_6 120;
BA_REL_ "GenSigFirstTimeoutTime" BU_SG_REL_ VCM SG_ 211 SkipPrevBtnStat 3000;
BA_REL_ "GenSigTimeoutTime" BU_SG_REL_ VCM SG_ 211 SkipPrevBtnStat 120;
BA_REL_ "GenSigFirstTimeoutTime" BU_SG_REL_ VCM SG_ 211 ActivateBtnStat 3000;
BA_REL_ "GenSigTimeoutTime" BU_SG_REL_ VCM SG_ 211 ActivateBtnStat 120;
BA_REL_ "GenSigFirstTimeoutTime" BU_SG_REL_ VCM SG_ 211 ResIncrBtnStat 3000;
BA_REL_ "GenSigTimeoutTime" BU_SG_REL_ VCM SG_ 211 ResIncrBtnStat 120;
BA_REL_ "GenSigFirstTimeoutTime" BU_SG_REL_ VCM SG_ 211 SrcBtnStat 3000;
BA_REL_ "GenSigTimeoutTime" BU_SG_REL_ VCM SG_ 211 SrcBtnStat 120;
BA_REL_ "GenSigFirstTimeoutTime" BU_SG_REL_ VCM SG_ 211 SW_Mute_ButtonStatus_6_ISig_5 3000;
BA_REL_ "GenSigTimeoutTime" BU_SG_REL_ VCM SG_ 211 SW_Mute_ButtonStatus_6_ISig_5 120;
BA_REL_ "GenSigFirstTimeoutTime" BU_SG_REL_ VCM SG_ 211 SW_PushToTalk_BtnStat_6_ISig_5 3000;
BA_REL_ "GenSigTimeoutTime" BU_SG_REL_ VCM SG_ 211 SW_PushToTalk_BtnStat_6_ISig_5 120;
BA_REL_ "GenSigFirstTimeoutTime" BU_SG_REL_ VCM SG_ 211 SetDecrBtnStat 3000;
BA_REL_ "GenSigTimeoutTime" BU_SG_REL_ VCM SG_ 211 SetDecrBtnStat 120;
BA_REL_ "GenSigFirstTimeoutTime" BU_SG_REL_ VCM SG_ 211 SW_Mute_ButtonStatus_6_3_ISig_5 3000;
BA_REL_ "GenSigTimeoutTime" BU_SG_REL_ VCM SG_ 211 SW_Mute_ButtonStatus_6_3_ISig_5 120;
BA_REL_ "GenSigFirstTimeoutTime" BU_SG_REL_ VCM SG_ 211 MarkerInterruptButtonStatus 3000;
BA_REL_ "GenSigTimeoutTime" BU_SG_REL_ VCM SG_ 211 MarkerInterruptButtonStatus 120;
BA_REL_ "GenSigFirstTimeoutTime" BU_SG_REL_ VCM SG_ 1337 TPMSetAxleRefPres_Axle5_ISig_5 12000;
BA_REL_ "GenSigTimeoutTime" BU_SG_REL_ VCM SG_ 1337 TPMSetAxleRefPres_Axle5_ISig_5 3000;
BA_REL_ "GenSigFirstTimeoutTime" BU_SG_REL_ VCM SG_ 1337 TPMPosOfWMReq_VehiclePos_ISig_5 12000;
BA_REL_ "GenSigTimeoutTime" BU_SG_REL_ VCM SG_ 1337 TPMPosOfWMReq_VehiclePos_ISig_5 3000;
BA_REL_ "GenSigFirstTimeoutTime" BU_SG_REL_ VCM SG_ 1337 TPMSetAxleRefPres_Axle4_ISig_5 12000;
BA_REL_ "GenSigTimeoutTime" BU_SG_REL_ VCM SG_ 1337 TPMSetAxleRefPres_Axle4_ISig_5 3000;
BA_REL_ "GenSigFirstTimeoutTime" BU_SG_REL_ VCM SG_ 1337 TPMSetAxleRefPres_VehiclePos_ISi 12000;
BA_REL_ "GenSigTimeoutTime" BU_SG_REL_ VCM SG_ 1337 TPMSetAxleRefPres_VehiclePos_ISi 3000;
BA_REL_ "GenSigFirstTimeoutTime" BU_SG_REL_ VCM SG_ 1337 TPMSetAxleRefPres_Axle1_ISig_5 12000;
BA_REL_ "GenSigTimeoutTime" BU_SG_REL_ VCM SG_ 1337 TPMSetAxleRefPres_Axle1_ISig_5 3000;
BA_REL_ "GenSigFirstTimeoutTime" BU_SG_REL_ VCM SG_ 1337 TPMSetAxleRefPres_Axle3_ISig_5 12000;
BA_REL_ "GenSigTimeoutTime" BU_SG_REL_ VCM SG_ 1337 TPMSetAxleRefPres_Axle3_ISig_5 3000;
BA_REL_ "GenSigFirstTimeoutTime" BU_SG_REL_ VCM SG_ 1337 TPMSetAxleRefPres_Axle2_ISig_5 12000;
BA_REL_ "GenSigTimeoutTime" BU_SG_REL_ VCM SG_ 1337 TPMSetAxleRefPres_Axle2_ISig_5 3000;
BA_REL_ "GenSigFirstTimeoutTime" BU_SG_REL_ VCM SG_ 1337 TPMPosOfWMReq_TireId_ISig_5 12000;
BA_REL_ "GenSigTimeoutTime" BU_SG_REL_ VCM SG_ 1337 TPMPosOfWMReq_TireId_ISig_5 3000;
BA_REL_ "GenSigFirstTimeoutTime" BU_SG_REL_ VCM SG_ 1336 TPMSetPresThresCfg_OverPres_ISig 12000;
BA_REL_ "GenSigTimeoutTime" BU_SG_REL_ VCM SG_ 1336 TPMSetPresThresCfg_OverPres_ISig 3000;
BA_REL_ "GenSigFirstTimeoutTime" BU_SG_REL_ VCM SG_ 1336 TPMSetPresThresCfg_VehiclePos_IS 12000;
BA_REL_ "GenSigTimeoutTime" BU_SG_REL_ VCM SG_ 1336 TPMSetPresThresCfg_VehiclePos_IS 3000;
BA_REL_ "GenSigFirstTimeoutTime" BU_SG_REL_ VCM SG_ 1336 TPMSetPresThresCfg_AxleNr_ISig_5 12000;
BA_REL_ "GenSigTimeoutTime" BU_SG_REL_ VCM SG_ 1336 TPMSetPresThresCfg_AxleNr_ISig_5 3000;
BA_REL_ "GenSigFirstTimeoutTime" BU_SG_REL_ VCM SG_ 1336 TPMSetPresThresCfg_ExtUnderPres_ 12000;
BA_REL_ "GenSigTimeoutTime" BU_SG_REL_ VCM SG_ 1336 TPMSetPresThresCfg_ExtUnderPres_ 3000;
BA_REL_ "GenSigFirstTimeoutTime" BU_SG_REL_ VCM SG_ 1336 TPMSetPresThresCfg_ExtOverPres_I 12000;
BA_REL_ "GenSigTimeoutTime" BU_SG_REL_ VCM SG_ 1336 TPMSetPresThresCfg_ExtOverPres_I 3000;
BA_REL_ "GenSigFirstTimeoutTime" BU_SG_REL_ VCM SG_ 1336 TPMSetPresThresCfg_UnderPres_ISi 12000;
BA_REL_ "GenSigTimeoutTime" BU_SG_REL_ VCM SG_ 1336 TPMSetPresThresCfg_UnderPres_ISi 3000;
BA_REL_ "GenSigFirstTimeoutTime" BU_SG_REL_ IC SG_ 163 Auto_ButtonStatus 3000;
BA_REL_ "GenSigTimeoutTime" BU_SG_REL_ IC SG_ 163 Auto_ButtonStatus 120;
BA_REL_ "GenSigFirstTimeoutTime" BU_SG_REL_ IC SG_ 163 AirBlowerSpeed_FreeWheelStatus 3000;
BA_REL_ "GenSigTimeoutTime" BU_SG_REL_ IC SG_ 163 AirBlowerSpeed_FreeWheelStatus 120;
BA_REL_ "GenSigFirstTimeoutTime" BU_SG_REL_ IC SG_ 163 AirFlowSelectionDownBtn_stat 3000;
BA_REL_ "GenSigTimeoutTime" BU_SG_REL_ IC SG_ 163 AirFlowSelectionDownBtn_stat 120;
BA_REL_ "GenSigFirstTimeoutTime" BU_SG_REL_ IC SG_ 163 Temperature_FreeWheelStatus 3000;
BA_REL_ "GenSigTimeoutTime" BU_SG_REL_ IC SG_ 163 Temperature_FreeWheelStatus 120;
BA_REL_ "GenSigFirstTimeoutTime" BU_SG_REL_ IC SG_ 163 AC_ButtonStatus 3000;
BA_REL_ "GenSigTimeoutTime" BU_SG_REL_ IC SG_ 163 AC_ButtonStatus 120;
BA_REL_ "GenSigFirstTimeoutTime" BU_SG_REL_ IC SG_ 163 AirFlowSelectionUpBtn_stat 3000;
BA_REL_ "GenSigTimeoutTime" BU_SG_REL_ IC SG_ 163 AirFlowSelectionUpBtn_stat 120;
BA_REL_ "GenSigFirstTimeoutTime" BU_SG_REL_ IC SG_ 163 AirFlowSelectionFrontBtn_stat 3000;
BA_REL_ "GenSigTimeoutTime" BU_SG_REL_ IC SG_ 163 AirFlowSelectionFrontBtn_stat 120;
BA_REL_ "GenSigFirstTimeoutTime" BU_SG_REL_ IC SG_ 163 ParkHeaterCooler_ButtonStatus 3000;
BA_REL_ "GenSigTimeoutTime" BU_SG_REL_ IC SG_ 163 ParkHeaterCooler_ButtonStatus 120;
BA_REL_ "GenSigFirstTimeoutTime" BU_SG_REL_ IC SG_ 163 Recirc_ButtonStatus 3000;
BA_REL_ "GenSigTimeoutTime" BU_SG_REL_ IC SG_ 163 Recirc_ButtonStatus 120;
BA_REL_ "GenSigFirstTimeoutTime" BU_SG_REL_ IC SG_ 163 WindscreenDefrost_ButtonStatus 3000;
BA_REL_ "GenSigTimeoutTime" BU_SG_REL_ IC SG_ 163 WindscreenDefrost_ButtonStatus 120;
BA_REL_ "GenSigFirstTimeoutTime" BU_SG_REL_ VCM SG_ 1211 CabClimateFnRqst_FnPower 24000;
BA_REL_ "GenSigTimeoutTime" BU_SG_REL_ VCM SG_ 1211 CabClimateFnRqst_FnPower 6000;
BA_REL_ "GenSigFirstTimeoutTime" BU_SG_REL_ VCM SG_ 1211 CabClimateFnRqst_FnNum 24000;
BA_REL_ "GenSigTimeoutTime" BU_SG_REL_ VCM SG_ 1211 CabClimateFnRqst_FnNum 6000;
BA_REL_ "GenSigFirstTimeoutTime" BU_SG_REL_ IC SG_ 703 LifeTimeEACC_TVCabConsEgy 3000;
BA_REL_ "GenSigTimeoutTime" BU_SG_REL_ IC SG_ 703 LifeTimeEACC_TVCabConsEgy 600;
BA_REL_ "GenSigFirstTimeoutTime" BU_SG_REL_ IC SG_ 703 LifeTimeEACC_TVBattConsEgy 3000;
BA_REL_ "GenSigTimeoutTime" BU_SG_REL_ IC SG_ 703 LifeTimeEACC_TVBattConsEgy 600;
BA_REL_ "GenSigFirstTimeoutTime" BU_SG_REL_ VCM SG_ 703 EACC_TV_Voltage 3000;
BA_REL_ "GenSigTimeoutTime" BU_SG_REL_ VCM SG_ 703 EACC_TV_Voltage 600;
BA_REL_ "GenSigFirstTimeoutTime" BU_SG_REL_ VCM SG_ 703 EACC_TV_Pwr 3000;
BA_REL_ "GenSigTimeoutTime" BU_SG_REL_ VCM SG_ 703 EACC_TV_Pwr 600;
BA_REL_ "GenSigFirstTimeoutTime" BU_SG_REL_ IC SG_ 405 ClimateAirDistStatus_Defrost 3000;
BA_REL_ "GenSigTimeoutTime" BU_SG_REL_ IC SG_ 405 ClimateAirDistStatus_Defrost 300;
BA_REL_ "GenSigFirstTimeoutTime" BU_SG_REL_ IC SG_ 405 ACmode_Status 3000;
BA_REL_ "GenSigTimeoutTime" BU_SG_REL_ IC SG_ 405 ACmode_Status 300;
BA_REL_ "GenSigFirstTimeoutTime" BU_SG_REL_ IC SG_ 405 ACStatus 3000;
BA_REL_ "GenSigTimeoutTime" BU_SG_REL_ IC SG_ 405 ACStatus 300;
BA_REL_ "GenSigFirstTimeoutTime" BU_SG_REL_ IC SG_ 405 ClimateAirDistStatus_Vent 3000;
BA_REL_ "GenSigTimeoutTime" BU_SG_REL_ IC SG_ 405 ClimateAirDistStatus_Vent 300;
BA_REL_ "GenSigFirstTimeoutTime" BU_SG_REL_ IC SG_ 405 ClimatePowerStatus 3000;
BA_REL_ "GenSigTimeoutTime" BU_SG_REL_ IC SG_ 405 ClimatePowerStatus 300;
BA_REL_ "GenSigFirstTimeoutTime" BU_SG_REL_ IC SG_ 405 ClimateAutoStatus 3000;
BA_REL_ "GenSigTimeoutTime" BU_SG_REL_ IC SG_ 405 ClimateAutoStatus 300;
BA_REL_ "GenSigFirstTimeoutTime" BU_SG_REL_ IC SG_ 405 AirRecirculationStatus 3000;
BA_REL_ "GenSigTimeoutTime" BU_SG_REL_ IC SG_ 405 AirRecirculationStatus 300;
BA_REL_ "GenSigFirstTimeoutTime" BU_SG_REL_ IC SG_ 405 AutoDefogmode_Status 3000;
BA_REL_ "GenSigTimeoutTime" BU_SG_REL_ IC SG_ 405 AutoDefogmode_Status 300;
BA_REL_ "GenSigFirstTimeoutTime" BU_SG_REL_ IC SG_ 405 ClimateAirDistStatus_AutoStatus 3000;
BA_REL_ "GenSigTimeoutTime" BU_SG_REL_ IC SG_ 405 ClimateAirDistStatus_AutoStatus 300;
BA_REL_ "GenSigFirstTimeoutTime" BU_SG_REL_ IC SG_ 405 ClimateAirDistStatus_Floor 3000;
BA_REL_ "GenSigTimeoutTime" BU_SG_REL_ IC SG_ 405 ClimateAirDistStatus_Floor 300;
BA_REL_ "GenSigFirstTimeoutTime" BU_SG_REL_ IC SG_ 405 CabTempStatus 3000;
BA_REL_ "GenSigTimeoutTime" BU_SG_REL_ IC SG_ 405 CabTempStatus 300;
BA_REL_ "GenSigFirstTimeoutTime" BU_SG_REL_ IC SG_ 405 AutoBlowerLevel_Status 3000;
BA_REL_ "GenSigTimeoutTime" BU_SG_REL_ IC SG_ 405 AutoBlowerLevel_Status 300;
BA_REL_ "GenSigFirstTimeoutTime" BU_SG_REL_ IC SG_ 405 AQSmode_Status 3000;
BA_REL_ "GenSigTimeoutTime" BU_SG_REL_ IC SG_ 405 AQSmode_Status 300;
BA_REL_ "GenSigFirstTimeoutTime" BU_SG_REL_ IC SG_ 405 MaxDefrostStatus 3000;
BA_REL_ "GenSigTimeoutTime" BU_SG_REL_ IC SG_ 405 MaxDefrostStatus 300;
BA_REL_ "GenSigFirstTimeoutTime" BU_SG_REL_ IC SG_ 405 HVACBlowerLevelStat_BlowerLevel 3000;
BA_REL_ "GenSigTimeoutTime" BU_SG_REL_ IC SG_ 405 HVACBlowerLevelStat_BlowerLevel 300;
BA_REL_ "GenSigFirstTimeoutTime" BU_SG_REL_ IC SG_ 405 HVACBlowerLevelStat_AutoStatus 3000;
BA_REL_ "GenSigTimeoutTime" BU_SG_REL_ IC SG_ 405 HVACBlowerLevelStat_AutoStatus 300;
BA_REL_ "GenSigFirstTimeoutTime" BU_SG_REL_ VCM SG_ 1168 DiagFaultStat_CCM_FailTA 24000;
BA_REL_ "GenSigTimeoutTime" BU_SG_REL_ VCM SG_ 1168 DiagFaultStat_CCM_FailTA 6000;
BA_REL_ "GenSigFirstTimeoutTime" BU_SG_REL_ VCM SG_ 1168 DiagFaultStat_CCM_FailTB 24000;
BA_REL_ "GenSigTimeoutTime" BU_SG_REL_ VCM SG_ 1168 DiagFaultStat_CCM_FailTB 6000;
BA_REL_ "GenSigFirstTimeoutTime" BU_SG_REL_ VCM SG_ 1168 DiagFaultStat_CCM_DtcIdA 24000;
BA_REL_ "GenSigTimeoutTime" BU_SG_REL_ VCM SG_ 1168 DiagFaultStat_CCM_DtcIdA 6000;
BA_REL_ "GenSigFirstTimeoutTime" BU_SG_REL_ VCM SG_ 1168 DiagFaultStat_CCM_DtcIdB 24000;
BA_REL_ "GenSigTimeoutTime" BU_SG_REL_ VCM SG_ 1168 DiagFaultStat_CCM_DtcIdB 6000;
BA_REL_ "GenSigFirstTimeoutTime" BU_SG_REL_ VCM SG_ 1168 DiagFaultStat_CCM_EcuAdr 24000;
BA_REL_ "GenSigTimeoutTime" BU_SG_REL_ VCM SG_ 1168 DiagFaultStat_CCM_EcuAdr 6000;
BA_REL_ "GenSigFirstTimeoutTime" BU_SG_REL_ IC SG_ 912 ParkingClimateAvailability 12000;
BA_REL_ "GenSigTimeoutTime" BU_SG_REL_ IC SG_ 912 ParkingClimateAvailability 3000;
BA_REL_ "GenSigFirstTimeoutTime" BU_SG_REL_ VCM SG_ 912 CabTemperature_Status 12000;
BA_REL_ "GenSigTimeoutTime" BU_SG_REL_ VCM SG_ 912 CabTemperature_Status 3000;
BA_REL_ "GenSigFirstTimeoutTime" BU_SG_REL_ IC SG_ 656 LifeTimeTVECH_C_ConsEgy 12000;
BA_REL_ "GenSigTimeoutTime" BU_SG_REL_ IC SG_ 656 LifeTimeTVECH_C_ConsEgy 3000;
BA_REL_ "GenSigFirstTimeoutTime" BU_SG_REL_ VCM SG_ 656 Req24VforClimateSystem 3000;
BA_REL_ "GenSigTimeoutTime" BU_SG_REL_ VCM SG_ 656 Req24VforClimateSystem 600;
BA_REL_ "GenSigFirstTimeoutTime" BU_SG_REL_ VCM SG_ 656 TVECH_C_Pwr 3000;
BA_REL_ "GenSigTimeoutTime" BU_SG_REL_ VCM SG_ 656 TVECH_C_Pwr 600;
BA_REL_ "GenSigFirstTimeoutTime" BU_SG_REL_ VCM SG_ 656 TVECH_C_Voltage 3000;
BA_REL_ "GenSigTimeoutTime" BU_SG_REL_ VCM SG_ 656 TVECH_C_Voltage 600;
BA_REL_ "GenSigFirstTimeoutTime" BU_SG_REL_ VCM SG_ 656 AcCoolantPumpEngagementRequest_I 3000;
BA_REL_ "GenSigTimeoutTime" BU_SG_REL_ VCM SG_ 656 AcCoolantPumpEngagementRequest_I 600;
BA_REL_ "GenSigFirstTimeoutTime" BU_SG_REL_ VCM SG_ 402 PHTimer3_stat_Minutes 3000;
BA_REL_ "GenSigTimeoutTime" BU_SG_REL_ VCM SG_ 402 PHTimer3_stat_Minutes 300;
BA_REL_ "GenSigFirstTimeoutTime" BU_SG_REL_ VCM SG_ 402 PHTimer2_stat_StartDay 3000;
BA_REL_ "GenSigTimeoutTime" BU_SG_REL_ VCM SG_ 402 PHTimer2_stat_StartDay 300;
BA_REL_ "GenSigFirstTimeoutTime" BU_SG_REL_ VCM SG_ 402 PHTimer2_stat_Recurrence 3000;
BA_REL_ "GenSigTimeoutTime" BU_SG_REL_ VCM SG_ 402 PHTimer2_stat_Recurrence 300;
BA_REL_ "GenSigFirstTimeoutTime" BU_SG_REL_ VCM SG_ 402 PHTimer3_stat_Temp 3000;
BA_REL_ "GenSigTimeoutTime" BU_SG_REL_ VCM SG_ 402 PHTimer3_stat_Temp 300;
BA_REL_ "GenSigFirstTimeoutTime" BU_SG_REL_ VCM SG_ 402 PHTimer2_stat_Temp 3000;
BA_REL_ "GenSigTimeoutTime" BU_SG_REL_ VCM SG_ 402 PHTimer2_stat_Temp 300;
BA_REL_ "GenSigFirstTimeoutTime" BU_SG_REL_ VCM SG_ 402 PHTimer3_stat_StartDay 3000;
BA_REL_ "GenSigTimeoutTime" BU_SG_REL_ VCM SG_ 402 PHTimer3_stat_StartDay 300;
BA_REL_ "GenSigFirstTimeoutTime" BU_SG_REL_ VCM SG_ 402 PHTimer2_stat_Hours 3000;
BA_REL_ "GenSigTimeoutTime" BU_SG_REL_ VCM SG_ 402 PHTimer2_stat_Hours 300;
BA_REL_ "GenSigFirstTimeoutTime" BU_SG_REL_ VCM SG_ 402 PHTimer3_stat_Recurrence 3000;
BA_REL_ "GenSigTimeoutTime" BU_SG_REL_ VCM SG_ 402 PHTimer3_stat_Recurrence 300;
BA_REL_ "GenSigFirstTimeoutTime" BU_SG_REL_ VCM SG_ 402 PHTimer2_stat_Minutes 3000;
BA_REL_ "GenSigTimeoutTime" BU_SG_REL_ VCM SG_ 402 PHTimer2_stat_Minutes 300;
BA_REL_ "GenSigFirstTimeoutTime" BU_SG_REL_ VCM SG_ 402 PHTimer2_stat_Status 3000;
BA_REL_ "GenSigTimeoutTime" BU_SG_REL_ VCM SG_ 402 PHTimer2_stat_Status 300;
BA_REL_ "GenSigFirstTimeoutTime" BU_SG_REL_ VCM SG_ 402 PHTimer3_stat_Status 3000;
BA_REL_ "GenSigTimeoutTime" BU_SG_REL_ VCM SG_ 402 PHTimer3_stat_Status 300;
BA_REL_ "GenSigFirstTimeoutTime" BU_SG_REL_ VCM SG_ 402 PHTimer3_stat_Hours 3000;
BA_REL_ "GenSigTimeoutTime" BU_SG_REL_ VCM SG_ 402 PHTimer3_stat_Hours 300;
BA_REL_ "GenSigFirstTimeoutTime" BU_SG_REL_ VCM SG_ 401 PHTimer1_stat_Recurrence 3000;
BA_REL_ "GenSigTimeoutTime" BU_SG_REL_ VCM SG_ 401 PHTimer1_stat_Recurrence 300;
BA_REL_ "GenSigFirstTimeoutTime" BU_SG_REL_ VCM SG_ 401 PHTimer1_stat_Temp 3000;
BA_REL_ "GenSigTimeoutTime" BU_SG_REL_ VCM SG_ 401 PHTimer1_stat_Temp 300;
BA_REL_ "GenSigFirstTimeoutTime" BU_SG_REL_ VCM SG_ 401 PHTimer1_stat_Duration 3000;
BA_REL_ "GenSigTimeoutTime" BU_SG_REL_ VCM SG_ 401 PHTimer1_stat_Duration 300;
BA_REL_ "GenSigFirstTimeoutTime" BU_SG_REL_ VCM SG_ 401 PHTimer1_stat_Status 3000;
BA_REL_ "GenSigTimeoutTime" BU_SG_REL_ VCM SG_ 401 PHTimer1_stat_Status 300;
BA_REL_ "GenSigFirstTimeoutTime" BU_SG_REL_ VCM SG_ 401 PHTimer_rqst_Hours 3000;
BA_REL_ "GenSigTimeoutTime" BU_SG_REL_ VCM SG_ 401 PHTimer_rqst_Hours 300;
BA_REL_ "GenSigFirstTimeoutTime" BU_SG_REL_ VCM SG_ 401 PHTimer_rqst_SetAlarmOper 3000;
BA_REL_ "GenSigTimeoutTime" BU_SG_REL_ VCM SG_ 401 PHTimer_rqst_SetAlarmOper 300;
BA_REL_ "GenSigFirstTimeoutTime" BU_SG_REL_ VCM SG_ 401 PHTimer_rqst_Minutes 3000;
BA_REL_ "GenSigTimeoutTime" BU_SG_REL_ VCM SG_ 401 PHTimer_rqst_Minutes 300;
BA_REL_ "GenSigFirstTimeoutTime" BU_SG_REL_ VCM SG_ 401 PHTimer1_stat_Hours 3000;
BA_REL_ "GenSigTimeoutTime" BU_SG_REL_ VCM SG_ 401 PHTimer1_stat_Hours 300;
BA_REL_ "GenSigFirstTimeoutTime" BU_SG_REL_ VCM SG_ 401 PHTimer1_stat_Minutes 3000;
BA_REL_ "GenSigTimeoutTime" BU_SG_REL_ VCM SG_ 401 PHTimer1_stat_Minutes 300;
BA_REL_ "GenSigFirstTimeoutTime" BU_SG_REL_ VCM SG_ 401 PHTimer_rqst_DayOfWeekRq 3000;
BA_REL_ "GenSigTimeoutTime" BU_SG_REL_ VCM SG_ 401 PHTimer_rqst_DayOfWeekRq 300;
BA_REL_ "GenSigFirstTimeoutTime" BU_SG_REL_ VCM SG_ 401 PHTimer1_stat_StartDay 3000;
BA_REL_ "GenSigTimeoutTime" BU_SG_REL_ VCM SG_ 401 PHTimer1_stat_StartDay 300;
BA_REL_ "GenSigFirstTimeoutTime" BU_SG_REL_ VCM SG_ 400 WindscreenDefrostInd_cmd 3000;
BA_REL_ "GenSigTimeoutTime" BU_SG_REL_ VCM SG_ 400 WindscreenDefrostInd_cmd 300;
BA_REL_ "GenSigFirstTimeoutTime" BU_SG_REL_ VCM SG_ 400 ParkingHeater_IndicationCmd 3000;
BA_REL_ "GenSigTimeoutTime" BU_SG_REL_ VCM SG_ 400 ParkingHeater_IndicationCmd 300;
BA_REL_ "GenSigFirstTimeoutTime" BU_SG_REL_ VCM SG_ 400 AC_CompressorClutchCmd_ISig_5 3000;
BA_REL_ "GenSigTimeoutTime" BU_SG_REL_ VCM SG_ 400 AC_CompressorClutchCmd_ISig_5 300;
BA_REL_ "GenSigFirstTimeoutTime" BU_SG_REL_ IC SG_ 400 ParkingHeaterCleaning_Rqst 3000;
BA_REL_ "GenSigTimeoutTime" BU_SG_REL_ IC SG_ 400 ParkingHeaterCleaning_Rqst 300;
BA_REL_ "GenSigFirstTimeoutTime" BU_SG_REL_ VCM SG_ 400 ParkingHeaterCleaning_Rqst 3000;
BA_REL_ "GenSigTimeoutTime" BU_SG_REL_ VCM SG_ 400 ParkingHeaterCleaning_Rqst 300;
BA_REL_ "GenSigFirstTimeoutTime" BU_SG_REL_ IC SG_ 400 TemperatureRqstIndication_cmd 3000;
BA_REL_ "GenSigTimeoutTime" BU_SG_REL_ IC SG_ 400 TemperatureRqstIndication_cmd 300;
BA_REL_ "GenSigFirstTimeoutTime" BU_SG_REL_ VCM SG_ 400 TemperatureRqstIndication_cmd 3000;
BA_REL_ "GenSigTimeoutTime" BU_SG_REL_ VCM SG_ 400 TemperatureRqstIndication_cmd 300;
BA_REL_ "GenSigFirstTimeoutTime" BU_SG_REL_ VCM SG_ 400 ParkingClimate_IndicationCmd 3000;
BA_REL_ "GenSigTimeoutTime" BU_SG_REL_ VCM SG_ 400 ParkingClimate_IndicationCmd 300;
BA_REL_ "GenSigFirstTimeoutTime" BU_SG_REL_ IC SG_ 400 ParkingClimate_IndicationCmd 3000;
BA_REL_ "GenSigTimeoutTime" BU_SG_REL_ IC SG_ 400 ParkingClimate_IndicationCmd 300;
BA_REL_ "GenSigFirstTimeoutTime" BU_SG_REL_ VCM SG_ 400 ACmode_IndicationCmd 3000;
BA_REL_ "GenSigTimeoutTime" BU_SG_REL_ VCM SG_ 400 ACmode_IndicationCmd 300;
BA_REL_ "GenSigFirstTimeoutTime" BU_SG_REL_ VCM SG_ 400 TempRqst_cmd 3000;
BA_REL_ "GenSigTimeoutTime" BU_SG_REL_ VCM SG_ 400 TempRqst_cmd 300;
BA_REL_ "GenSigFirstTimeoutTime" BU_SG_REL_ IC SG_ 400 ExtraHeating_status 3000;
BA_REL_ "GenSigTimeoutTime" BU_SG_REL_ IC SG_ 400 ExtraHeating_status 300;
BA_REL_ "GenSigFirstTimeoutTime" BU_SG_REL_ VCM SG_ 400 ExtraHeating_status 3000;
BA_REL_ "GenSigTimeoutTime" BU_SG_REL_ VCM SG_ 400 ExtraHeating_status 300;
BA_REL_ "GenSigFirstTimeoutTime" BU_SG_REL_ VCM SG_ 400 CabInteriorTempVentilated_Stat 3000;
BA_REL_ "GenSigTimeoutTime" BU_SG_REL_ VCM SG_ 400 CabInteriorTempVentilated_Stat 300;
BA_REL_ "GenSigFirstTimeoutTime" BU_SG_REL_ VCM SG_ 400 ShortStopHeater_cmd_ISig_5 3000;
BA_REL_ "GenSigTimeoutTime" BU_SG_REL_ VCM SG_ 400 ShortStopHeater_cmd_ISig_5 300;
BA_REL_ "GenSigFirstTimeoutTime" BU_SG_REL_ VCM SG_ 400 ACCoolingFanSpeedRequest_CCM 3000;
BA_REL_ "GenSigTimeoutTime" BU_SG_REL_ VCM SG_ 400 ACCoolingFanSpeedRequest_CCM 300;
VAL_ 179 FerryFunctionRequest_ISig_5 3 "Request_NotAvailable" 2 "Request_Error" 1 "Request_RequestActive" 0 "Request_NotRequested" ;
VAL_ 179 KneelingChangeRequest_ISig_5 3 "KneelingChangeRequest_NotAvailable" 2 "KneelingChangeRequest_Error" 1 "KneelingChangeRequest_ChangeKneelFunction" 0 "KneelingChangeRequest_TakeNoAction" ;
VAL_ 179 LiftAxle1AutoLiftRequest_ISig_5 3 "InactiveActive_NotAvailable" 2 "InactiveActive_Error" 1 "InactiveActive_Active" 0 "InactiveActive_Inactive" ;
VAL_ 179 FPBRChangeReq_ISig_5 3 "FPBRChangeReq_NotAvailable" 2 "FPBRChangeReq_Error" 1 "FPBRChangeReq_ChangeFPBRFunction" 0 "FPBRChangeReq_TakeNoAction" ;
VAL_ 179 LightMode_Status_Ctr_1 15 "Freewheel_Status_Ctr_NotAvailable" 14 "Freewheel_Status_Ctr_Error" 13 "Freewheel_Status_Ctr_Position13" 12 "Freewheel_Status_Ctr_Position12" 11 "Freewheel_Status_Ctr_Position11" 10 "Freewheel_Status_Ctr_Position10" 9 "Freewheel_Status_Ctr_Position9" 8 "Freewheel_Status_Ctr_Position8" 7 "Freewheel_Status_Ctr_Position7" 6 "Freewheel_Status_Ctr_Position6" 5 "Freewheel_Status_Ctr_Position5" 4 "Freewheel_Status_Ctr_Position4" 3 "Freewheel_Status_Ctr_Position3" 2 "Freewheel_Status_Ctr_Position2" 1 "Freewheel_Status_Ctr_Position1" 0 "Freewheel_Status_Ctr_NoMovement" ;
VAL_ 179 LevelRequest_RollRequest_ISig_5 7 "RollRequest_NotAvailable" 6 "RollRequest_Error" 5 "RollRequest_Reserved" 4 "RollRequest_CounterClockwiseShort" 3 "RollRequest_ClockwiseShort" 2 "RollRequest_CounterClockwise" 1 "RollRequest_Clockwise" 0 "RollRequest_Idle" ;
VAL_ 179 AltLoadDistribution_rqst_ISig_5 7 "AltLoadDistribution_rqst_NotAvailable" 6 "AltLoadDistribution_rqst_Error" 5 "AltLoadDistribution_rqst_Reserved_3" 4 "AltLoadDistribution_rqst_Reserved_2" 3 "AltLoadDistribution_rqst_Reserved_1" 2 "AltLoadDistribution_rqst_ALDOff" 1 "AltLoadDistribution_rqst_ALDOn" 0 "AltLoadDistribution_rqst_Idle" ;
VAL_ 179 LoadDistributionChangeRequest_IS 3 "LoadDistributionChangeRequest_NotAvailable" 2 "LoadDistributionChangeRequest_Error" 1 "LoadDistributionChangeRequest_ChangeLoadDistribution" 0 "LoadDistributionChangeRequest_Idle" ;
VAL_ 179 LiftAxle1LiftPositionRequest_ISi 7 "LiftAxleLiftPositionRequest_NotAvailable" 6 "LiftAxleLiftPositionRequest_Error" 5 "LiftAxleLiftPositionRequest_Reserved_02" 4 "LiftAxleLiftPositionRequest_Reserved_01" 3 "LiftAxleLiftPositionRequest_Reserved" 2 "LiftAxleLiftPositionRequest_Up" 1 "LiftAxleLiftPositionRequest_Down" 0 "LiftAxleLiftPositionRequest_Idle" ;
VAL_ 179 ReverseWarning_rqst 3 "ReverseWarning_rqst_NotAvailable" 2 "ReverseWarning_rqst_Error" 1 "ReverseWarning_rqst_SoundOn" 0 "ReverseWarning_rqst_SoundOff" ;
VAL_ 179 FerryFunctionSwitchChangeReq_ISi 3 "ChangeRequest2Bit_NotAvailable" 2 "ChangeRequest2Bit_Error" 1 "ChangeRequest2Bit_Change" 0 "ChangeRequest2Bit_TakeNoAction" ;
VAL_ 179 BackToDriveReq_ISig_5 3 "Requested_NotAvailable" 2 "Requested_Error" 1 "BackToDriveReq_B2DRequested" 0 "BackToDriveReq_Idle" ;
VAL_ 179 FogLightFront_ButtonStatus_1 3 "PushButtonStatus_NotAvailable" 2 "PushButtonStatus_Error" 1 "PushButtonStatus_Pushed" 0 "PushButtonStatus_Neutral" ;
VAL_ 179 LevelRequest_RearAxle_ISig_5 7 "LevelChangeRequest_NotAvailable" 6 "LevelChangeRequest_ErrorIndicator" 5 "LevelChangeRequest_NotDefined" 4 "LevelChangeRequest_VehicleBodyDownMinimumMovementLowering" 3 "LevelChangeRequest_VehicleBodyUpMinimumMovementLifting" 2 "LevelChangeRequest_VehicleBodyDownLowering" 1 "LevelChangeRequest_VehicleBodyUpLifting" 0 "LevelChangeRequest_TakeNoAction" ;
VAL_ 179 LiftAxle1DirectControl_ISig_5 7 "LiftAxleLiftPositionRequest_NotAvailable" 6 "LiftAxleLiftPositionRequest_Error" 5 "LiftAxleLiftPositionRequest_Reserved_02" 4 "LiftAxleLiftPositionRequest_Reserved_01" 3 "LiftAxleLiftPositionRequest_Reserved" 2 "LiftAxleLiftPositionRequest_Up" 1 "LiftAxleLiftPositionRequest_Down" 0 "LiftAxleLiftPositionRequest_Idle" ;
VAL_ 179 ECSStandByRequest_ISig_5 7 "ECSStandByRequest_NotAvailable" 6 "ECSStandByRequest_Error" 5 "ECSStandByRequest_Reserved_01" 4 "ECSStandByRequest_Reserved" 3 "ECSStandByRequest_StandbyRequestedWRC" 2 "ECSStandByRequest_StandbyRequestedRCECS" 1 "ECSStandByRequest_Initiate" 0 "ECSStandByRequest_NoRequest" ;
VAL_ 179 LiftAxle2LiftPositionRequest_ISi 7 "LiftAxleLiftPositionRequest_NotAvailable" 6 "LiftAxleLiftPositionRequest_Error" 5 "LiftAxleLiftPositionRequest_Reserved_02" 4 "LiftAxleLiftPositionRequest_Reserved_01" 3 "LiftAxleLiftPositionRequest_Reserved" 2 "LiftAxleLiftPositionRequest_Up" 1 "LiftAxleLiftPositionRequest_Down" 0 "LiftAxleLiftPositionRequest_Idle" ;
VAL_ 179 FogLightRear_ButtonStatus_1 3 "PushButtonStatus_NotAvailable" 2 "PushButtonStatus_Error" 1 "PushButtonStatus_Pushed" 0 "PushButtonStatus_Neutral" ;
VAL_ 179 LevelStrokeRequest_ISig_5 3 "LevelStrokeRequest_NotAvailable" 2 "LevelStrokeRequest_ErrorIndicator" 1 "LevelStrokeRequest_DriveLevelControlStroke" 0 "LevelStrokeRequest_DockingLevelControlStroke" ;
VAL_ 179 RampLevelRequest_ISig_5 15 "RampLevelRequest_NotAvailable" 14 "RampLevelRequest_ErrorIndicator" 13 "RampLevelRequest_NotDefined_09" 12 "RampLevelRequest_NotDefined_08" 11 "RampLevelRequest_NotDefined_07" 10 "RampLevelRequest_NotDefined_06" 9 "RampLevelRequest_NotDefined_05" 8 "RampLevelRequest_NotDefined_04" 7 "RampLevelRequest_RampLevelM7" 6 "RampLevelRequest_RampLevelM6" 5 "RampLevelRequest_RampLevelM5" 4 "RampLevelRequest_RampLevelM4" 3 "RampLevelRequest_RampLevelM3" 2 "RampLevelRequest_RampLevelM2" 1 "RampLevelRequest_RampLevelM1" 0 "RampLevelRequest_TakeNoAction" ;
VAL_ 179 LevelRequest_FrontAxle_ISig_5 7 "LevelChangeRequest_NotAvailable" 6 "LevelChangeRequest_ErrorIndicator" 5 "LevelChangeRequest_NotDefined" 4 "LevelChangeRequest_VehicleBodyDownMinimumMovementLowering" 3 "LevelChangeRequest_VehicleBodyUpMinimumMovementLifting" 2 "LevelChangeRequest_VehicleBodyDownLowering" 1 "LevelChangeRequest_VehicleBodyUpLifting" 0 "LevelChangeRequest_TakeNoAction" ;
VAL_ 179 LiftAxle2AutoLiftRequest_ISig_5 3 "InactiveActive_NotAvailable" 2 "InactiveActive_Error" 1 "InactiveActive_Active" 0 "InactiveActive_Inactive" ;
VAL_ 179 RampLevelStorageRequest_ISig_5 15 "RampLevelRequest_NotAvailable" 14 "RampLevelRequest_ErrorIndicator" 13 "RampLevelRequest_NotDefined_09" 12 "RampLevelRequest_NotDefined_08" 11 "RampLevelRequest_NotDefined_07" 10 "RampLevelRequest_NotDefined_06" 9 "RampLevelRequest_NotDefined_05" 8 "RampLevelRequest_NotDefined_04" 7 "RampLevelRequest_RampLevelM7" 6 "RampLevelRequest_RampLevelM6" 5 "RampLevelRequest_RampLevelM5" 4 "RampLevelRequest_RampLevelM4" 3 "RampLevelRequest_RampLevelM3" 2 "RampLevelRequest_RampLevelM2" 1 "RampLevelRequest_RampLevelM1" 0 "RampLevelRequest_TakeNoAction" ;
VAL_ 179 RideHeightStorageRequest_ISig_5 15 "RideHeightStorageRequest_NotAvailable" 14 "RideHeightStorageRequest_ErrorIndicator" 13 "RideHeightStorageRequest_NotDefined_06" 12 "RideHeightStorageRequest_NotDefined_05" 11 "RideHeightStorageRequest_NotDefined_04" 10 "RideHeightStorageRequest_NotDefined_03" 9 "RideHeightStorageRequest_NotDefined_02" 8 "RideHeightStorageRequest_NotDefined_01" 7 "RideHeightStorageRequest_NotDefined" 6 "RideHeightStorageRequest_ResetHighDrivePosition" 5 "RideHeightStorageRequest_ResetLowDrivePosition" 4 "RideHeightStorageRequest_StoreHighDrivePosition" 3 "RideHeightStorageRequest_StoreLowDrivePosition" 2 "RideHeightStorageRequest_StoreStandardUserDrivePosition" 1 "RideHeightStorageRequest_ResetToStoreFactoryDrivePosition" 0 "RideHeightStorageRequest_TakeNoAction" ;
VAL_ 419 ClimateAutoRequest 3 "OffOn_NotAvailable" 2 "OffOn_Error" 1 "OffOn_On" 0 "OffOn_Off" ;
VAL_ 419 ACModeRqst 7 "ACModeReq_NotAvailable" 6 "ACModeReq_Error" 5 "ACModeReq_Spare" 4 "ACModeReq_ExtraDryCabAir" 3 "ACModeReq_HumidCabAir" 2 "ACModeReq_Standard" 1 "ACModeReq_Economy" 0 "ACModeReq_NoAction" ;
VAL_ 419 ParkingClimateRequest 3 "OffOn_NotAvailable" 2 "OffOn_Error" 1 "OffOn_On" 0 "OffOn_Off" ;
VAL_ 419 AutoBlowerLevelRqst 7 "AutoBlowerLevelRqst_NotAvailable" 6 "AutoBlowerLevelRqst_Error" 3 "AutoBlowerLevelRqst_Low" 2 "AutoBlowerLevelRqst_Normal" 1 "AutoBlowerLevelRqst_High" 0 "AutoBlowerLevelRqst_NoAction" ;
VAL_ 419 MaxDefrostRequest 3 "OffOn_NotAvailable" 2 "OffOn_Error" 1 "OffOn_On" 0 "OffOn_Off" ;
VAL_ 419 AQSModeRqst 7 "AQSModeRqst_NotAvailable" 6 "AQSModeRqst_Error" 5 "AQSModeRqst_Spare3" 4 "AQSModeRqst_Spare2" 3 "AQSModeRqst_Spare1" 2 "AQSModeRqst_Auto" 1 "AQSModeRqst_Off" 0 "AQSModeRqst_NoAction" ;
VAL_ 419 AirRecirculationRequest 3 "OffOn_NotAvailable" 2 "OffOn_Error" 1 "OffOn_On" 0 "OffOn_Off" ;
VAL_ 419 ACRequest 3 "OffOn_NotAvailable" 2 "OffOn_Error" 1 "OffOn_On" 0 "OffOn_Off" ;
VAL_ 419 ClimatePowerRequest 3 "OffOn_NotAvailable" 2 "OffOn_Error" 1 "OffOn_On" 0 "OffOn_Off" ;
VAL_ 419 AutoDefogModeRqst 7 "AutoDefogModeRqst_NotAvailable" 6 "AutoDefogModeRqst_Error" 5 "AutoDefogModeRqst_Spare" 4 "AutoDefogModeRqst_Moderate" 3 "AutoDefogModeRqst_Normal" 2 "AutoDefogModeRqst_Sensitive" 1 "AutoDefogModeRqst_Off" 0 "AutoDefogModeRqst_NoAction" ;
VAL_ 1184 FasPersonalSettingsButton_rqst_I 7 "FasPersSettingsButton_NotAvailable" 6 "FasPersSettingsButton_Error" 5 "FasPersSettingsButton_Spare" 4 "FasPersSettingsButton_UserDefinedButton" 3 "FasPersSettingsButton_PresetButtonHeavy" 2 "FasPersSettingsButton_PresetButtonFirm" 1 "FasPersSettingsButton_PresetButtonLight" 0 "FasPersSettingsButton_PresetButtonDefault" ;
VAL_ 1184 FasDriver_rqst_ISig_5 15 "FasDriver_NotAvailable" 14 "FasDriver_Error" 13 "FasDriver_Spare3" 12 "FasDriver_Spare2" 11 "FasDriver_Spare1" 10 "FasDriver_Driver10" 9 "FasDriver_Driver9" 8 "FasDriver_Driver8" 7 "FasDriver_Driver7" 6 "FasDriver_Driver6" 5 "FasDriver_Driver5" 4 "FasDriver_Driver4" 3 "FasDriver_Driver3" 2 "FasDriver_Driver2" 1 "FasDriver_Driver1" 0 "FasDriver_DefaultDriver" ;
VAL_ 1184 FasUsrDefinedStorage_rqst_ISig_5 3 "FasUsrDefinedStorage_NotAvailable" 2 "FasUsrDefinedStorage_Error" 1 "FasUsrDefinedStorage_StoreUserDefinedSetting" 0 "FasUsrDefinedStorage_DoNotStoreUserDefinedSetting" ;
VAL_ 932 DPF_ManualRegenerateRequest_ISig 3 "Request_NotAvailable" 2 "Request_Error" 1 "Request_RequestActive" 0 "Request_NotRequested" ;
VAL_ 932 DPF_ManualRegenerateInhibit_ISig 3 "InactiveActive_NotAvailable" 2 "InactiveActive_Error" 1 "InactiveActive_Active" 0 "InactiveActive_Inactive" ;
VAL_ 932 DPF_ManualRegenerateTimeReq_ISig 3 "NotRequested_NotAvailable" 2 "NotRequested_Error" 1 "NotRequested_Requested" 0 "NotRequested_NotRequested" ;
VAL_ 930 OBDRelDTC_IC_DrvngCycleB 3 "DrivingCycleLSBB_NotAvailable" 2 "DrivingCycleLSBB_Error" 1 "DrivingCycleLSBB_Value1" 0 "DrivingCycleLSBB_Value0" ;
VAL_ 930 OBDRelDTC_IC_EvalResultA 3 "DTCEvalResultA_NotAvailable" 2 "DTCEvalResultA_Error" 1 "DTCEvalResultA_Passed" 0 "DTCEvalResultA_Failed" ;
VAL_ 930 OBDRelDTC_IC_EvalResultB 3 "DTCEvalResultB_NotAvailable" 2 "DTCEvalResultB_Error" 1 "DTCEvalResultB_Passed" 0 "DTCEvalResultB_Failed" ;
VAL_ 930 OBDRelDTC_IC_EvalStatA 3 "DTCEvalStatA_NotAvailable" 2 "DTCEvalStatA_Error" 1 "DTCEvalStatA_Complete" 0 "DTCEvalStatA_Incomplete" ;
VAL_ 930 OBDRelDTC_IC_DrvngCycleA 3 "DrivingCycleLSBA_NotAvailable" 2 "DrivingCycleLSBA_Error" 1 "DrivingCycleLSBA_Value1" 0 "DrivingCycleLSBA_Value0" ;
VAL_ 930 OBDRelDTC_IC_EvalStatB 3 "DTCEvalStatB_NotAvailable" 2 "DTCEvalStatB_Error" 1 "DTCEvalStatB_Complete" 0 "DTCEvalStatB_Incomplete" ;
VAL_ 928 Set_EnergySetting_ISig_5 7 "EnergySetting_NotAvailable" 6 "EnergySetting_Error" 5 "EnergySetting_Spare2" 4 "EnergySetting_Spare1" 3 "EnergySetting_Customise" 2 "EnergySetting_PresetLevel2_HighEnergySaving" 1 "EnergySetting_PresetLevel1_EnergySaving" 0 "EnergySetting_OFF" ;
VAL_ 784 SpeedAdaptEnableRqst_SpeedLimit_ 3 "Selected_NotAvailable" 2 "Selected_Error" 1 "Selected_Selected" 0 "Selected_NotSelected" ;
VAL_ 784 SpeedAdaptEnableRqst_SlowTraffic 3 "Selected_NotAvailable" 2 "Selected_Error" 1 "Selected_Selected" 0 "Selected_NotSelected" ;
VAL_ 784 BattEnergySetLevel_input_ISig_5 7 "BattEnergySetLevel_input_NotAvailable" 6 "BattEnergySetLevel_input_Error" 5 "BattEnergySetLevel_input_Spare" 4 "BattEnergySetLevel_input_Level5" 3 "BattEnergySetLevel_input_Level4" 2 "BattEnergySetLevel_input_Level3" 1 "BattEnergySetLevel_input_Level2" 0 "BattEnergySetLevel_input_Level1" ;
VAL_ 784 SpeedAdaptationLevelRqst_ISig_5 7 "LowMidHigh_NotAvailable" 6 "LowMidHigh_Error" 5 "LowMidHigh_Spare3" 4 "LowMidHigh_Spare2" 3 "LowMidHigh_Spare1" 2 "LowMidHigh_High" 1 "LowMidHigh_Mid" 0 "LowMidHigh_Low" ;
VAL_ 784 SpeedAdaptEnableRqst_Curve_ISig_ 3 "Selected_NotAvailable" 2 "Selected_Error" 1 "Selected_Selected" 0 "Selected_NotSelected" ;
VAL_ 784 ExtraHeating_rqst 7 "ActivationRequest_NotAvailable" 6 "ActivationRequest_Error" 5 "ActivationRequest_Spare3" 4 "ActivationRequest_Spare2" 3 "ActivationRequest_Spare1" 2 "ActivationRequest_AutoStart" 1 "ActivationRequest_Off" 0 "ActivationRequest_NoAction" ;
VAL_ 672 ParkingHeaterCleaning_cmd 3 "ParkingHeaterCleaning_cmd_NotAvailable" 2 "ParkingHeaterCleaning_cmd_Escaped" 1 "ParkingHeaterCleaning_cmd_Activated" 0 "ParkingHeaterCleaning_cmd_NoAction" ;
VAL_ 672 DriverMemory_rqst_ISig_5 31 "DriverMemory_rqst_Error" 30 "DriverMemory_rqst_NotAvailable" 29 "DriverMemory_rqst_Spare_07" 28 "DriverMemory_rqst_Spare_06" 27 "DriverMemory_rqst_Spare_05" 26 "DriverMemory_rqst_Spare_04" 25 "DriverMemory_rqst_Spare_03" 24 "DriverMemory_rqst_Spare_02" 23 "DriverMemory_rqst_Spare_01" 22 "DriverMemory_rqst_Spare" 21 "DriverMemory_rqst_ResetAllMemThenUseDefDriverMem" 20 "DriverMemory_rqst_ResetAndThenUseDriverMemory10" 19 "DriverMemory_rqst_ResetAndThenUseDriverMemory9" 18 "DriverMemory_rqst_ResetAndThenUseDriverMemory8" 17 "DriverMemory_rqst_ResetAndThenUseDriverMemory7" 16 "DriverMemory_rqst_ResetAndThenUseDriverMemory6" 15 "DriverMemory_rqst_ResetAndThenUseDriverMemory5" 14 "DriverMemory_rqst_ResetAndThenUseDriverMemory4" 13 "DriverMemory_rqst_ResetAndThenUseDriverMemory3" 12 "DriverMemory_rqst_ResetAndThenUseDriverMemory2" 11 "DriverMemory_rqst_ResetAndThenUseDriverMemory1" 10 "DriverMemory_rqst_UseDriverMemory10" 9 "DriverMemory_rqst_UseDriverMemory9" 8 "DriverMemory_rqst_UseDriverMemory8" 7 "DriverMemory_rqst_UseDriverMemory7" 6 "DriverMemory_rqst_UseDriverMemory6" 5 "DriverMemory_rqst_UseDriverMemory5" 4 "DriverMemory_rqst_UseDriverMemory4" 3 "DriverMemory_rqst_UseDriverMemory3" 2 "DriverMemory_rqst_UseDriverMemory2" 1 "DriverMemory_rqst_UseDriverMemory1" 0 "DriverMemory_rqst_UseDefaultDriverMemory" ;
VAL_ 672 FirstAxleLowerPrioRequested_ISig 7 "FirstAxleLowerPrio_NotAvailable" 6 "FirstAxleLowerPrio_Error" 5 "FirstAxleLowerPrio_Reserved_03" 4 "FirstAxleLowerPrio_Reserved_02" 3 "FirstAxleLowerPrio_Reserved_01" 2 "FirstAxleLowerPrio_Reserved" 1 "FirstAxleLowerPrio_LowerPusher" 0 "FirstAxleLowerPrio_LowerTag" ;
VAL_ 672 ExteriorLampTest_rqst 3 "Request_NotAvailable" 2 "Request_Error" 1 "Request_RequestActive" 0 "Request_NotRequested" ;
VAL_ 672 AutoShutOffAnswerInput_ISig_5 7 "AutoShutOffAnswerInput_NotAvailable" 6 "AutoShutOffAnswerInput_Error" 5 "AutoShutOffAnswerInput_Spare3" 4 "AutoShutOffAnswerInput_Spare2" 3 "AutoShutOffAnswerInput_Spare1" 2 "AutoShutOffAnswerInput_Delayed" 1 "AutoShutOffAnswerInput_NoAnswer" 0 "AutoShutOffAnswerInput_Accepted" ;
VAL_ 672 ManualEngineCoolingDev_Ind 3 "DeviceIndication_SpareValue" 2 "DeviceIndication_Blink" 1 "DeviceIndication_On" 0 "DeviceIndication_Off" ;
VAL_ 672 TemporaryRSLDeviceIndication 3 "DeviceIndication_SpareValue" 2 "DeviceIndication_Blink" 1 "DeviceIndication_On" 0 "DeviceIndication_Off" ;
VAL_ 672 ESC_ButtonIndication2 3 "DeviceIndication_SpareValue" 2 "DeviceIndication_Blink" 1 "DeviceIndication_On" 0 "DeviceIndication_Off" ;
VAL_ 672 WaterInFuelDrainRequest_ISig_5 3 "Request_NotAvailable" 2 "Request_Error" 1 "Request_RequestActive" 0 "Request_NotRequested" ;
VAL_ 672 PreTripIndication3 3 "DeviceIndication_SpareValue" 2 "DeviceIndication_Blink" 1 "DeviceIndication_On" 0 "DeviceIndication_Off" ;
VAL_ 672 ESCOff_DeviceIndication 3 "DeviceIndication_SpareValue" 2 "DeviceIndication_Blink" 1 "DeviceIndication_On" 0 "DeviceIndication_Off" ;
VAL_ 672 AWBEnableRequest_ISig_5 3 "DisableEnable_NotAvailable" 2 "DisableEnable_Error" 1 "DisableEnable_Enable" 0 "DisableEnable_Disable" ;
VAL_ 672 LampCheck_rqst_ISig_5 3 "LampCheck_NotAvailable" 2 "LampCheck_Error" 1 "LampCheck_PerformLampCheck" 0 "LampCheck_NoAction" ;
VAL_ 416 SSReq_Balance 3 "SystemSoundBalance_Spare" 2 "SystemSoundBalance_Right" 1 "SystemSoundBalance_Left" 0 "SystemSoundBalance_Both" ;
VAL_ 416 PhoneButtonIndication_cmd 3 "DeviceIndication_SpareValue" 2 "DeviceIndication_Blink" 1 "DeviceIndication_On" 0 "DeviceIndication_Off" ;
VAL_ 416 FuncIndIlluminationLevel_ISig_5 7 "FuncIndIlluminationLevel_NotAvailable" 6 "FuncIndIlluminationLevel_Error" 5 "FuncIndIlluminationLevel_Spare" 4 "FuncIndIlluminationLevel_IlluminationLevel4" 3 "FuncIndIlluminationLevel_IlluminationLevel3" 2 "FuncIndIlluminationLevel_IlluminationLevel2" 1 "FuncIndIlluminationLevel_IlluminationLevel1" 0 "FuncIndIlluminationLevel_IlluminationOff" ;
VAL_ 416 BacklightCmd_ISig_5 31 "BacklightCmd_NotAvailable" 30 "BacklightCmd_Error" 16 "BacklightCmd_BacklightLevel16" 15 "BacklightCmd_BacklightLevel15" 14 "BacklightCmd_BacklightLevel14" 13 "BacklightCmd_BacklightLevel13" 12 "BacklightCmd_BacklightLevel12" 11 "BacklightCmd_BacklightLevel11" 10 "BacklightCmd_BacklightLevel10" 9 "BacklightCmd_BacklightLevel9" 8 "BacklightCmd_BacklightLevel8" 7 "BacklightCmd_BacklightLevel7" 6 "BacklightCmd_BacklightLevel6" 5 "BacklightCmd_BacklightLevel5" 4 "BacklightCmd_BacklightLevel4" 3 "BacklightCmd_BacklightLevel3" 2 "BacklightCmd_BacklightLevel2" 1 "BacklightCmd_BacklightLevel1" 0 "BacklightCmd_BacklightOff" ;
VAL_ 416 SSReq_Mixed 1 "SystemSoundMixed_MixedWithBackgroungSound" 0 "SystemSoundMixed_BackgroundSoundMuted" ;
VAL_ 416 BunkBacklightCmd 31 "BacklightCmd_NotAvailable" 30 "BacklightCmd_Error" 16 "BacklightCmd_BacklightLevel16" 15 "BacklightCmd_BacklightLevel15" 14 "BacklightCmd_BacklightLevel14" 13 "BacklightCmd_BacklightLevel13" 12 "BacklightCmd_BacklightLevel12" 11 "BacklightCmd_BacklightLevel11" 10 "BacklightCmd_BacklightLevel10" 9 "BacklightCmd_BacklightLevel9" 8 "BacklightCmd_BacklightLevel8" 7 "BacklightCmd_BacklightLevel7" 6 "BacklightCmd_BacklightLevel6" 5 "BacklightCmd_BacklightLevel5" 4 "BacklightCmd_BacklightLevel4" 3 "BacklightCmd_BacklightLevel3" 2 "BacklightCmd_BacklightLevel2" 1 "BacklightCmd_BacklightLevel1" 0 "BacklightCmd_BacklightOff" ;
VAL_ 416 SSReq_State 1 "SystemSoundState_Play" 0 "SystemSoundState_Stop" ;
VAL_ 211 TimeGapBtnStat 3 "PushButtonStatus_NotAvailable" 2 "PushButtonStatus_Error" 1 "PushButtonStatus_Pushed" 0 "PushButtonStatus_Neutral" ;
VAL_ 211 ATC_ButtonIndication 3 "DeviceIndication_SpareValue" 2 "DeviceIndication_Blink" 1 "DeviceIndication_On" 0 "DeviceIndication_Off" ;
VAL_ 211 PauseOffBtnStat 3 "PushButtonStatus_NotAvailable" 2 "PushButtonStatus_Error" 1 "PushButtonStatus_Pushed" 0 "PushButtonStatus_Neutral" ;
VAL_ 211 ABS_ButtonIndication 3 "DeviceIndication_SpareValue" 2 "DeviceIndication_Blink" 1 "DeviceIndication_On" 0 "DeviceIndication_Off" ;
VAL_ 211 SW_HeadlightInterrupt_Stat 3 "PushButtonStatus_NotAvailable" 2 "PushButtonStatus_Error" 1 "PushButtonStatus_Pushed" 0 "PushButtonStatus_Neutral" ;
VAL_ 211 PBAlertActiveStatus_ISig_5 7 "PBAlertActiveStatus_NotAvailable" 6 "PBAlertActiveStatus_Error" 5 "PBAlertActiveStatus_Spare3" 4 "PBAlertActiveStatus_Spare2" 3 "PBAlertActiveStatus_Spare1" 2 "PBAlertActiveStatus_ShortAlertActive" 1 "PBAlertActiveStatus_LongAlertActive" 0 "PBAlertActiveStatus_Inactive" ;
VAL_ 211 EcoRollEnableRequest_ISig_5 3 "InactiveActive_NotAvailable" 2 "InactiveActive_Error" 1 "InactiveActive_Active" 0 "InactiveActive_Inactive" ;
VAL_ 211 EcoSettingsBtnStat 3 "PushButtonStatus_NotAvailable" 2 "PushButtonStatus_Error" 1 "PushButtonStatus_Pushed" 0 "PushButtonStatus_Neutral" ;
VAL_ 211 SkipNextBtnStat 3 "PushButtonStatus_NotAvailable" 2 "PushButtonStatus_Error" 1 "PushButtonStatus_Pushed" 0 "PushButtonStatus_Neutral" ;
VAL_ 211 GENSWS_PushButton_7_17_ISig_5 3 "PushButtonStatus_NotAvailable" 2 "PushButtonStatus_Error" 1 "PushButtonStatus_Pushed" 0 "PushButtonStatus_Neutral" ;
VAL_ 211 TCS_ButtonIndication 3 "DeviceIndication_SpareValue" 2 "DeviceIndication_Blink" 1 "DeviceIndication_On" 0 "DeviceIndication_Off" ;
VAL_ 211 DHCBtnStat 3 "PushButtonStatus_NotAvailable" 2 "PushButtonStatus_Error" 1 "PushButtonStatus_Pushed" 0 "PushButtonStatus_Neutral" ;
VAL_ 211 SW_PushToTalk_BtnStat_6_17_ISig_ 3 "PushButtonStatus_NotAvailable" 2 "PushButtonStatus_Error" 1 "PushButtonStatus_Pushed" 0 "PushButtonStatus_Neutral" ;
VAL_ 211 GENSWS_PushButton_7_3_ISig_5 3 "PushButtonStatus_NotAvailable" 2 "PushButtonStatus_Error" 1 "PushButtonStatus_Pushed" 0 "PushButtonStatus_Neutral" ;
VAL_ 211 SWSpdCtrlButtonsStatus6 15 "SWSpdCtrlButtonsStatus6_NotAvailable" 14 "SWSpdCtrlButtonsStatus6_Error" 13 "SWSpdCtrlButtonsStatus6_Spare04" 12 "SWSpdCtrlButtonsStatus6_Spare03" 11 "SWSpdCtrlButtonsStatus6_Spare02" 10 "SWSpdCtrlButtonsStatus6_Spare01" 9 "SWSpdCtrlButtonsStatus6_TimeGap" 8 "SWSpdCtrlButtonsStatus6_DHC" 7 "SWSpdCtrlButtonsStatus6_EcoSettings" 6 "SWSpdCtrlButtonsStatus6_CC_ACC" 5 "SWSpdCtrlButtonsStatus6_Enter" 4 "SWSpdCtrlButtonsStatus6_Decrease" 3 "SWSpdCtrlButtonsStatus6_Increase" 2 "SWSpdCtrlButtonsStatus6_Resume" 1 "SWSpdCtrlButtonsStatus6_PauseOff" 0 "SWSpdCtrlButtonsStatus6_None" ;
VAL_ 211 PhoneBtnStat 3 "PushButtonStatus_NotAvailable" 2 "PushButtonStatus_Error" 1 "PushButtonStatus_Pushed" 0 "PushButtonStatus_Neutral" ;
VAL_ 211 SW_Home_ButtonsStatus_6 3 "PushButtonStatus_NotAvailable" 2 "PushButtonStatus_Error" 1 "PushButtonStatus_Pushed" 0 "PushButtonStatus_Neutral" ;
VAL_ 211 SkipPrevBtnStat 3 "PushButtonStatus_NotAvailable" 2 "PushButtonStatus_Error" 1 "PushButtonStatus_Pushed" 0 "PushButtonStatus_Neutral" ;
VAL_ 211 ActivateBtnStat 3 "PushButtonStatus_NotAvailable" 2 "PushButtonStatus_Error" 1 "PushButtonStatus_Pushed" 0 "PushButtonStatus_Neutral" ;
VAL_ 211 ResIncrBtnStat 3 "PushButtonStatus_NotAvailable" 2 "PushButtonStatus_Error" 1 "PushButtonStatus_Pushed" 0 "PushButtonStatus_Neutral" ;
VAL_ 211 SrcBtnStat 3 "PushButtonStatus_NotAvailable" 2 "PushButtonStatus_Error" 1 "PushButtonStatus_Pushed" 0 "PushButtonStatus_Neutral" ;
VAL_ 211 SW_Mute_ButtonStatus_6_ISig_5 3 "PushButtonStatus_NotAvailable" 2 "PushButtonStatus_Error" 1 "PushButtonStatus_Pushed" 0 "PushButtonStatus_Neutral" ;
VAL_ 211 SW_PushToTalk_BtnStat_6_ISig_5 3 "PushButtonStatus_NotAvailable" 2 "PushButtonStatus_Error" 1 "PushButtonStatus_Pushed" 0 "PushButtonStatus_Neutral" ;
VAL_ 211 SetDecrBtnStat 3 "PushButtonStatus_NotAvailable" 2 "PushButtonStatus_Error" 1 "PushButtonStatus_Pushed" 0 "PushButtonStatus_Neutral" ;
VAL_ 211 SW_Mute_ButtonStatus_6_3_ISig_5 3 "PushButtonStatus_NotAvailable" 2 "PushButtonStatus_Error" 1 "PushButtonStatus_Pushed" 0 "PushButtonStatus_Neutral" ;
VAL_ 211 MarkerInterruptButtonStatus 3 "PushButtonStatus_NotAvailable" 2 "PushButtonStatus_Error" 1 "PushButtonStatus_Pushed" 0 "PushButtonStatus_Neutral" ;
VAL_ 1337 TPMPosOfWMReq_VehiclePos_ISig_5 7 "TPMVehiclePos_NotAvailable" 6 "TPMVehiclePos_Error" 5 "TPMVehiclePos_Trailer5Vehicle" 4 "TPMVehiclePos_Trailer4Vehicle" 3 "TPMVehiclePos_Trailer3Vehicle" 2 "TPMVehiclePos_Trailer2Vehicle" 1 "TPMVehiclePos_Trailer1Vehicle" 0 "TPMVehiclePos_TruckVehicle" ;
VAL_ 1337 TPMSetAxleRefPres_VehiclePos_ISi 7 "TPMVehiclePos_NotAvailable" 6 "TPMVehiclePos_Error" 5 "TPMVehiclePos_Trailer5Vehicle" 4 "TPMVehiclePos_Trailer4Vehicle" 3 "TPMVehiclePos_Trailer3Vehicle" 2 "TPMVehiclePos_Trailer2Vehicle" 1 "TPMVehiclePos_Trailer1Vehicle" 0 "TPMVehiclePos_TruckVehicle" ;
VAL_ 1336 TPMSetPresThresCfg_VehiclePos_IS 7 "TPMVehiclePos_NotAvailable" 6 "TPMVehiclePos_Error" 5 "TPMVehiclePos_Trailer5Vehicle" 4 "TPMVehiclePos_Trailer4Vehicle" 3 "TPMVehiclePos_Trailer3Vehicle" 2 "TPMVehiclePos_Trailer2Vehicle" 1 "TPMVehiclePos_Trailer1Vehicle" 0 "TPMVehiclePos_TruckVehicle" ;
VAL_ 1336 TPMSetPresThresCfg_AxleNr_ISig_5 7 "TPMAxleNr_NotAvailable" 6 "TPMAxleNr_Error" 5 "TPMAxleNr_Axle5" 4 "TPMAxleNr_Axle4" 3 "TPMAxleNr_Axle3" 2 "TPMAxleNr_Axle2" 1 "TPMAxleNr_Axle1" 0 "TPMAxleNr_NoRequest" ;
VAL_ 163 Auto_ButtonStatus 3 "PushButtonStatus_NotAvailable" 2 "PushButtonStatus_Error" 1 "PushButtonStatus_Pushed" 0 "PushButtonStatus_Neutral" ;
VAL_ 163 AirBlowerSpeed_FreeWheelStatus 15 "FreeWheel_Status_NotAvailable" 14 "FreeWheel_Status_Error" 13 "FreeWheel_Status_Spare" 12 "FreeWheel_Status_6StepsCounterClockwise" 11 "FreeWheel_Status_5StepsCounterClockwise" 10 "FreeWheel_Status_4StepsCounterClockwise" 9 "FreeWheel_Status_3StepsCounterClockwise" 8 "FreeWheel_Status_2StepsCounterClockwise" 7 "FreeWheel_Status_1StepCounterClockwise" 6 "FreeWheel_Status_6StepsClockwise" 5 "FreeWheel_Status_5StepsClockwise" 4 "FreeWheel_Status_4StepsClockwise" 3 "FreeWheel_Status_3StepsClockwise" 2 "FreeWheel_Status_2StepsClockwise" 1 "FreeWheel_Status_1StepClockwise" 0 "FreeWheel_Status_NoMovement" ;
VAL_ 163 AirFlowSelectionDownBtn_stat 3 "PushButtonStatus_NotAvailable" 2 "PushButtonStatus_Error" 1 "PushButtonStatus_Pushed" 0 "PushButtonStatus_Neutral" ;
VAL_ 163 Temperature_FreeWheelStatus 15 "FreeWheel_Status_NotAvailable" 14 "FreeWheel_Status_Error" 13 "FreeWheel_Status_Spare" 12 "FreeWheel_Status_6StepsCounterClockwise" 11 "FreeWheel_Status_5StepsCounterClockwise" 10 "FreeWheel_Status_4StepsCounterClockwise" 9 "FreeWheel_Status_3StepsCounterClockwise" 8 "FreeWheel_Status_2StepsCounterClockwise" 7 "FreeWheel_Status_1StepCounterClockwise" 6 "FreeWheel_Status_6StepsClockwise" 5 "FreeWheel_Status_5StepsClockwise" 4 "FreeWheel_Status_4StepsClockwise" 3 "FreeWheel_Status_3StepsClockwise" 2 "FreeWheel_Status_2StepsClockwise" 1 "FreeWheel_Status_1StepClockwise" 0 "FreeWheel_Status_NoMovement" ;
VAL_ 163 AC_ButtonStatus 3 "PushButtonStatus_NotAvailable" 2 "PushButtonStatus_Error" 1 "PushButtonStatus_Pushed" 0 "PushButtonStatus_Neutral" ;
VAL_ 163 AirFlowSelectionUpBtn_stat 3 "PushButtonStatus_NotAvailable" 2 "PushButtonStatus_Error" 1 "PushButtonStatus_Pushed" 0 "PushButtonStatus_Neutral" ;
VAL_ 163 AirFlowSelectionFrontBtn_stat 3 "PushButtonStatus_NotAvailable" 2 "PushButtonStatus_Error" 1 "PushButtonStatus_Pushed" 0 "PushButtonStatus_Neutral" ;
VAL_ 163 ParkHeaterCooler_ButtonStatus 3 "PushButtonStatus_NotAvailable" 2 "PushButtonStatus_Error" 1 "PushButtonStatus_Pushed" 0 "PushButtonStatus_Neutral" ;
VAL_ 163 Recirc_ButtonStatus 3 "PushButtonStatus_NotAvailable" 2 "PushButtonStatus_Error" 1 "PushButtonStatus_Pushed" 0 "PushButtonStatus_Neutral" ;
VAL_ 163 WindscreenDefrost_ButtonStatus 3 "PushButtonStatus_NotAvailable" 2 "PushButtonStatus_Error" 1 "PushButtonStatus_Pushed" 0 "PushButtonStatus_Neutral" ;
VAL_ 405 ACmode_Status 7 "ACMode_NotAvailable" 6 "ACMode_Error" 5 "ACMode_Spare_01" 4 "ACMode_Spare" 3 "ACMode_ExtraDryCabAir" 2 "ACMode_HumidCabAir" 1 "ACMode_Standard" 0 "ACMode_Economy" ;
VAL_ 405 ACStatus 3 "OffOn_NotAvailable" 2 "OffOn_Error" 1 "OffOn_On" 0 "OffOn_Off" ;
VAL_ 405 ClimatePowerStatus 3 "OffOn_NotAvailable" 2 "OffOn_Error" 1 "OffOn_On" 0 "OffOn_Off" ;
VAL_ 405 ClimateAutoStatus 7 "ClimateAutoStatus_NotAvailable" 6 "ClimateAutoStatus_Error" 5 "ClimateAutoStatus_Spare3" 4 "ClimateAutoStatus_Spare2" 3 "ClimateAutoStatus_Spare1" 2 "ClimateAutoStatus_FullAuto" 1 "ClimateAutoStatus_SemiAuto" 0 "ClimateAutoStatus_AutoOffIndication" ;
VAL_ 405 AirRecirculationStatus 3 "OffOn_NotAvailable" 2 "OffOn_Error" 1 "OffOn_On" 0 "OffOn_Off" ;
VAL_ 405 AutoDefogmode_Status 7 "AutoDefogmode_NotAvailable" 6 "AutoDefogmode_Error" 5 "AutoDefogmode_Spare_01" 4 "AutoDefogmode_Spare" 3 "AutoDefogmode_Moderate" 2 "AutoDefogmode_Normal" 1 "AutoDefogmode_Sensitive" 0 "AutoDefogmode_OFF" ;
VAL_ 405 ClimateAirDistStatus_AutoStatus 3 "OffOn_NotAvailable" 2 "OffOn_Error" 1 "OffOn_On" 0 "OffOn_Off" ;
VAL_ 405 AutoBlowerLevel_Status 7 "AutoBlowerLevel_NotAvailable" 6 "AutoBlowerLevel_Error" 5 "AutoBlowerLevel_Spare_02" 4 "AutoBlowerLevel_Spare_01" 3 "AutoBlowerLevel_Spare" 2 "AutoBlowerLevel_Low" 1 "AutoBlowerLevel_Normal" 0 "AutoBlowerLevel_High" ;
VAL_ 405 AQSmode_Status 3 "AQSMode_NotAvailable" 2 "AQSMode_Error" 1 "AQSMode_Auto" 0 "AQSMode_OFF" ;
VAL_ 405 MaxDefrostStatus 3 "OffOn_NotAvailable" 2 "OffOn_Error" 1 "OffOn_On" 0 "OffOn_Off" ;
VAL_ 405 HVACBlowerLevelStat_AutoStatus 3 "OffOn_NotAvailable" 2 "OffOn_Error" 1 "OffOn_On" 0 "OffOn_Off" ;
VAL_ 912 ParkingClimateAvailability 7 "ParkingClimateAvail_NotAvailable" 6 "ParkingClimateAvail_Error" 5 "ParkingClimateAvail_Spare3" 4 "ParkingClimateAvail_Spare2" 3 "ParkingClimateAvail_SystemNotAvailDueTolowFuel" 2 "ParkingClimateAvail_SystemNotAvailDueToRolloversensor" 1 "ParkingClimateAvail_SystemNotAvailDueToParkingBrake" 0 "ParkingClimateAvail_SystemAvailable" ;
VAL_ 656 Req24VforClimateSystem 3 "NotRequested_NotAvailable" 2 "NotRequested_Error" 1 "NotRequested_Requested" 0 "NotRequested_NotRequested" ;
VAL_ 402 PHTimer2_stat_StartDay 15 "HeaterTimerStartDay_NotAvailable" 14 "HeaterTimerStartDay_Error" 13 "HeaterTimerStartDay_Spare_05" 12 "HeaterTimerStartDay_Spare_04" 11 "HeaterTimerStartDay_Spare_03" 10 "HeaterTimerStartDay_Spare_02" 9 "HeaterTimerStartDay_Spare_01" 8 "HeaterTimerStartDay_Spare" 7 "HeaterTimerStartDay_Sunday" 6 "HeaterTimerStartDay_Saturday" 5 "HeaterTimerStartDay_Friday" 4 "HeaterTimerStartDay_Thursday" 3 "HeaterTimerStartDay_Wednesday" 2 "HeaterTimerStartDay_Tuesday" 1 "HeaterTimerStartDay_Monday" 0 "HeaterTimerStartDay_NotUsed" ;
VAL_ 402 PHTimer2_stat_Recurrence 15 "HeaterTimerRecurrence_NotAvailable" 14 "HeaterTimerRecurrence_Error" 13 "HeaterTimerRecurrence_Spare_3" 12 "HeaterTimerRecurrence_Spare_2" 11 "HeaterTimerRecurrence_Spare_1" 10 "HeaterTimerRecurrence_Sundays" 9 "HeaterTimerRecurrence_Saturdays" 8 "HeaterTimerRecurrence_Fridays" 7 "HeaterTimerRecurrence_Thursdays" 6 "HeaterTimerRecurrence_Wednesdays" 5 "HeaterTimerRecurrence_Tuesdays" 4 "HeaterTimerRecurrence_Mondays" 3 "HeaterTimerRecurrence_Weekends" 2 "HeaterTimerRecurrence_AllWeekdays" 1 "HeaterTimerRecurrence_Daily" 0 "HeaterTimerRecurrence_None" ;
VAL_ 402 PHTimer3_stat_Temp 31 "TemperatureRqstIndication_cmd_NotAvailable" 30 "TemperatureRqstIndication_cmd_Error" 29 "TemperatureRqstIndication_cmd_Spare_01" 28 "TemperatureRqstIndication_cmd_Spare" 27 "TemperatureRqstIndication_cmd_Max" 26 "TemperatureRqstIndication_cmd_29C" 25 "TemperatureRqstIndication_cmd_28C" 24 "TemperatureRqstIndication_cmd_27C" 23 "TemperatureRqstIndication_cmd_26C" 22 "TemperatureRqstIndication_cmd_25_5C" 21 "TemperatureRqstIndication_cmd_25C" 20 "TemperatureRqstIndication_cmd_24_5C" 19 "TemperatureRqstIndication_cmd_24C" 18 "TemperatureRqstIndication_cmd_23_5C" 17 "TemperatureRqstIndication_cmd_23C" 16 "TemperatureRqstIndication_cmd_22_5C" 15 "TemperatureRqstIndication_cmd_22C" 14 "TemperatureRqstIndication_cmd_21_5C" 13 "TemperatureRqstIndication_cmd_21C" 12 "TemperatureRqstIndication_cmd_20_5C" 11 "TemperatureRqstIndication_cmd_20C" 10 "TemperatureRqstIndication_cmd_19_5C" 9 "TemperatureRqstIndication_cmd_19C" 8 "TemperatureRqstIndication_cmd_18_5C" 7 "TemperatureRqstIndication_cmd_18C" 6 "TemperatureRqstIndication_cmd_17_5C" 5 "TemperatureRqstIndication_cmd_17C" 4 "TemperatureRqstIndication_cmd_16_5C" 3 "TemperatureRqstIndication_cmd_16C" 2 "TemperatureRqstIndication_cmd_15C" 1 "TemperatureRqstIndication_cmd_Min" 0 "TemperatureRqstIndication_cmd_NoTempDisplayed" ;
VAL_ 402 PHTimer2_stat_Temp 31 "TemperatureRqstIndication_cmd_NotAvailable" 30 "TemperatureRqstIndication_cmd_Error" 29 "TemperatureRqstIndication_cmd_Spare_01" 28 "TemperatureRqstIndication_cmd_Spare" 27 "TemperatureRqstIndication_cmd_Max" 26 "TemperatureRqstIndication_cmd_29C" 25 "TemperatureRqstIndication_cmd_28C" 24 "TemperatureRqstIndication_cmd_27C" 23 "TemperatureRqstIndication_cmd_26C" 22 "TemperatureRqstIndication_cmd_25_5C" 21 "TemperatureRqstIndication_cmd_25C" 20 "TemperatureRqstIndication_cmd_24_5C" 19 "TemperatureRqstIndication_cmd_24C" 18 "TemperatureRqstIndication_cmd_23_5C" 17 "TemperatureRqstIndication_cmd_23C" 16 "TemperatureRqstIndication_cmd_22_5C" 15 "TemperatureRqstIndication_cmd_22C" 14 "TemperatureRqstIndication_cmd_21_5C" 13 "TemperatureRqstIndication_cmd_21C" 12 "TemperatureRqstIndication_cmd_20_5C" 11 "TemperatureRqstIndication_cmd_20C" 10 "TemperatureRqstIndication_cmd_19_5C" 9 "TemperatureRqstIndication_cmd_19C" 8 "TemperatureRqstIndication_cmd_18_5C" 7 "TemperatureRqstIndication_cmd_18C" 6 "TemperatureRqstIndication_cmd_17_5C" 5 "TemperatureRqstIndication_cmd_17C" 4 "TemperatureRqstIndication_cmd_16_5C" 3 "TemperatureRqstIndication_cmd_16C" 2 "TemperatureRqstIndication_cmd_15C" 1 "TemperatureRqstIndication_cmd_Min" 0 "TemperatureRqstIndication_cmd_NoTempDisplayed" ;
VAL_ 402 PHTimer3_stat_StartDay 15 "HeaterTimerStartDay_NotAvailable" 14 "HeaterTimerStartDay_Error" 13 "HeaterTimerStartDay_Spare_05" 12 "HeaterTimerStartDay_Spare_04" 11 "HeaterTimerStartDay_Spare_03" 10 "HeaterTimerStartDay_Spare_02" 9 "HeaterTimerStartDay_Spare_01" 8 "HeaterTimerStartDay_Spare" 7 "HeaterTimerStartDay_Sunday" 6 "HeaterTimerStartDay_Saturday" 5 "HeaterTimerStartDay_Friday" 4 "HeaterTimerStartDay_Thursday" 3 "HeaterTimerStartDay_Wednesday" 2 "HeaterTimerStartDay_Tuesday" 1 "HeaterTimerStartDay_Monday" 0 "HeaterTimerStartDay_NotUsed" ;
VAL_ 402 PHTimer3_stat_Recurrence 15 "HeaterTimerRecurrence_NotAvailable" 14 "HeaterTimerRecurrence_Error" 13 "HeaterTimerRecurrence_Spare_3" 12 "HeaterTimerRecurrence_Spare_2" 11 "HeaterTimerRecurrence_Spare_1" 10 "HeaterTimerRecurrence_Sundays" 9 "HeaterTimerRecurrence_Saturdays" 8 "HeaterTimerRecurrence_Fridays" 7 "HeaterTimerRecurrence_Thursdays" 6 "HeaterTimerRecurrence_Wednesdays" 5 "HeaterTimerRecurrence_Tuesdays" 4 "HeaterTimerRecurrence_Mondays" 3 "HeaterTimerRecurrence_Weekends" 2 "HeaterTimerRecurrence_AllWeekdays" 1 "HeaterTimerRecurrence_Daily" 0 "HeaterTimerRecurrence_None" ;
VAL_ 402 PHTimer2_stat_Status 3 "ParkHeaterTimer_Status_NotAvailable" 2 "ParkHeaterTimer_Status_TimerDeleted" 1 "ParkHeaterTimer_Status_TimerNotActivated" 0 "ParkHeaterTimer_Status_TimerActivated" ;
VAL_ 402 PHTimer3_stat_Status 3 "ParkHeaterTimer_Status_NotAvailable" 2 "ParkHeaterTimer_Status_TimerDeleted" 1 "ParkHeaterTimer_Status_TimerNotActivated" 0 "ParkHeaterTimer_Status_TimerActivated" ;
VAL_ 401 PHTimer1_stat_Recurrence 15 "HeaterTimerRecurrence_NotAvailable" 14 "HeaterTimerRecurrence_Error" 13 "HeaterTimerRecurrence_Spare_3" 12 "HeaterTimerRecurrence_Spare_2" 11 "HeaterTimerRecurrence_Spare_1" 10 "HeaterTimerRecurrence_Sundays" 9 "HeaterTimerRecurrence_Saturdays" 8 "HeaterTimerRecurrence_Fridays" 7 "HeaterTimerRecurrence_Thursdays" 6 "HeaterTimerRecurrence_Wednesdays" 5 "HeaterTimerRecurrence_Tuesdays" 4 "HeaterTimerRecurrence_Mondays" 3 "HeaterTimerRecurrence_Weekends" 2 "HeaterTimerRecurrence_AllWeekdays" 1 "HeaterTimerRecurrence_Daily" 0 "HeaterTimerRecurrence_None" ;
VAL_ 401 PHTimer1_stat_Temp 31 "TemperatureRqstIndication_cmd_NotAvailable" 30 "TemperatureRqstIndication_cmd_Error" 29 "TemperatureRqstIndication_cmd_Spare_01" 28 "TemperatureRqstIndication_cmd_Spare" 27 "TemperatureRqstIndication_cmd_Max" 26 "TemperatureRqstIndication_cmd_29C" 25 "TemperatureRqstIndication_cmd_28C" 24 "TemperatureRqstIndication_cmd_27C" 23 "TemperatureRqstIndication_cmd_26C" 22 "TemperatureRqstIndication_cmd_25_5C" 21 "TemperatureRqstIndication_cmd_25C" 20 "TemperatureRqstIndication_cmd_24_5C" 19 "TemperatureRqstIndication_cmd_24C" 18 "TemperatureRqstIndication_cmd_23_5C" 17 "TemperatureRqstIndication_cmd_23C" 16 "TemperatureRqstIndication_cmd_22_5C" 15 "TemperatureRqstIndication_cmd_22C" 14 "TemperatureRqstIndication_cmd_21_5C" 13 "TemperatureRqstIndication_cmd_21C" 12 "TemperatureRqstIndication_cmd_20_5C" 11 "TemperatureRqstIndication_cmd_20C" 10 "TemperatureRqstIndication_cmd_19_5C" 9 "TemperatureRqstIndication_cmd_19C" 8 "TemperatureRqstIndication_cmd_18_5C" 7 "TemperatureRqstIndication_cmd_18C" 6 "TemperatureRqstIndication_cmd_17_5C" 5 "TemperatureRqstIndication_cmd_17C" 4 "TemperatureRqstIndication_cmd_16_5C" 3 "TemperatureRqstIndication_cmd_16C" 2 "TemperatureRqstIndication_cmd_15C" 1 "TemperatureRqstIndication_cmd_Min" 0 "TemperatureRqstIndication_cmd_NoTempDisplayed" ;
VAL_ 401 PHTimer1_stat_Status 3 "ParkHeaterTimer_Status_NotAvailable" 2 "ParkHeaterTimer_Status_TimerDeleted" 1 "ParkHeaterTimer_Status_TimerNotActivated" 0 "ParkHeaterTimer_Status_TimerActivated" ;
VAL_ 401 PHTimer_rqst_SetAlarmOper 7 "SetAlarmOperation_NotAvailable" 6 "SetAlarmOperation_Error" 5 "SetAlarmOperation_Spare_02" 4 "SetAlarmOperation_Spare_01" 3 "SetAlarmOperation_Reset" 2 "SetAlarmOperation_Continue" 1 "SetAlarmOperation_Stop" 0 "SetAlarmOperation_Start" ;
VAL_ 401 PHTimer_rqst_DayOfWeekRq 15 "DayOfWeekRq_NotAvailable" 14 "DayOfWeekRq_Error" 13 "DayOfWeekRq_Spare_7" 12 "DayOfWeekRq_Spare_6" 11 "DayOfWeekRq_Spare_5" 10 "DayOfWeekRq_Spare_4" 9 "DayOfWeekRq_Spare_3" 8 "DayOfWeekRq_Spare_2" 7 "DayOfWeekRq_NoDay" 6 "DayOfWeekRq_Sunday" 5 "DayOfWeekRq_Saturday" 4 "DayOfWeekRq_Friday" 3 "DayOfWeekRq_Thursday" 2 "DayOfWeekRq_Wednesday" 1 "DayOfWeekRq_Tuesday" 0 "DayOfWeekRq_Monday" ;
VAL_ 401 PHTimer1_stat_StartDay 15 "HeaterTimerStartDay_NotAvailable" 14 "HeaterTimerStartDay_Error" 13 "HeaterTimerStartDay_Spare_05" 12 "HeaterTimerStartDay_Spare_04" 11 "HeaterTimerStartDay_Spare_03" 10 "HeaterTimerStartDay_Spare_02" 9 "HeaterTimerStartDay_Spare_01" 8 "HeaterTimerStartDay_Spare" 7 "HeaterTimerStartDay_Sunday" 6 "HeaterTimerStartDay_Saturday" 5 "HeaterTimerStartDay_Friday" 4 "HeaterTimerStartDay_Thursday" 3 "HeaterTimerStartDay_Wednesday" 2 "HeaterTimerStartDay_Tuesday" 1 "HeaterTimerStartDay_Monday" 0 "HeaterTimerStartDay_NotUsed" ;
VAL_ 400 WindscreenDefrostInd_cmd 1 "IndicationCmd_ONLEDActivated" 0 "IndicationCmd_OFFLEDNotActivated" ;
VAL_ 400 ParkingHeater_IndicationCmd 1 "IndicationCmd_ONLEDActivated" 0 "IndicationCmd_OFFLEDNotActivated" ;
VAL_ 400 AC_CompressorClutchCmd_ISig_5 3 "DisengageEngage_NotAvailable" 2 "DisengageEngage_Error" 1 "DisengageEngage_Engage" 0 "DisengageEngage_Disengage" ;
VAL_ 400 ParkingHeaterCleaning_Rqst 3 "Request_NotAvailable" 2 "Request_Error" 1 "Request_RequestActive" 0 "Request_NotRequested" ;
VAL_ 400 TemperatureRqstIndication_cmd 31 "TemperatureRqstIndication_cmd_NotAvailable" 30 "TemperatureRqstIndication_cmd_Error" 29 "TemperatureRqstIndication_cmd_Spare_01" 28 "TemperatureRqstIndication_cmd_Spare" 27 "TemperatureRqstIndication_cmd_Max" 26 "TemperatureRqstIndication_cmd_29C" 25 "TemperatureRqstIndication_cmd_28C" 24 "TemperatureRqstIndication_cmd_27C" 23 "TemperatureRqstIndication_cmd_26C" 22 "TemperatureRqstIndication_cmd_25_5C" 21 "TemperatureRqstIndication_cmd_25C" 20 "TemperatureRqstIndication_cmd_24_5C" 19 "TemperatureRqstIndication_cmd_24C" 18 "TemperatureRqstIndication_cmd_23_5C" 17 "TemperatureRqstIndication_cmd_23C" 16 "TemperatureRqstIndication_cmd_22_5C" 15 "TemperatureRqstIndication_cmd_22C" 14 "TemperatureRqstIndication_cmd_21_5C" 13 "TemperatureRqstIndication_cmd_21C" 12 "TemperatureRqstIndication_cmd_20_5C" 11 "TemperatureRqstIndication_cmd_20C" 10 "TemperatureRqstIndication_cmd_19_5C" 9 "TemperatureRqstIndication_cmd_19C" 8 "TemperatureRqstIndication_cmd_18_5C" 7 "TemperatureRqstIndication_cmd_18C" 6 "TemperatureRqstIndication_cmd_17_5C" 5 "TemperatureRqstIndication_cmd_17C" 4 "TemperatureRqstIndication_cmd_16_5C" 3 "TemperatureRqstIndication_cmd_16C" 2 "TemperatureRqstIndication_cmd_15C" 1 "TemperatureRqstIndication_cmd_Min" 0 "TemperatureRqstIndication_cmd_NoTempDisplayed" ;
VAL_ 400 ParkingClimate_IndicationCmd 7 "ParkingClimate_IndicationCmd_NotAvailable" 6 "ParkingClimate_IndicationCmd_Error" 5 "ParkingClimate_IndicationCmd_Spare_01" 4 "ParkingClimate_IndicationCmd_ShortStopHeaterActivated" 3 "ParkingClimate_IndicationCmd_ParkCoolWithoutCompActivReducedMode" 2 "ParkingClimate_IndicationCmd_ParkCoolWithCompActivFullMode" 1 "ParkingClimate_IndicationCmd_ParkingHeaterActivated" 0 "ParkingClimate_IndicationCmd_NoSystemActivated" ;
VAL_ 400 ACmode_IndicationCmd 1 "IndicationCmd_ONLEDActivated" 0 "IndicationCmd_OFFLEDNotActivated" ;
VAL_ 400 TempRqst_cmd 31 "TempRqst_cmd_NotAvailable" 30 "TempRqst_cmd_Error" 29 "TempRqst_cmd_Spare_02" 28 "TempRqst_cmd_Spare_01" 27 "TempRqst_cmd_Spare" 26 "TempRqst_cmd_30C" 25 "TempRqst_cmd_29C" 24 "TempRqst_cmd_28C" 23 "TempRqst_cmd_27C" 22 "TempRqst_cmd_26C" 21 "TempRqst_cmd_25_5C" 20 "TempRqst_cmd_25C" 19 "TempRqst_cmd_24_5C" 18 "TempRqst_cmd_24C" 17 "TempRqst_cmd_23_5C" 16 "TempRqst_cmd_23C" 15 "TempRqst_cmd_22_5C" 14 "TempRqst_cmd_22C" 13 "TempRqst_cmd_21_5C" 12 "TempRqst_cmd_21C" 11 "TempRqst_cmd_20_5C" 10 "TempRqst_cmd_20C" 9 "TempRqst_cmd_19_5C" 8 "TempRqst_cmd_19C" 7 "TempRqst_cmd_18_5C" 6 "TempRqst_cmd_18C" 5 "TempRqst_cmd_17_5C" 4 "TempRqst_cmd_17C" 3 "TempRqst_cmd_16_5C" 2 "TempRqst_cmd_16C" 1 "TempRqst_cmd_15C" 0 "TempRqst_cmd_14C" ;
VAL_ 400 ExtraHeating_status 3 "OffAuto_NotAvailable" 2 "OffAuto_Error" 1 "OffAuto_AutoStart" 0 "OffAuto_Off" ;
VAL_ 400 ShortStopHeater_cmd_ISig_5 3 "Request_NotAvailable" 2 "Request_Error" 1 "Request_RequestActive" 0 "Request_NotRequested" ;
SIG_GROUP_ 179 LevelRequest_sg_ISig_5 1 : LevelRequest_RollRequest_ISig_5 LevelRequest_RearAxle_ISig_5 LevelRequest_FrontAxle_ISig_5;
SIG_GROUP_ 419 ClimateAirDistRequest_sg 1 : ClimateAirDistRequest_Vent ClimateAirDistRequest_Floor ClimateAirDistRequest_Defrost;
SIG_GROUP_ 930 OBDRelDTC_IC_sg 1 : OBDRelDTC_IC_DrvngCycleB OBDRelDTC_IC_EvalResultA OBDRelDTC_IC_EvalResultB OBDRelDTC_IC_EvalStatA OBDRelDTC_IC_DtcIdB OBDRelDTC_IC_DrvngCycleA OBDRelDTC_IC_FailTB OBDRelDTC_IC_DtcIdA OBDRelDTC_IC_FailTA OBDRelDTC_IC_EvalStatB;
SIG_GROUP_ 784 SpeedAdaptEnableRqst_sg_ISig_5 1 : SpeedAdaptEnableRqst_SpeedLimit_ SpeedAdaptEnableRqst_SlowTraffic SpeedAdaptEnableRqst_Curve_ISig_;
SIG_GROUP_ 416 SSReq_sg 1 : SSReq_Repetition SSReq_Balance SSReq_Time SSReq_Id SSReq_Mixed SSReq_State SSReq_Volume;
SIG_GROUP_ 1337 TPMPosOfWMReq_sg_ISig_5 1 : TPMPosOfWMReq_VehiclePos_ISig_5 TPMPosOfWMReq_TireId_ISig_5;
SIG_GROUP_ 1337 TPMSetAxleRefPres_sg_ISig_5 1 : TPMSetAxleRefPres_Axle5_ISig_5 TPMSetAxleRefPres_Axle4_ISig_5 TPMSetAxleRefPres_VehiclePos_ISi TPMSetAxleRefPres_Axle1_ISig_5 TPMSetAxleRefPres_Axle3_ISig_5 TPMSetAxleRefPres_Axle2_ISig_5;
SIG_GROUP_ 1336 TPMSetPresThresCfg_sg_ISig_5 1 : TPMSetPresThresCfg_OverPres_ISig TPMSetPresThresCfg_VehiclePos_IS TPMSetPresThresCfg_AxleNr_ISig_5 TPMSetPresThresCfg_ExtUnderPres_ TPMSetPresThresCfg_ExtOverPres_I TPMSetPresThresCfg_UnderPres_ISi;
SIG_GROUP_ 1211 CabClimateFnRqst_sg 1 : CabClimateFnRqst_FnPower CabClimateFnRqst_FnNum;
SIG_GROUP_ 405 ClimateAirDistStatus_sg 1 : ClimateAirDistStatus_Defrost ClimateAirDistStatus_Vent ClimateAirDistStatus_AutoStatus ClimateAirDistStatus_Floor;
SIG_GROUP_ 405 HVACBlowerLevelStat_sg 1 : HVACBlowerLevelStat_BlowerLevel HVACBlowerLevelStat_AutoStatus;
SIG_GROUP_ 1168 DiagFaultStat_CCM_sg 1 : DiagFaultStat_CCM_FailTA DiagFaultStat_CCM_FailTB DiagFaultStat_CCM_DtcIdA DiagFaultStat_CCM_DtcIdB DiagFaultStat_CCM_EcuAdr;
SIG_GROUP_ 402 PHTimer2_stat_sg 1 : PHTimer2_stat_StartDay PHTimer2_stat_Recurrence PHTimer2_stat_Temp PHTimer2_stat_Hours PHTimer2_stat_Minutes PHTimer2_stat_Status;
SIG_GROUP_ 402 PHTimer3_stat_sg 1 : PHTimer3_stat_Minutes PHTimer3_stat_Temp PHTimer3_stat_StartDay PHTimer3_stat_Recurrence PHTimer3_stat_Status PHTimer3_stat_Hours;
SIG_GROUP_ 401 PHTimer1_stat_sg 1 : PHTimer1_stat_Recurrence PHTimer1_stat_Temp PHTimer1_stat_Duration PHTimer1_stat_Status PHTimer1_stat_Hours PHTimer1_stat_Minutes PHTimer1_stat_StartDay;
SIG_GROUP_ 401 PHTimer_rqst_sg 1 : PHTimer_rqst_Hours PHTimer_rqst_SetAlarmOper PHTimer_rqst_Minutes PHTimer_rqst_DayOfWeekRq;
